VERSION "dbc-export 1 2026.26.6.5"

NS_ :

BS_:

BU_: ADSP APB APP APS APSB BB BMS CC CMP CMPD CP DAS DI DIF DIR DPB EPAS3P EPAS3S EPASTP EPASTS EPBL EPBR ESP EVSE FC GTW HCML HCMR HVP IBST ICR IDB LS OCS1P ODIN PARK PCS PCS2 PLG PM PMF PMR PNCD PTC RADC RCM RCM2 RCM3 RCU SCCM SCM SCS SDCR TAS TCU TCU2 TPMS TRCM UDS UI UIS UMC USM V2G VC VCBATT VCBATT0 VCBATT1 VCBATT2 VCCC VCFRONT VCFRONT1 VCFRONT2 VCLEFT VCRIGHT VCSEAT2L VCSEAT2R VCSEC VEH

BO_ 974 VCBATT1_alertMatrix: 8 VCBATT1
 SG_ VCBATT1_matrixIndex M : 0|4@1+ (1,0) [0|15] "" Vector__XXX
 SG_ VCBATT1_a001_WatchdogReset m0 : 4|1@1+ (1,0) [0|1] "" Vector__XXX
 SG_ VCBATT1_a002_PowerLossReset m0 : 5|1@1+ (1,0) [0|1] "" Vector__XXX
 SG_ VCBATT1_a003_SWAssertion m0 : 6|1@1+ (1,0) [0|1] "" Vector__XXX
 SG_ VCBATT1_a005_CANTXError m0 : 8|1@1+ (1,0) [0|1] "" Vector__XXX
 SG_ VCBATT1_a006_CANTX_cyclicError m0 : 9|1@1+ (1,0) [0|1] "" Vector__XXX
 SG_ VCBATT1_a012_CPUReset m0 : 15|1@1+ (1,0) [0|1] "" Vector__XXX
 SG_ VCBATT1_a013_AlertManagerFault m0 : 16|1@1+ (1,0) [0|1] "" Vector__XXX
 SG_ VCBATT1_a015_NVMMError m0 : 18|1@1+ (1,0) [0|1] "" Vector__XXX
 SG_ VCBATT1_a016_NVMMRecordError m0 : 19|1@1+ (1,0) [0|1] "" Vector__XXX
 SG_ VCBATT1_a017_NVMMStatusDbg m0 : 20|1@1+ (1,0) [0|1] "" Vector__XXX
 SG_ VCBATT1_a018_HardFault m0 : 21|1@1+ (1,0) [0|1] "" Vector__XXX
 SG_ VCBATT1_a019_BusFault m0 : 22|1@1+ (1,0) [0|1] "" Vector__XXX
 SG_ VCBATT1_a021_TaskSchedulerError m0 : 24|1@1+ (1,0) [0|1] "" Vector__XXX
 SG_ VCBATT1_a022_TaskInitError m0 : 25|1@1+ (1,0) [0|1] "" Vector__XXX
 SG_ VCBATT1_a028_UsageFault m0 : 31|1@1+ (1,0) [0|1] "" Vector__XXX
 SG_ VCBATT1_a029_CoreDump m0 : 32|1@1+ (1,0) [0|1] "" Vector__XXX
 SG_ VCBATT1_a030_ECULogUploadRequest m0 : 33|1@1+ (1,0) [0|1] "" Vector__XXX
 SG_ VCBATT1_a031_UDSActive m0 : 34|1@1+ (1,0) [0|1] "" Vector__XXX
 SG_ VCBATT1_a036_UnknownIrq m0 : 39|1@1+ (1,0) [0|1] "" Vector__XXX
 SG_ VCBATT1_a037_MemManageFault m0 : 40|1@1+ (1,0) [0|1] "" Vector__XXX
 SG_ VCBATT1_a038_ProtFaultInfo m0 : 41|1@1+ (1,0) [0|1] "" Vector__XXX
 SG_ VCBATT1_a039_ProtFaultAddress m0 : 42|1@1+ (1,0) [0|1] "" Vector__XXX
 SG_ VCBATT1_a040_Backtrace m0 : 43|1@1+ (1,0) [0|1] "" Vector__XXX
 SG_ VCBATT1_a041_HighCPULoad m0 : 44|1@1+ (1,0) [0|1] "" Vector__XXX
 SG_ VCBATT1_a042_HighStackUsage m0 : 45|1@1+ (1,0) [0|1] "" Vector__XXX
 SG_ VCBATT1_a043_Task1msError m0 : 46|1@1+ (1,0) [0|1] "" Vector__XXX
 SG_ VCBATT1_a044_Task10msError m0 : 47|1@1+ (1,0) [0|1] "" Vector__XXX
 SG_ VCBATT1_a045_Task100msError m0 : 48|1@1+ (1,0) [0|1] "" Vector__XXX
 SG_ VCBATT1_a046_Task1000msError m0 : 49|1@1+ (1,0) [0|1] "" Vector__XXX
 SG_ VCBATT1_a058_inputRHighSyncDebug m0 : 61|1@1+ (1,0) [0|1] "" Vector__XXX
 SG_ VCBATT1_a059_inputResistanceHigh m0 : 62|1@1+ (1,0) [0|1] "" Vector__XXX
 SG_ VCBATT1_a060_engineeringBuild m0 : 63|1@1+ (1,0) [0|1] "" Vector__XXX
 SG_ VCBATT1_a061_XCPConnected m1 : 4|1@1+ (1,0) [0|1] "" Vector__XXX
 SG_ VCBATT1_a062_XCPWasConnected m1 : 5|1@1+ (1,0) [0|1] "" Vector__XXX
 SG_ VCBATT1_a063_SwitchFault m1 : 6|1@1+ (1,0) [0|1] "" Vector__XXX
 SG_ VCBATT1_a064_busSleepReqTimeout m1 : 7|1@1+ (1,0) [0|1] "" Vector__XXX
 SG_ VCBATT1_a077_VCBATT0_MIA m1 : 20|1@1+ (1,0) [0|1] "" Vector__XXX
 SG_ VCBATT1_a078_VCBATT1_MIA m1 : 21|1@1+ (1,0) [0|1] "" Vector__XXX
 SG_ VCBATT1_a079_VCBATT2_MIA m1 : 22|1@1+ (1,0) [0|1] "" Vector__XXX
 SG_ VCBATT1_a080_VCFRONT0_MIA m1 : 23|1@1+ (1,0) [0|1] "" Vector__XXX
 SG_ VCBATT1_a081_VCFRONT1_MIA m1 : 24|1@1+ (1,0) [0|1] "" Vector__XXX
 SG_ VCBATT1_a082_VCFRONT2_MIA m1 : 25|1@1+ (1,0) [0|1] "" Vector__XXX
 SG_ VCBATT1_a086_VCBATT_MIA m1 : 29|1@1+ (1,0) [0|1] "" Vector__XXX
 SG_ VCBATT1_a090_APS_MIA m1 : 33|1@1+ (1,0) [0|1] "" Vector__XXX
 SG_ VCBATT1_a091_CMPD_MIA m1 : 34|1@1+ (1,0) [0|1] "" Vector__XXX
 SG_ VCBATT1_a096_OCS1P_MIA m1 : 39|1@1+ (1,0) [0|1] "" Vector__XXX
 SG_ VCBATT1_a098_DIR_MIA m1 : 41|1@1+ (1,0) [0|1] "" Vector__XXX
 SG_ VCBATT1_a100_CANbus_MIA m1 : 43|1@1+ (1,0) [0|1] "" Vector__XXX
 SG_ VCBATT1_a103_CP_MIA m1 : 46|1@1+ (1,0) [0|1] "" Vector__XXX
 SG_ VCBATT1_a104_DAS_MIA m1 : 47|1@1+ (1,0) [0|1] "" Vector__XXX
 SG_ VCBATT1_a105_TAS_MIA m1 : 48|1@1+ (1,0) [0|1] "" Vector__XXX
 SG_ VCBATT1_a106_PCS_MIA m1 : 49|1@1+ (1,0) [0|1] "" Vector__XXX
 SG_ VCBATT1_a107_BMS_MIA m1 : 50|1@1+ (1,0) [0|1] "" Vector__XXX
 SG_ VCBATT1_a108_DIF_MIA m1 : 51|1@1+ (1,0) [0|1] "" Vector__XXX
 SG_ VCBATT1_a109_RCM_MIA m1 : 52|1@1+ (1,0) [0|1] "" Vector__XXX
 SG_ VCBATT1_a110_GTW_MIA m1 : 53|1@1+ (1,0) [0|1] "" Vector__XXX
 SG_ VCBATT1_a111_EPBR_MIA m1 : 54|1@1+ (1,0) [0|1] "" Vector__XXX
 SG_ VCBATT1_a112_EPBL_MIA m1 : 55|1@1+ (1,0) [0|1] "" Vector__XXX
 SG_ VCBATT1_a113_UI_MIA m1 : 56|1@1+ (1,0) [0|1] "" Vector__XXX
 SG_ VCBATT1_a114_ESP_MIA m1 : 57|1@1+ (1,0) [0|1] "" Vector__XXX
 SG_ VCBATT1_a115_VCSEC_MIA m1 : 58|1@1+ (1,0) [0|1] "" Vector__XXX
 SG_ VCBATT1_a116_VCRIGHT_MIA m1 : 59|1@1+ (1,0) [0|1] "" Vector__XXX
 SG_ VCBATT1_a117_VCLEFT_MIA m1 : 60|1@1+ (1,0) [0|1] "" Vector__XXX
 SG_ VCBATT1_a118_VCFRONT_MIA m1 : 61|1@1+ (1,0) [0|1] "" Vector__XXX
 SG_ VCBATT1_a119_SCCM_MIA m1 : 62|1@1+ (1,0) [0|1] "" Vector__XXX
 SG_ VCBATT1_a120_DI_DRIVE_MIA m1 : 63|1@1+ (1,0) [0|1] "" Vector__XXX
 SG_ VCBATT1_a122_ICR_MIA m2 : 5|1@1+ (1,0) [0|1] "" Vector__XXX
 SG_ VCBATT1_a124_BB_MIA m2 : 7|1@1+ (1,0) [0|1] "" Vector__XXX
 SG_ VCBATT1_a125_SCCM_MIA m2 : 8|1@1+ (1,0) [0|1] "" Vector__XXX
 SG_ VCBATT1_a126_EPAS3P_MIA m2 : 9|1@1+ (1,0) [0|1] "" Vector__XXX
 SG_ VCBATT1_a127_vcleftEFuseTrip m2 : 10|1@1+ (1,0) [0|1] "" Vector__XXX
 SG_ VCBATT1_a129_epas1EFuseTrip m2 : 12|1@1+ (1,0) [0|1] "" Vector__XXX
 SG_ VCBATT1_a130_autopilot1EFuseTrip m2 : 13|1@1+ (1,0) [0|1] "" Vector__XXX
 SG_ VCBATT1_a131_PCSCOMMON_MIA m2 : 14|1@1+ (1,0) [0|1] "" Vector__XXX
 SG_ VCBATT1_a132_iBoosterEFuseTrip m2 : 15|1@1+ (1,0) [0|1] "" Vector__XXX
 SG_ VCBATT1_a133_BRAKE_MIA m2 : 16|1@1+ (1,0) [0|1] "" Vector__XXX
 SG_ VCBATT1_a134_hvContactorsEFuseTr m2 : 17|1@1+ (1,0) [0|1] "" Vector__XXX
 SG_ VCBATT1_a144_EPAS3S_MIA m2 : 27|1@1+ (1,0) [0|1] "" Vector__XXX
 SG_ VCBATT1_a164_eFuseLckoutMissing m2 : 47|1@1+ (1,0) [0|1] "" Vector__XXX
 SG_ VCBATT1_a165_unxpctdEFuseLckout m2 : 48|1@1+ (1,0) [0|1] "" Vector__XXX
 SG_ VCBATT1_a180_DCDCNotSupportingLV m2 : 63|1@1+ (1,0) [0|1] "" Vector__XXX
 SG_ VCBATT1_a182_replaceLVBattery m3 : 5|1@1+ (1,0) [0|1] "" Vector__XXX
 SG_ VCBATT1_a183_replaceLVBattery2 m3 : 6|1@1+ (1,0) [0|1] "" Vector__XXX
 SG_ VCBATT1_a188_sleepFailed m3 : 11|1@1+ (1,0) [0|1] "" Vector__XXX
 SG_ VCBATT1_a189_IBSMIA m3 : 12|1@1+ (1,0) [0|1] "" Vector__XXX
 SG_ VCBATT1_a191_exitDriveLowLVBusVo m3 : 14|1@1+ (1,0) [0|1] "" Vector__XXX
 SG_ VCBATT1_a196_discnctdLVBattery m3 : 19|1@1+ (1,0) [0|1] "" Vector__XXX
 SG_ VCBATT1_a204_undervoltageLoadshe m3 : 27|1@1+ (1,0) [0|1] "" Vector__XXX
 SG_ VCBATT1_a205_overvoltageProtecti m3 : 28|1@1+ (1,0) [0|1] "" Vector__XXX
 SG_ VCBATT1_a212_IBSOverTemp m3 : 35|1@1+ (1,0) [0|1] "" Vector__XXX
 SG_ VCBATT1_a213_LVOvercharge m3 : 36|1@1+ (1,0) [0|1] "" Vector__XXX
 SG_ VCBATT1_a215_selfTestOrchestrato m3 : 38|1@1+ (1,0) [0|1] "" Vector__XXX
 SG_ VCBATT1_a216_powerCutoffImminent m3 : 39|1@1+ (1,0) [0|1] "" Vector__XXX
 SG_ VCBATT1_a217_LVProtectionSelfTes m3 : 40|1@1+ (1,0) [0|1] "" Vector__XXX
 SG_ VCBATT1_a219_LVVoltFloorRchd m3 : 42|1@1+ (1,0) [0|1] "" Vector__XXX
 SG_ VCBATT1_a220_LVUnhealthy m3 : 43|1@1+ (1,0) [0|1] "" Vector__XXX
 SG_ VCBATT1_a221_reverseBatteryFault m3 : 44|1@1+ (1,0) [0|1] "" Vector__XXX
 SG_ VCBATT1_a223_bridgeOvervoltageSe m3 : 46|1@1+ (1,0) [0|1] "" Vector__XXX
 SG_ VCBATT1_a224_overcurrentLoadshed m3 : 47|1@1+ (1,0) [0|1] "" Vector__XXX
 SG_ VCBATT1_a225_overcurrentSelfTest m3 : 48|1@1+ (1,0) [0|1] "" Vector__XXX
 SG_ VCBATT1_a226_overcurrentSelfTest m3 : 49|1@1+ (1,0) [0|1] "" Vector__XXX
 SG_ VCBATT1_a227_overcurrentSelfTest m3 : 50|1@1+ (1,0) [0|1] "" Vector__XXX
 SG_ VCBATT1_a228_overcurrentSelfTest m3 : 51|1@1+ (1,0) [0|1] "" Vector__XXX
 SG_ VCBATT1_a229_LVHealthCompromised m3 : 52|1@1+ (1,0) [0|1] "" Vector__XXX
 SG_ VCBATT1_a230_ingoingOvercurrentS m3 : 53|1@1+ (1,0) [0|1] "" Vector__XXX
 SG_ VCBATT1_a231_autopilot1EFuseTrip m3 : 54|1@1+ (1,0) [0|1] "" Vector__XXX
 SG_ VCBATT1_a235_dualPowerLoadsSelfT m3 : 58|1@1+ (1,0) [0|1] "" Vector__XXX
 SG_ VCBATT1_a236_hvcDualPowerSelfTes m3 : 59|1@1+ (1,0) [0|1] "" Vector__XXX
 SG_ VCBATT1_a243_LVOverchargeInstc m4 : 6|1@1+ (1,0) [0|1] "" Vector__XXX
 SG_ VCBATT1_a244_brakeValveECUEFuseT m4 : 7|1@1+ (1,0) [0|1] "" Vector__XXX
 SG_ VCBATT1_a245_sleepBypassFault m4 : 8|1@1+ (1,0) [0|1] "" Vector__XXX
 SG_ VCBATT1_a252_controllerWakeup m4 : 15|1@1+ (1,0) [0|1] "" Vector__XXX
 SG_ VCBATT1_a253_maxChrgeSssionTmeou m4 : 16|1@1+ (1,0) [0|1] "" Vector__XXX
 SG_ VCBATT1_a256_nxppca9539Fault m4 : 19|1@1+ (1,0) [0|1] "" Vector__XXX
 SG_ VCBATT1_a258_resistanceEstimatio m4 : 21|1@1+ (1,0) [0|1] "" Vector__XXX
 SG_ VCBATT1_a259_LVVoltageDropOnHigh m4 : 22|1@1+ (1,0) [0|1] "" Vector__XXX
 SG_ VCBATT1_a260_deadLVBattery m4 : 23|1@1+ (1,0) [0|1] "" Vector__XXX
 SG_ VCBATT1_a275_TLVBMS_BmbCommunica m4 : 38|1@1+ (1,0) [0|1] "" Vector__XXX
 SG_ VCBATT1_a276_TLVBMS_BmbDataInteg m4 : 39|1@1+ (1,0) [0|1] "" Vector__XXX
 SG_ VCBATT1_a277_TLVBMS_BmbStatusReg m4 : 40|1@1+ (1,0) [0|1] "" Vector__XXX
 SG_ VCBATT1_a278_TLVBMS_BmbHwOverCur m4 : 41|1@1+ (1,0) [0|1] "" Vector__XXX
 SG_ VCBATT1_a297_TLVBMS_BmbHwOverTem m4 : 60|1@1+ (1,0) [0|1] "" Vector__XXX
 SG_ VCBATT1_a359_postPORExcessiveAh m5 : 62|1@1+ (1,0) [0|1] "" Vector__XXX
 SG_ VCBATT1_a362_TLVBMS_AllSocCorrec m6 : 5|1@1+ (1,0) [0|1] "" Vector__XXX
 SG_ VCBATT1_a363_TLVBMS_BleedBasedWe m6 : 6|1@1+ (1,0) [0|1] "" Vector__XXX
 SG_ VCBATT1_a370_noLVSupportSocTooLo m6 : 13|1@1+ (1,0) [0|1] "" Vector__XXX
 SG_ VCBATT1_a371_failureToPrechargeR m6 : 14|1@1+ (1,0) [0|1] "" Vector__XXX
 SG_ VCBATT1_a372_TLVBMS_BmbHwOverVol m6 : 15|1@1+ (1,0) [0|1] "" Vector__XXX
 SG_ VCBATT1_a376_controllerWakeupDeb m6 : 19|1@1+ (1,0) [0|1] "" Vector__XXX
 SG_ VCBATT1_a379_shortedCellTestRunD m6 : 22|1@1+ (1,0) [0|1] "" Vector__XXX
 SG_ VCBATT1_a387_shortedCellInstc m6 : 30|1@1+ (1,0) [0|1] "" Vector__XXX
 SG_ VCBATT1_a388_shortedCell m6 : 31|1@1+ (1,0) [0|1] "" Vector__XXX
 SG_ VCBATT1_a392_TLVBMS_BmbHwUnderVo m6 : 35|1@1+ (1,0) [0|1] "" Vector__XXX
 SG_ VCBATT1_a400_TLVBMS_BmbVrefBad m6 : 43|1@1+ (1,0) [0|1] "" Vector__XXX
 SG_ VCBATT1_a401_deadLVMinimalAhDisc m6 : 44|1@1+ (1,0) [0|1] "" Vector__XXX
 SG_ VCBATT1_a402_LVBatteryCannotSupp m6 : 45|1@1+ (1,0) [0|1] "" Vector__XXX
 SG_ VCBATT1_a403_chargeExitHardCurre m6 : 46|1@1+ (1,0) [0|1] "" Vector__XXX
 SG_ VCBATT1_a404_resistanceEstimatio m6 : 47|1@1+ (1,0) [0|1] "" Vector__XXX
 SG_ VCBATT1_a405_dcrData1 m6 : 48|1@1+ (1,0) [0|1] "" Vector__XXX
 SG_ VCBATT1_a406_dcrData2 m6 : 49|1@1+ (1,0) [0|1] "" Vector__XXX
 SG_ VCBATT1_a407_dcrMilliOhmsAboveTh m6 : 50|1@1+ (1,0) [0|1] "" Vector__XXX
 SG_ VCBATT1_a408_standbyChargeProfil m6 : 51|1@1+ (1,0) [0|1] "" Vector__XXX
 SG_ VCBATT1_a410_LVBatteryDataCollec m6 : 53|1@1+ (1,0) [0|1] "" Vector__XXX
 SG_ VCBATT1_a411_LVBatteryDataCollec m6 : 54|1@1+ (1,0) [0|1] "" Vector__XXX
 SG_ VCBATT1_a412_dcrData3 m6 : 55|1@1+ (1,0) [0|1] "" Vector__XXX
 SG_ VCBATT1_a413_TLVBMS_BmbVrefWarni m6 : 56|1@1+ (1,0) [0|1] "" Vector__XXX
 SG_ VCBATT1_a414_undervoltageSelfTes m6 : 57|1@1+ (1,0) [0|1] "" Vector__XXX
 SG_ VCBATT1_a415_undervoltageSelfTes m6 : 58|1@1+ (1,0) [0|1] "" Vector__XXX
 SG_ VCBATT1_a416_TLVBMS_BrickOverDis m6 : 59|1@1+ (1,0) [0|1] "" Vector__XXX
 SG_ VCBATT1_a417_TLVBMS_BrickOverVol m6 : 60|1@1+ (1,0) [0|1] "" Vector__XXX
 SG_ VCBATT1_a418_TLVBMS_BrickOverVol m6 : 61|1@1+ (1,0) [0|1] "" Vector__XXX
 SG_ VCBATT1_a419_TLVBMS_BrickSocLow m6 : 62|1@1+ (1,0) [0|1] "" Vector__XXX
 SG_ VCBATT1_a421_LVBatteryHealthTest m7 : 4|1@1+ (1,0) [0|1] "" Vector__XXX
 SG_ VCBATT1_a422_rtosSleepFailed m7 : 5|1@1+ (1,0) [0|1] "" Vector__XXX
 SG_ VCBATT1_a423_TLVBMS_BrickUnderVo m7 : 6|1@1+ (1,0) [0|1] "" Vector__XXX
 SG_ VCBATT1_a424_TLVBMS_BrickUnderVo m7 : 7|1@1+ (1,0) [0|1] "" Vector__XXX
 SG_ VCBATT1_a425_TLVBMS_BusVoltageTo m7 : 8|1@1+ (1,0) [0|1] "" Vector__XXX
 SG_ VCBATT1_a426_TLVBMS_BusVoltageTo m7 : 9|1@1+ (1,0) [0|1] "" Vector__XXX
 SG_ VCBATT1_a427_TLVBMS_CacChange m7 : 10|1@1+ (1,0) [0|1] "" Vector__XXX
 SG_ VCBATT1_a428_TLVBMS_CacImbalance m7 : 11|1@1+ (1,0) [0|1] "" Vector__XXX
 SG_ VCBATT1_a429_TLVBMS_CapacityTest m7 : 12|1@1+ (1,0) [0|1] "" Vector__XXX
 SG_ VCBATT1_a430_TLVBMS_ChargeCurren m7 : 13|1@1+ (1,0) [0|1] "" Vector__XXX
 SG_ VCBATT1_a431_TLVBMS_ChargeOverCu m7 : 14|1@1+ (1,0) [0|1] "" Vector__XXX
 SG_ VCBATT1_a432_TLVBMS_ChargeRegula m7 : 15|1@1+ (1,0) [0|1] "" Vector__XXX
 SG_ VCBATT1_a433_TLVBMS_ConfigFromBm m7 : 16|1@1+ (1,0) [0|1] "" Vector__XXX
 SG_ VCBATT1_a434_TLVBMS_ConfigInitFa m7 : 17|1@1+ (1,0) [0|1] "" Vector__XXX
 SG_ VCBATT1_a435_TLVBMS_DchgCurrentL m7 : 18|1@1+ (1,0) [0|1] "" Vector__XXX
 SG_ VCBATT1_a436_TLVBMS_DischargeOve m7 : 19|1@1+ (1,0) [0|1] "" Vector__XXX
 SG_ VCBATT1_a437_TLVBMS_NvmRegistrat m7 : 20|1@1+ (1,0) [0|1] "" Vector__XXX
 SG_ VCBATT1_a438_TLVBMS_PackOverTemp m7 : 21|1@1+ (1,0) [0|1] "" Vector__XXX
 SG_ VCBATT1_a439_TLVBMS_PackOverTemp m7 : 22|1@1+ (1,0) [0|1] "" Vector__XXX
 SG_ VCBATT1_a440_TLVBMS_PackSNInvali m7 : 23|1@1+ (1,0) [0|1] "" Vector__XXX
 SG_ VCBATT1_a441_TLVBMS_ResetNeededF m7 : 24|1@1+ (1,0) [0|1] "" Vector__XXX
 SG_ VCBATT1_a442_TLVBMS_SocChange m7 : 25|1@1+ (1,0) [0|1] "" Vector__XXX
 SG_ VCBATT1_a443_TLVBMS_BmbDieOverTe m7 : 26|1@1+ (1,0) [0|1] "" Vector__XXX
 SG_ VCBATT1_a446_LVBatteryUnrecovera m7 : 29|1@1+ (1,0) [0|1] "" Vector__XXX
 SG_ VCBATT1_a450_doorWakeToOpenDBG m7 : 33|1@1+ (1,0) [0|1] "" Vector__XXX
 SG_ VCBATT1_a461_TLVBMS_SocHighAhErr m7 : 44|1@1+ (1,0) [0|1] "" Vector__XXX
 SG_ VCBATT1_a462_LVBMSFault m7 : 45|1@1+ (1,0) [0|1] "" Vector__XXX
 SG_ VCBATT1_a475_vnf1248Fault m7 : 58|1@1+ (1,0) [0|1] "" Vector__XXX
 SG_ VCBATT1_a476_LVBMSMIA m7 : 59|1@1+ (1,0) [0|1] "" Vector__XXX
 SG_ VCBATT1_a477_LVBatteryUnrecovera m7 : 60|1@1+ (1,0) [0|1] "" Vector__XXX
 SG_ VCBATT1_a478_LVBMS_MOSFET_Open m7 : 61|1@1+ (1,0) [0|1] "" Vector__XXX
 SG_ VCBATT1_a479_LVBMS_ECPA_NotClose m7 : 62|1@1+ (1,0) [0|1] "" Vector__XXX
 SG_ VCBATT1_a480_vnf1048Fault m7 : 63|1@1+ (1,0) [0|1] "" Vector__XXX
 SG_ VCBATT1_a481_LVBridgeCloseDBG m8 : 4|1@1+ (1,0) [0|1] "" Vector__XXX
 SG_ VCBATT1_a482_lvBridgeEFuseTrip m8 : 5|1@1+ (1,0) [0|1] "" Vector__XXX
 SG_ VCBATT1_a483_vnf1048SelfTestFail m8 : 6|1@1+ (1,0) [0|1] "" Vector__XXX
 SG_ VCBATT1_a484_undervoltageSelfTes m8 : 7|1@1+ (1,0) [0|1] "" Vector__XXX
 SG_ VCBATT1_a485_uvSelfTestLoadUnatt m8 : 8|1@1+ (1,0) [0|1] "" Vector__XXX
 SG_ VCBATT1_a486_undervoltageSelfTes m8 : 9|1@1+ (1,0) [0|1] "" Vector__XXX
 SG_ VCBATT1_a489_vnf1248SelfTestDebu m8 : 12|1@1+ (1,0) [0|1] "" Vector__XXX
 SG_ VCBATT1_a490_vnf1248SelfTestFail m8 : 13|1@1+ (1,0) [0|1] "" Vector__XXX
 SG_ VCBATT1_a491_vnf1248Configuratio m8 : 14|1@1+ (1,0) [0|1] "" Vector__XXX
 SG_ VCBATT1_a492_TLVBMS_SocImbalance m8 : 15|1@1+ (1,0) [0|1] "" Vector__XXX
 SG_ VCBATT1_a493_TLVBMS_SocImbalance m8 : 16|1@1+ (1,0) [0|1] "" Vector__XXX
 SG_ VCBATT1_a494_LVBatteryTempBlocki m8 : 17|1@1+ (1,0) [0|1] "" Vector__XXX
 SG_ VCBATT1_a495_LVBatteryRecoveryBl m8 : 18|1@1+ (1,0) [0|1] "" Vector__XXX
 SG_ VCBATT1_a496_LVBatteryExitDriveW m8 : 19|1@1+ (1,0) [0|1] "" Vector__XXX
 SG_ VCBATT1_a497_LVBatteryWarnDiscon m8 : 20|1@1+ (1,0) [0|1] "" Vector__XXX
 SG_ VCBATT1_a498_TLVBMS_ImpedanceTes m8 : 21|1@1+ (1,0) [0|1] "" Vector__XXX
 SG_ VCBATT1_a500_eFuseASICStateMisma m8 : 23|1@1+ (1,0) [0|1] "" Vector__XXX
 SG_ VCBATT1_a501_vnf1048Configuratio m8 : 24|1@1+ (1,0) [0|1] "" Vector__XXX
 SG_ VCBATT1_a502_TLVBMS_WeakShortImp m8 : 25|1@1+ (1,0) [0|1] "" Vector__XXX
 SG_ VCBATT1_a503_TLVBMS_BrickExtende m8 : 26|1@1+ (1,0) [0|1] "" Vector__XXX
 SG_ VCBATT1_a508_TLVBMS_ImpedanceGro m8 : 31|1@1+ (1,0) [0|1] "" Vector__XXX
 SG_ VCBATT1_a509_eFuseASICManagerSta m8 : 32|1@1+ (1,0) [0|1] "" Vector__XXX
 SG_ VCBATT1_a510_LVBatteryRecoveryTi m8 : 33|1@1+ (1,0) [0|1] "" Vector__XXX
 SG_ VCBATT1_a512_LVBMSFault_MOS_Open m8 : 35|1@1+ (1,0) [0|1] "" Vector__XXX
 SG_ VCBATT1_a513_LVBMSFault_MOS_Open m8 : 36|1@1+ (1,0) [0|1] "" Vector__XXX
 SG_ VCBATT1_a514_LVBMSFault_MOS_Open m8 : 37|1@1+ (1,0) [0|1] "" Vector__XXX
 SG_ VCBATT1_a515_LVBMSFault_MOS_Open m8 : 38|1@1+ (1,0) [0|1] "" Vector__XXX
 SG_ VCBATT1_a518_LVBMSFault_MOS_Open m8 : 41|1@1+ (1,0) [0|1] "" Vector__XXX
 SG_ VCBATT1_a521_vcleftEFuseLoadShed m8 : 44|1@1+ (1,0) [0|1] "" Vector__XXX
 SG_ VCBATT1_a523_eFuseThresholdsInco m8 : 46|1@1+ (1,0) [0|1] "" Vector__XXX
 SG_ VCBATT1_a525_LVBatterySWMisconfi m8 : 48|1@1+ (1,0) [0|1] "" Vector__XXX
 SG_ VCBATT1_a527_LVBatteryCellImbala m8 : 50|1@1+ (1,0) [0|1] "" Vector__XXX
 SG_ VCBATT1_a528_LVBatteryCommsDiscn m8 : 51|1@1+ (1,0) [0|1] "" Vector__XXX
 SG_ VCBATT1_a529_discnctdBatteryStat m8 : 52|1@1+ (1,0) [0|1] "" Vector__XXX
 SG_ VCBATT1_a533_TLVBMS_MosfetOverTe m8 : 56|1@1+ (1,0) [0|1] "" Vector__XXX
 SG_ VCBATT1_a541_LVBatteryChargeOCLe m9 : 4|1@1+ (1,0) [0|1] "" Vector__XXX
 SG_ VCBATT1_a544_LVBatteryCommsBusTu m9 : 7|1@1+ (1,0) [0|1] "" Vector__XXX
 SG_ VCBATT1_a545_LVBatteryTypeUnknow m9 : 8|1@1+ (1,0) [0|1] "" Vector__XXX
 SG_ VCBATT1_a548_HVFaultLoadShed m9 : 11|1@1+ (1,0) [0|1] "" Vector__XXX
 SG_ VCBATT1_a555_LVBatteryCellRebala m9 : 18|1@1+ (1,0) [0|1] "" Vector__XXX
 SG_ VCBATT1_a556_falseTriggerOfDiscn m9 : 19|1@1+ (1,0) [0|1] "" Vector__XXX
 SG_ VCBATT1_a559_LVBatteryLowSOC m9 : 22|1@1+ (1,0) [0|1] "" Vector__XXX
 SG_ VCBATT1_a561_LVBMSEFuseOvertempe m9 : 24|1@1+ (1,0) [0|1] "" Vector__XXX
 SG_ VCBATT1_a562_LVBMSModuleOvertemp m9 : 25|1@1+ (1,0) [0|1] "" Vector__XXX
 SG_ VCBATT1_a573_radarEFuseTrip m9 : 36|1@1+ (1,0) [0|1] "" Vector__XXX
 SG_ VCBATT1_a575_vbatFusedLoadShedEF m9 : 38|1@1+ (1,0) [0|1] "" Vector__XXX
 SG_ VCBATT1_a576_mcuLogicEFuseTrip m9 : 39|1@1+ (1,0) [0|1] "" Vector__XXX
 SG_ VCBATT1_a580_rightHeadlightEFuse m9 : 43|1@1+ (1,0) [0|1] "" Vector__XXX
 SG_ VCBATT1_a581_harnessResistanceIn m9 : 44|1@1+ (1,0) [0|1] "" Vector__XXX
 SG_ VCBATT1_a582_goodForPCSPowerCycl m9 : 45|1@1+ (1,0) [0|1] "" Vector__XXX
 SG_ VCBATT1_a585_lvBatteryHealthTest m9 : 48|1@1+ (1,0) [0|1] "" Vector__XXX
 SG_ VCBATT1_a587_externalLVPowerSupp m9 : 50|1@1+ (1,0) [0|1] "" Vector__XXX
 SG_ VCBATT1_a588_vcleftPwrRationalit m9 : 51|1@1+ (1,0) [0|1] "" Vector__XXX
 SG_ VCBATT1_a589_vcleftFastBlowDetec m9 : 52|1@1+ (1,0) [0|1] "" Vector__XXX
 SG_ VCBATT1_a592_vcleftCurvePowerCut m9 : 55|1@1+ (1,0) [0|1] "" Vector__XXX
 SG_ VCBATT1_a593_vcleftFastBlowPower m9 : 56|1@1+ (1,0) [0|1] "" Vector__XXX
 SG_ VCBATT1_a595_voltageSensorMismat m9 : 58|1@1+ (1,0) [0|1] "" Vector__XXX
 SG_ VCBATT1_a597_LVBMBeFuseSelfTestN m9 : 60|1@1+ (1,0) [0|1] "" Vector__XXX
 SG_ VCBATT1_a598_LVBMBeFuseSelfTestF m9 : 61|1@1+ (1,0) [0|1] "" Vector__XXX
 SG_ VCBATT1_a599_LVBatteryTypeUnsupp m9 : 62|1@1+ (1,0) [0|1] "" Vector__XXX
 SG_ VCBATT1_a600_currentSensorMismat m9 : 63|1@1+ (1,0) [0|1] "" Vector__XXX
 SG_ VCBATT1_a601_LVBatteryHeaterNotP m10 : 4|1@1+ (1,0) [0|1] "" Vector__XXX
 SG_ VCBATT1_a608_TLVBMS_BleedFetFail m10 : 11|1@1+ (1,0) [0|1] "" Vector__XXX
 SG_ VCBATT1_a615_TLVBMS_BatteryHeate m10 : 18|1@1+ (1,0) [0|1] "" Vector__XXX
 SG_ VCBATT1_a617_APP_MIA m10 : 20|1@1+ (1,0) [0|1] "" Vector__XXX
 SG_ VCBATT1_a628_TLVBMS_BmbThermisto m10 : 31|1@1+ (1,0) [0|1] "" Vector__XXX
 SG_ VCBATT1_a629_TLVBMS_PackTemperat m10 : 32|1@1+ (1,0) [0|1] "" Vector__XXX
 SG_ VCBATT1_a670_TLVBMS_EfuseStateIr m11 : 13|1@1+ (1,0) [0|1] "" Vector__XXX
 SG_ VCBATT1_a672_LVBatteryVitals m11 : 15|1@1+ (1,0) [0|1] "" Vector__XXX

BO_ 1030 VCBATT1_eFuseDebugStatus: 7 VCBATT1
 SG_ VCBATT1_eFuseDebugStatusIndex M : 0|3@1+ (1,0) [0|7] "" Vector__XXX
 SG_ VCBATT1_leftControllerEFuseState m0 : 3|3@1+ (1,0) [0|7] "" Vector__XXX
 SG_ VCBATT1_leftControllerEFuseCurre m0 : 8|12@1+ (0.05,0) [0|204.75] "A" Vector__XXX
 SG_ VCBATT1_leftControllerEFuseOutpu m0 : 20|1@1+ (1,0) [0|1] "" Vector__XXX
 SG_ VCBATT1_leftControllerEFuse_0002 m0 : 21|1@1+ (1,0) [0|1] "" Vector__XXX
 SG_ VCBATT1_leftControllerEFuseBypas m0 : 22|1@1+ (1,0) [0|1] "" Vector__XXX
 SG_ VCBATT1_leftControllerEFuse_0001 m0 : 23|1@1+ (1,0) [0|1] "" Vector__XXX
 SG_ VCBATT1_leftControllerEFuseVolta m0 : 24|8@1+ (0.07,0) [0|17.85] "V" Vector__XXX
 SG_ VCBATT1_leftControllerEFuseTempe m0 : 32|8@1+ (1,-40) [-40|150] "degC" Vector__XXX
 SG_ VCBATT1_leftControllerEFuseManag m0 : 40|4@1+ (1,0) [0|15] "" Vector__XXX
 SG_ VCBATT1_leftControllerEFuseHardS m0 : 44|4@1+ (1,0) [0|15] "" Vector__XXX
 SG_ VCBATT1_leftControllerEFuseOCThr m0 : 48|5@1+ (1,0) [0|31] "" Vector__XXX
 SG_ VCBATT1_leftControllerEFuseType m0 : 53|2@1+ (1,0) [0|3] "" Vector__XXX
 SG_ VCBATT1_EPAS1EFuseState m1 : 3|3@1+ (1,0) [0|7] "" Vector__XXX
 SG_ VCBATT1_EPAS1EFuseCurrent m1 : 8|12@1+ (0.05,0) [0|204.75] "A" Vector__XXX
 SG_ VCBATT1_EPAS1EFuseOutput m1 : 20|1@1+ (1,0) [0|1] "" Vector__XXX
 SG_ VCBATT1_EPAS1EFuseOutputDesired m1 : 21|1@1+ (1,0) [0|1] "" Vector__XXX
 SG_ VCBATT1_EPAS1EFuseBypass m1 : 22|1@1+ (1,0) [0|1] "" Vector__XXX
 SG_ VCBATT1_EPAS1EFuseBypassDesired m1 : 23|1@1+ (1,0) [0|1] "" Vector__XXX
 SG_ VCBATT1_EPAS1EFuseVoltage m1 : 24|8@1+ (0.07,0) [0|17.85] "V" Vector__XXX
 SG_ VCBATT1_EPAS1EFuseTemperature m1 : 32|8@1+ (1,-40) [-40|150] "degC" Vector__XXX
 SG_ VCBATT1_EPAS1EFuseManagerState m1 : 40|4@1+ (1,0) [0|15] "" Vector__XXX
 SG_ VCBATT1_EPAS1EFuseHardShortThres m1 : 44|4@1+ (1,0) [0|15] "" Vector__XXX
 SG_ VCBATT1_EPAS1EFuseOCThreshold m1 : 48|5@1+ (1,0) [0|31] "" Vector__XXX
 SG_ VCBATT1_EPAS1EFuseType m1 : 53|2@1+ (1,0) [0|3] "" Vector__XXX
 SG_ VCBATT1_autopilot1EFuseState m3 : 3|3@1+ (1,0) [0|7] "" Vector__XXX
 SG_ VCBATT1_autopilot1EFuseCurrent m3 : 8|12@1+ (0.05,0) [0|204.75] "A" Vector__XXX
 SG_ VCBATT1_autopilot1EFuseOutput m3 : 20|1@1+ (1,0) [0|1] "" Vector__XXX
 SG_ VCBATT1_autopilot1EFuseOutputDes m3 : 21|1@1+ (1,0) [0|1] "" Vector__XXX
 SG_ VCBATT1_autopilot1EFuseBypass m3 : 22|1@1+ (1,0) [0|1] "" Vector__XXX
 SG_ VCBATT1_autopilot1EFuseBypassDes m3 : 23|1@1+ (1,0) [0|1] "" Vector__XXX
 SG_ VCBATT1_autopilot1EFuseVoltage m3 : 24|8@1+ (0.07,0) [0|17.85] "V" Vector__XXX
 SG_ VCBATT1_autopilot1EFuseTemperatu m3 : 32|8@1+ (1,-40) [-40|150] "degC" Vector__XXX
 SG_ VCBATT1_autopilot1EFuseManagerSt m3 : 40|4@1+ (1,0) [0|15] "" Vector__XXX
 SG_ VCBATT1_autopilot1EFuseHardShort m3 : 44|4@1+ (1,0) [0|15] "" Vector__XXX
 SG_ VCBATT1_autopilot1EFuseOCThresho m3 : 48|5@1+ (1,0) [0|31] "" Vector__XXX
 SG_ VCBATT1_autopilot1EFuseType m3 : 53|2@1+ (1,0) [0|3] "" Vector__XXX

BO_ 1549 VCBATT1_udsResponse: 8 VCBATT1
 SG_ VCBATT1_udsResponseData : 7|64@0+ (1,0) [0|1.84467440737e+19] "" Vector__XXX

BO_ 1358 VCBATT2_alertLog: 8 VCBATT2
 SG_ VCBATT2_alertID M : 0|10@1+ (1,0) [0|1023] "" Vector__XXX
 SG_ VCBATT2_alertState : 15|1@1+ (1,0) [0|1] "" Vector__XXX
 SG_ VCBATT2_a001_InternalWatchdog m1 : 16|1@1+ (1,0) [0|1] "" Vector__XXX
 SG_ VCBATT2_a015_NVMMMemOverflow m15 : 16|1@1+ (1,0) [0|1] "" Vector__XXX
 SG_ VCBATT2_a015_NVMMFilesystemError m15 : 17|1@1+ (1,0) [0|1] "" Vector__XXX
 SG_ VCBATT2_a015_NVMMRecordIDError m15 : 18|1@1+ (1,0) [0|1] "" Vector__XXX
 SG_ VCBATT2_a059_voltageDrop m59 : 16|12@1+ (0.005443676,0) [0|22.29185322] "V" Vector__XXX
 SG_ VCBATT2_a059_resistanceEstimate m59 : 28|12@1+ (0.00244,0) [0|9.9918] "Ohms" Vector__XXX
 SG_ VCBATT2_a059_current m59 : 40|12@1+ (0.05,0) [0|204.75] "A" Vector__XXX
 SG_ VCBATT2_a063_switchChannel m63 : 16|8@1+ (1,0) [0|255] "" Vector__XXX
 SG_ VCBATT2_a063_switchType m63 : 24|8@1+ (1,0) [0|255] "" Vector__XXX
 SG_ VCBATT2_a063_ADCVoltage m63 : 32|8@1+ (0.025,0) [0|6.375] "V" Vector__XXX
 SG_ VCBATT2_a063_disconnected m63 : 40|1@1+ (1,0) [0|1] "" Vector__XXX
 SG_ VCBATT2_a063_indeterminate m63 : 41|1@1+ (1,0) [0|1] "" Vector__XXX
 SG_ VCBATT2_a063_stuckActive m63 : 42|1@1+ (1,0) [0|1] "" Vector__XXX
 SG_ VCBATT2_a063_faulted m63 : 43|1@1+ (1,0) [0|1] "" Vector__XXX
 SG_ VCBATT2_a091_FRONTIPC_faultsAndE m91 : 16|1@1+ (1,0) [0|1] "" Vector__XXX
 SG_ VCBATT2_a091_FRONTIPC_state m91 : 17|1@1+ (1,0) [0|1] "" Vector__XXX
 SG_ VCBATT2_a096_FRONTIPC_status m96 : 16|1@1+ (1,0) [0|1] "" Vector__XXX
 SG_ VCBATT2_a098_FRONTIPC_temperatur m98 : 16|1@1+ (1,0) [0|1] "" Vector__XXX
 SG_ VCBATT2_a098_FRONTIPC_thermalCon m98 : 17|1@1+ (1,0) [0|1] "" Vector__XXX
 SG_ VCBATT2_a106_BATTIPC_dcdcRailSta m106 : 16|1@1+ (1,0) [0|1] "" Vector__XXX
 SG_ VCBATT2_a106_BATTIPC_dcdcStatus m106 : 17|1@1+ (1,0) [0|1] "" Vector__XXX
 SG_ VCBATT2_a106_VEH_dcdcStatus m106 : 18|1@1+ (1,0) [0|1] "" Vector__XXX
 SG_ VCBATT2_a106_VEH_thermalControl m106 : 19|1@1+ (1,0) [0|1] "" Vector__XXX
 SG_ VCBATT2_a106_VEH_dcdcRailStatus m106 : 20|1@1+ (1,0) [0|1] "" Vector__XXX
 SG_ VCBATT2_a106_CH_dcdcRailStatus m106 : 21|1@1+ (1,0) [0|1] "" Vector__XXX
 SG_ VCBATT2_a106_CH_alertMatrix m106 : 22|1@1+ (1,0) [0|1] "" Vector__XXX
 SG_ VCBATT2_a106_FRONTIPC_thermalCon m106 : 23|1@1+ (1,0) [0|1] "" Vector__XXX
 SG_ VCBATT2_a106_FRONTIPC_dcdcRailSt m106 : 24|1@1+ (1,0) [0|1] "" Vector__XXX
 SG_ VCBATT2_a106_FRONTIPC_dcdcStatus m106 : 25|1@1+ (1,0) [0|1] "" Vector__XXX
 SG_ VCBATT2_a108_FRONTIPC_status m108 : 16|1@1+ (1,0) [0|1] "" Vector__XXX
 SG_ VCBATT2_a108_FRONTIPC_temperatur m108 : 17|1@1+ (1,0) [0|1] "" Vector__XXX
 SG_ VCBATT2_a108_FRONTIPC_thermalCon m108 : 18|1@1+ (1,0) [0|1] "" Vector__XXX
 SG_ VCBATT2_a108_FRONTIPC_motorStatu m108 : 19|1@1+ (1,0) [0|1] "" Vector__XXX
 SG_ VCBATT2_a120_BATTIPC_speed m120 : 16|1@1+ (1,0) [0|1] "" Vector__XXX
 SG_ VCBATT2_a120_FRONTIPC_speed m120 : 17|1@1+ (1,0) [0|1] "" Vector__XXX
 SG_ VCBATT2_a120_FRONTIPC_systemStat m120 : 18|1@1+ (1,0) [0|1] "" Vector__XXX
 SG_ VCBATT2_a120_BATTIPC_systemStatu m120 : 19|1@1+ (1,0) [0|1] "" Vector__XXX
 SG_ VCBATT2_a120_FRONTIPC_systemPowe m120 : 20|1@1+ (1,0) [0|1] "" Vector__XXX
 SG_ VCBATT2_a120_FRONTIPC_autonomyHe m120 : 21|1@1+ (1,0) [0|1] "" Vector__XXX
 SG_ VCBATT2_a120_BATTIPC_chassisCont m120 : 22|1@1+ (1,0) [0|1] "" Vector__XXX
 SG_ VCBATT2_a120_FRONTIPC_chassisCon m120 : 23|1@1+ (1,0) [0|1] "" Vector__XXX
 SG_ VCBATT2_a120_FRONTIPC_odometerSt m120 : 24|1@1+ (1,0) [0|1] "" Vector__XXX
 SG_ VCBATT2_a124_FRONTIPC_status m124 : 16|1@1+ (1,0) [0|1] "" Vector__XXX
 SG_ VCBATT2_a124_BATTIPC_status m124 : 17|1@1+ (1,0) [0|1] "" Vector__XXX
 SG_ VCBATT2_a125_FRONTIPC_leftStalk m125 : 16|1@1+ (1,0) [0|1] "" Vector__XXX
 SG_ VCBATT2_a125_FRONTIPC_steerAngle m125 : 17|1@1+ (1,0) [0|1] "" Vector__XXX
 SG_ VCBATT2_a125_FRONTIPC_info m125 : 18|1@1+ (1,0) [0|1] "" Vector__XXX
 SG_ VCBATT2_a126_FRONTIPC_sysStatus m126 : 16|1@1+ (1,0) [0|1] "" Vector__XXX
 SG_ VCBATT2_a126_BATTIPC_sysStatus m126 : 17|1@1+ (1,0) [0|1] "" Vector__XXX
 SG_ VCBATT2_a126_FRONTIPC_status m126 : 18|1@1+ (1,0) [0|1] "" Vector__XXX
 SG_ VCBATT2_a126_BATTIPC_status m126 : 19|1@1+ (1,0) [0|1] "" Vector__XXX
 SG_ VCBATT2_a131_FRONTIPC_power m131 : 16|1@1+ (1,0) [0|1] "" Vector__XXX
 SG_ VCBATT2_a131_BATTIPC_power m131 : 17|1@1+ (1,0) [0|1] "" Vector__XXX
 SG_ VCBATT2_a133_BATTIPC_primaryActu m133 : 16|1@1+ (1,0) [0|1] "" Vector__XXX
 SG_ VCBATT2_a133_FRONTIPC_secondaryA m133 : 17|1@1+ (1,0) [0|1] "" Vector__XXX
 SG_ VCBATT2_a144_FRONTIPC_status m144 : 16|1@1+ (1,0) [0|1] "" Vector__XXX
 SG_ VCBATT2_a144_BATTIPC_status m144 : 17|1@1+ (1,0) [0|1] "" Vector__XXX
 SG_ VCBATT2_a156_motorCounts m156 : 16|11@1+ (1,-100) [-100|1947] "ticks" Vector__XXX
 SG_ VCBATT2_a157_motorCounts m157 : 16|11@1+ (1,-100) [-100|1947] "ticks" Vector__XXX
 SG_ VCBATT2_a181_vehicleState m181 : 16|2@1+ (1,0) [0|3] "" Vector__XXX
 SG_ VCBATT2_a188_sleepBypassCurrent m188 : 16|8@1+ (0.2,0) [0|51] "A" Vector__XXX
 SG_ VCBATT2_a188_sleepShutdownStep m188 : 24|2@1+ (1,0) [0|2] "" Vector__XXX
 SG_ VCBATT2_a188_vehiclePowerState m188 : 26|5@1+ (1,0) [0|31] "" Vector__XXX
 SG_ VCBATT2_a188_timeNotSleeping m188 : 32|6@1+ (1,0) [0|63] "sec" Vector__XXX
 SG_ VCBATT2_a188_CANAfterQuiet m188 : 38|1@1+ (1,0) [0|1] "" Vector__XXX
 SG_ VCBATT2_a192_vehiclePowerState m192 : 16|2@1+ (1,0) [0|3] "" Vector__XXX
 SG_ VCBATT2_a192_hvState m192 : 18|3@1+ (1,0) [0|7] "" Vector__XXX
 SG_ VCBATT2_a192_notEnoughPowerForSu m192 : 21|1@1+ (1,0) [0|1] "" Vector__XXX
 SG_ VCBATT2_a192_pcsEFuseStable m192 : 22|1@1+ (1,0) [0|1] "" Vector__XXX
 SG_ VCBATT2_a192_vcrightEFuseStable m192 : 23|1@1+ (1,0) [0|1] "" Vector__XXX
 SG_ VCBATT2_a192_contactorEFuseStabl m192 : 24|1@1+ (1,0) [0|1] "" Vector__XXX
 SG_ VCBATT2_a192_hvcEFuseStable m192 : 25|1@1+ (1,0) [0|1] "" Vector__XXX
 SG_ VCBATT2_a192_replaceLVBattery m192 : 26|1@1+ (1,0) [0|1] "" Vector__XXX
 SG_ VCBATT2_a192_BMS_MIA m192 : 27|1@1+ (1,0) [0|1] "" Vector__XXX
 SG_ VCBATT2_a192_PCS_MIA m192 : 28|1@1+ (1,0) [0|1] "" Vector__XXX
 SG_ VCBATT2_a192_HVBlockingMismatch m192 : 29|1@1+ (1,0) [0|1] "" Vector__XXX
 SG_ VCBATT2_a192_disconnected12V m192 : 30|1@1+ (1,0) [0|1] "" Vector__XXX
 SG_ VCBATT2_a192_LVBatteryCannotSupp m192 : 31|1@1+ (1,0) [0|1] "" Vector__XXX
 SG_ VCBATT2_a192_DI_gear m192 : 32|3@1+ (1,0) [0|6] "" Vector__XXX
 SG_ VCBATT2_a192_GTW_factoryGated m192 : 35|1@1+ (1,0) [0|1] "" Vector__XXX
 SG_ VCBATT2_a192_GTW_updateStarted m192 : 36|1@1+ (1,0) [0|1] "" Vector__XXX
 SG_ VCBATT2_a192_serviceMode m192 : 37|1@1+ (1,0) [0|1] "" Vector__XXX
 SG_ VCBATT2_a192_frunkOpen m192 : 38|1@1+ (1,0) [0|1] "" Vector__XXX
 SG_ VCBATT2_a192_IBSCurrent m192 : 40|8@1+ (0.5,-63) [-63|64.5] "A" Vector__XXX
 SG_ VCBATT2_a192_PCSCurrent m192 : 48|8@1+ (0.5,-127) [-127|0.5] "A" Vector__XXX
 SG_ VCBATT2_a192_HVFaultLoadShedActi m192 : 56|1@1+ (1,0) [0|1] "" Vector__XXX
 SG_ VCBATT2_a192_postCrashLoadShedAc m192 : 57|1@1+ (1,0) [0|1] "" Vector__XXX
 SG_ VCBATT2_a227_motorFaulted m227 : 16|1@1+ (1,0) [0|1] "" Vector__XXX
 SG_ VCBATT2_a227_motorLocked m227 : 17|1@1+ (1,0) [0|1] "" Vector__XXX
 SG_ VCBATT2_a227_ecuReset m227 : 18|1@1+ (1,0) [0|1] "" Vector__XXX
 SG_ VCBATT2_a227_fetTempIrrational m227 : 19|1@1+ (1,0) [0|1] "" Vector__XXX
 SG_ VCBATT2_a227_motorControlError m227 : 20|1@1+ (1,0) [0|1] "" Vector__XXX
 SG_ VCBATT2_a227_underVoltage m227 : 21|1@1+ (1,0) [0|1] "" Vector__XXX
 SG_ VCBATT2_a227_overVoltage m227 : 22|1@1+ (1,0) [0|1] "" Vector__XXX
 SG_ VCBATT2_a227_hardwareOvercurrent m227 : 23|1@1+ (1,0) [0|1] "" Vector__XXX
 SG_ VCBATT2_a227_motorOpenPhase m227 : 24|1@1+ (1,0) [0|1] "" Vector__XXX
 SG_ VCBATT2_a227_motorSoftOpenPhase m227 : 25|1@1+ (1,0) [0|1] "" Vector__XXX
 SG_ VCBATT2_a227_motorOvertemp m227 : 26|1@1+ (1,0) [0|1] "" Vector__XXX
 SG_ VCBATT2_a227_dcOvercurrent m227 : 27|1@1+ (1,0) [0|1] "" Vector__XXX
 SG_ VCBATT2_a227_motorStalled m227 : 28|1@1+ (1,0) [0|1] "" Vector__XXX
 SG_ VCBATT2_a227_selfTestFailed m227 : 29|1@1+ (1,0) [0|1] "" Vector__XXX
 SG_ VCBATT2_a227_selfTestResult m227 : 32|3@1+ (1,0) [0|7] "" Vector__XXX
 SG_ VCBATT2_a227_linChecksumError m227 : 35|1@1+ (1,0) [0|1] "" Vector__XXX
 SG_ VCBATT2_a227_linFramingError m227 : 36|1@1+ (1,0) [0|1] "" Vector__XXX
 SG_ VCBATT2_a227_phaseShorted m227 : 37|1@1+ (1,0) [0|1] "" Vector__XXX
 SG_ VCBATT2_a227_busVoltageIrrationa m227 : 38|1@1+ (1,0) [0|1] "" Vector__XXX
 SG_ VCBATT2_a227_dcCurrentIrrational m227 : 39|1@1+ (1,0) [0|1] "" Vector__XXX
 SG_ VCBATT2_a227_motorSpeedIrrationa m227 : 40|1@1+ (1,0) [0|1] "" Vector__XXX
 SG_ VCBATT2_a227_supplyVoltageIrrati m227 : 41|1@1+ (1,0) [0|1] "" Vector__XXX
 SG_ VCBATT2_a227_motorPhaseCurrentIr m227 : 42|1@1+ (1,0) [0|1] "" Vector__XXX
 SG_ VCBATT2_a227_chipOvertemp m227 : 43|1@1+ (1,0) [0|1] "" Vector__XXX
 SG_ VCBATT2_a227_motorSpeedTooHigh m227 : 44|1@1+ (1,0) [0|1] "" Vector__XXX
 SG_ VCBATT2_a227_phaseOvercurrent m227 : 45|1@1+ (1,0) [0|1] "" Vector__XXX
 SG_ VCBATT2_a227_vddaOvercurrent m227 : 46|1@1+ (1,0) [0|1] "" Vector__XXX
 SG_ VCBATT2_a227_busVoltageUnhealthy m227 : 47|1@1+ (1,0) [0|1] "" Vector__XXX
 SG_ VCBATT2_a227_hsVdsOvervoltage m227 : 48|1@1+ (1,0) [0|1] "" Vector__XXX
 SG_ VCBATT2_a227_hsVdsOvervoltageMas m227 : 49|3@1+ (1,0) [0|7] "" Vector__XXX
 SG_ VCBATT2_a227_lsVdsOvervoltage m227 : 52|1@1+ (1,0) [0|1] "" Vector__XXX
 SG_ VCBATT2_a227_lsVdsOvervoltageMas m227 : 53|3@1+ (1,0) [0|7] "" Vector__XXX
 SG_ VCBATT2_a227_payloadBitsNotSet m227 : 56|1@1+ (1,0) [0|1] "" Vector__XXX
 SG_ VCBATT2_a300_oldType m300 : 16|2@1+ (1,0) [0|3] "" Vector__XXX
 SG_ VCBATT2_a300_newType m300 : 18|2@1+ (1,0) [0|3] "" Vector__XXX
 SG_ VCBATT2_a303_vehicleSpeed m303 : 16|12@1+ (0.08,-40) [-40|287.6] "kph" Vector__XXX
 SG_ VCBATT2_a303_postVoltage m303 : 32|16@1+ (0.1,0) [0|6553.5] "V" Vector__XXX
 SG_ VCBATT2_a303_lockStatus m303 : 48|2@1+ (1,0) [1|3] "" Vector__XXX
 SG_ VCBATT2_a304_voltage m304 : 16|7@1+ (0.15,0) [0|19.05] "V" Vector__XXX
 SG_ VCBATT2_a304_temperature m304 : 24|8@1+ (0.5,-40) [-40|87.5] "degC" Vector__XXX
 SG_ VCBATT2_a305_voltage m305 : 16|7@1+ (0.15,0) [0|19.05] "V" Vector__XXX
 SG_ VCBATT2_a305_temperature m305 : 24|8@1+ (0.5,-40) [-40|87.5] "degC" Vector__XXX
 SG_ VCBATT2_a305_actuatorCurrent m305 : 32|8@1+ (0.1,0) [0|25.5] "A" Vector__XXX
 SG_ VCBATT2_a306_voltage m306 : 16|7@1+ (0.15,0) [0|19.05] "V" Vector__XXX
 SG_ VCBATT2_a306_temperature m306 : 24|8@1+ (0.5,-40) [-40|87.5] "degC" Vector__XXX
 SG_ VCBATT2_a306_actuatorCurrent m306 : 32|8@1+ (0.1,0) [0|25.5] "A" Vector__XXX
 SG_ VCBATT2_a309_vehicleSpeed m309 : 16|12@1+ (0.08,-40) [-40|287.6] "kph" Vector__XXX
 SG_ VCBATT2_a309_switchVoltage m309 : 32|16@1+ (0.1,0) [0|6553.5] "V" Vector__XXX
 SG_ VCBATT2_a309_lockStatus m309 : 48|2@1+ (1,0) [1|3] "" Vector__XXX
 SG_ VCBATT2_a353_wiperHeaterCurrent m353 : 16|8@1+ (0.1,0) [0|25.5] "A" Vector__XXX
 SG_ VCBATT2_a353_batteryVoltage m353 : 24|7@1+ (0.15,0) [0|19.05] "V" Vector__XXX
 SG_ VCBATT2_a353_ambientTemperature m353 : 32|8@1+ (0.5,-40) [-39.5|87.5] "degC" Vector__XXX
 SG_ VCBATT2_a354_windshieldCameraHea m354 : 16|8@1+ (0.1,0) [0|25.5] "A" Vector__XXX
 SG_ VCBATT2_a354_batteryVoltage m354 : 24|7@1+ (0.15,0) [0|19.05] "V" Vector__XXX
 SG_ VCBATT2_a354_ambientTemperature m354 : 32|8@1+ (0.5,-40) [-39.5|87.5] "degC" Vector__XXX
 SG_ VCBATT2_a389_closedAtSpeed m389 : 16|1@1+ (1,0) [0|1] "" Vector__XXX
 SG_ VCBATT2_a389_faultedWhileOpenAtS m389 : 17|1@1+ (1,0) [0|1] "" Vector__XXX
 SG_ VCBATT2_a389_possiblyStuckClosed m389 : 18|1@1+ (1,0) [0|1] "" Vector__XXX
 SG_ VCBATT2_a389_vehicleSpeed m389 : 19|12@1+ (0.08,-40) [-40|287.6] "kph" Vector__XXX
 SG_ VCBATT2_a389_temperature m389 : 32|8@1+ (0.5,-40) [-40|87.5] "degC" Vector__XXX
 SG_ VCBATT2_a389_latchStatus m389 : 40|4@1+ (1,0) [1|15] "" Vector__XXX
 SG_ VCBATT2_a391_switchMismatch m391 : 16|1@1+ (1,0) [0|1] "" Vector__XXX
 SG_ VCBATT2_a391_switch1Shorted m391 : 17|1@1+ (1,0) [0|1] "" Vector__XXX
 SG_ VCBATT2_a391_switch1Disconnected m391 : 18|1@1+ (1,0) [0|1] "" Vector__XXX
 SG_ VCBATT2_a391_switch2Shorted m391 : 19|1@1+ (1,0) [0|1] "" Vector__XXX
 SG_ VCBATT2_a391_switch2Disconnected m391 : 20|1@1+ (1,0) [0|1] "" Vector__XXX
 SG_ VCBATT2_a391_switch1VoltageAvera m391 : 21|10@1+ (5,0) [0|5115] "mV" Vector__XXX
 SG_ VCBATT2_a391_switch1VoltageInsta m391 : 32|10@1+ (5,0) [0|5115] "mV" Vector__XXX
 SG_ VCBATT2_a391_switch2VoltageAvera m391 : 42|10@1+ (5,0) [0|5115] "mV" Vector__XXX
 SG_ VCBATT2_a391_switch2VoltageInsta m391 : 52|10@1+ (5,0) [0|5115] "mV" Vector__XXX
 SG_ VCBATT2_a463_switchMismatch m463 : 16|1@1+ (1,0) [0|1] "" Vector__XXX
 SG_ VCBATT2_a463_switch1Shorted m463 : 17|1@1+ (1,0) [0|1] "" Vector__XXX
 SG_ VCBATT2_a463_switch1Disconnected m463 : 18|1@1+ (1,0) [0|1] "" Vector__XXX
 SG_ VCBATT2_a463_switch2Shorted m463 : 19|1@1+ (1,0) [0|1] "" Vector__XXX
 SG_ VCBATT2_a463_switch2Disconnected m463 : 20|1@1+ (1,0) [0|1] "" Vector__XXX
 SG_ VCBATT2_a463_switch1VoltageAvera m463 : 21|10@1+ (5,0) [0|5115] "mV" Vector__XXX
 SG_ VCBATT2_a463_switch1VoltageInsta m463 : 32|10@1+ (5,0) [0|5115] "mV" Vector__XXX
 SG_ VCBATT2_a463_switch2VoltageAvera m463 : 42|10@1+ (5,0) [0|5115] "mV" Vector__XXX
 SG_ VCBATT2_a463_switch2VoltageInsta m463 : 52|10@1+ (5,0) [0|5115] "mV" Vector__XXX
 SG_ VCBATT2_a485_mcuGamingEFuseCurre m485 : 16|10@1+ (0.1,0) [0|102.3] "A" Vector__XXX
 SG_ VCBATT2_a516_IBSVoltage m516 : 16|8@1+ (0.1,0) [0|25.5] "V" Vector__XXX
 SG_ VCBATT2_a516_HVSoc m516 : 24|10@1+ (0.1,0) [0|102.3] "%" Vector__XXX
 SG_ VCBATT2_a516_contactorsPermanent m516 : 34|1@1+ (1,0) [0|1] "" Vector__XXX
 SG_ VCBATT2_a516_LVBatteryDisconnect m516 : 35|1@1+ (1,0) [0|1] "" Vector__XXX
 SG_ VCBATT2_a516_reverseBatteryFault m516 : 36|1@1+ (1,0) [0|1] "" Vector__XXX
 SG_ VCBATT2_a516_LVBatteryCannotSupp m516 : 37|1@1+ (1,0) [0|1] "" Vector__XXX
 SG_ VCBATT2_a517_IBSVoltage m517 : 16|8@1+ (0.1,0) [0|25.5] "V" Vector__XXX
 SG_ VCBATT2_a517_HVSoc m517 : 24|10@1+ (0.1,0) [0|102.3] "%" Vector__XXX
 SG_ VCBATT2_a522_IBSVoltage m522 : 16|8@1+ (0.1,0) [0|25.5] "V" Vector__XXX
 SG_ VCBATT2_a522_HVSoc m522 : 24|10@1+ (0.1,0) [0|102.3] "%" Vector__XXX
 SG_ VCBATT2_a522_contactorsPermanent m522 : 34|1@1+ (1,0) [0|1] "" Vector__XXX
 SG_ VCBATT2_a522_LVBatteryDisconnect m522 : 35|1@1+ (1,0) [0|1] "" Vector__XXX
 SG_ VCBATT2_a522_reverseBatteryFault m522 : 36|1@1+ (1,0) [0|1] "" Vector__XXX
 SG_ VCBATT2_a522_LVBatteryCannotSupp m522 : 37|1@1+ (1,0) [0|1] "" Vector__XXX
 SG_ VCBATT2_a547_serviceMode m547 : 16|1@1+ (1,0) [0|1] "" Vector__XXX
 SG_ VCBATT2_a547_frunkOpen m547 : 17|1@1+ (1,0) [0|1] "" Vector__XXX
 SG_ VCBATT2_a548_vehiclePowerState m548 : 16|2@1+ (1,0) [0|3] "" Vector__XXX
 SG_ VCBATT2_a548_notEnoughPowerForSu m548 : 18|1@1+ (1,0) [0|1] "" Vector__XXX
 SG_ VCBATT2_a548_HVBlockingMismatch m548 : 19|1@1+ (1,0) [0|1] "" Vector__XXX
 SG_ VCBATT2_a548_LVBatteryCannotSupp m548 : 20|1@1+ (1,0) [0|1] "" Vector__XXX
 SG_ VCBATT2_a548_DI_gear m548 : 21|3@1+ (1,0) [0|6] "" Vector__XXX
 SG_ VCBATT2_a548_backstopBucketCount m548 : 24|5@1+ (0.035,0) [0|1.085] "Ah" Vector__XXX
 SG_ VCBATT2_a548_hvState m548 : 29|3@1+ (1,0) [0|7] "" Vector__XXX
 SG_ VCBATT2_a548_BMS_MIA m548 : 32|1@1+ (1,0) [0|1] "" Vector__XXX
 SG_ VCBATT2_a548_PCS_MIA m548 : 33|1@1+ (1,0) [0|1] "" Vector__XXX
 SG_ VCBATT2_a548_ampHourBucketCount m548 : 34|6@1+ (0.01,0) [0|0.63] "Ah" Vector__XXX
 SG_ VCBATT2_a548_LVBMSSOC m548 : 40|5@1+ (3,0) [0|93] "%" Vector__XXX
 SG_ VCBATT2_a548_serviceMode m548 : 45|1@1+ (1,0) [0|1] "" Vector__XXX
 SG_ VCBATT2_a548_frunkOpen m548 : 46|1@1+ (1,0) [0|1] "" Vector__XXX
 SG_ VCBATT2_a548_PCSTargetVoltage m548 : 48|8@1+ (0.1,0) [0|25.5] "V" Vector__XXX
 SG_ VCBATT2_a548_ampHourBucketFilled m548 : 56|1@1+ (1,0) [0|1] "" Vector__XXX
 SG_ VCBATT2_a548_HVNotConfirmedUpTri m548 : 57|1@1+ (1,0) [0|1] "" Vector__XXX
 SG_ VCBATT2_a548_PCSNotMeetingTarget m548 : 58|1@1+ (1,0) [0|1] "" Vector__XXX
 SG_ VCBATT2_a548_PCSMIATrigger m548 : 59|1@1+ (1,0) [0|1] "" Vector__XXX
 SG_ VCBATT2_a548_PCSSaturatedTrigger m548 : 60|1@1+ (1,0) [0|1] "" Vector__XXX
 SG_ VCBATT2_a548_backstopHit m548 : 61|1@1+ (1,0) [0|1] "" Vector__XXX
 SG_ VCBATT2_a610_switch1State m610 : 16|2@1+ (1,0) [1|3] "" Vector__XXX
 SG_ VCBATT2_a610_switch2State m610 : 18|2@1+ (1,0) [1|3] "" Vector__XXX
 SG_ VCBATT2_a610_dataBufferBits m610 : 20|10@1+ (1,0) [0|1023] "" Vector__XXX
 SG_ VCBATT2_a610_temperature m610 : 32|8@1+ (0.5,-40) [-39.5|87.5] "degC" Vector__XXX
 SG_ VCBATT2_a668_hcmRegionAndSide m668 : 16|3@1+ (1,0) [1|7] "" Vector__XXX
 SG_ VCBATT2_a668_country m668 : 24|16@1+ (1,0) [0|65535] "" Vector__XXX
 SG_ VCBATT2_a668_homologationRegionO m668 : 40|2@1+ (1,0) [0|3] "" Vector__XXX
 SG_ VCBATT2_a668_isRightHandDrive m668 : 42|1@1+ (1,0) [0|1] "" Vector__XXX
 SG_ VCBATT2_a698_isGlobalHeadlamps m698 : 16|1@1+ (1,0) [0|1] "" Vector__XXX
 SG_ VCBATT2_a698_isVirtualPitchSenso m698 : 17|1@1+ (1,0) [0|1] "" Vector__XXX
 SG_ VCBATT2_a698_calibratedVerticalP m698 : 18|10@1+ (1,0) [0|1022] "Steps" Vector__XXX
 SG_ VCBATT2_a698_calibratedHorizonta m698 : 28|10@1+ (1,0) [0|1022] "Steps" Vector__XXX

BO_ 975 VCBATT2_alertMatrix: 8 VCBATT2
 SG_ VCBATT2_matrixIndex M : 0|4@1+ (1,0) [0|15] "" Vector__XXX
 SG_ VCBATT2_a001_WatchdogReset m0 : 4|1@1+ (1,0) [0|1] "" Vector__XXX
 SG_ VCBATT2_a002_PowerLossReset m0 : 5|1@1+ (1,0) [0|1] "" Vector__XXX
 SG_ VCBATT2_a003_SWAssertion m0 : 6|1@1+ (1,0) [0|1] "" Vector__XXX
 SG_ VCBATT2_a005_CANTXError m0 : 8|1@1+ (1,0) [0|1] "" Vector__XXX
 SG_ VCBATT2_a006_CANTX_cyclicError m0 : 9|1@1+ (1,0) [0|1] "" Vector__XXX
 SG_ VCBATT2_a012_CPUReset m0 : 15|1@1+ (1,0) [0|1] "" Vector__XXX
 SG_ VCBATT2_a013_AlertManagerFault m0 : 16|1@1+ (1,0) [0|1] "" Vector__XXX
 SG_ VCBATT2_a015_NVMMError m0 : 18|1@1+ (1,0) [0|1] "" Vector__XXX
 SG_ VCBATT2_a016_NVMMRecordError m0 : 19|1@1+ (1,0) [0|1] "" Vector__XXX
 SG_ VCBATT2_a017_NVMMStatusDbg m0 : 20|1@1+ (1,0) [0|1] "" Vector__XXX
 SG_ VCBATT2_a018_HardFault m0 : 21|1@1+ (1,0) [0|1] "" Vector__XXX
 SG_ VCBATT2_a019_BusFault m0 : 22|1@1+ (1,0) [0|1] "" Vector__XXX
 SG_ VCBATT2_a021_TaskSchedulerError m0 : 24|1@1+ (1,0) [0|1] "" Vector__XXX
 SG_ VCBATT2_a022_TaskInitError m0 : 25|1@1+ (1,0) [0|1] "" Vector__XXX
 SG_ VCBATT2_a028_UsageFault m0 : 31|1@1+ (1,0) [0|1] "" Vector__XXX
 SG_ VCBATT2_a029_CoreDump m0 : 32|1@1+ (1,0) [0|1] "" Vector__XXX
 SG_ VCBATT2_a030_ECULogUploadRequest m0 : 33|1@1+ (1,0) [0|1] "" Vector__XXX
 SG_ VCBATT2_a031_UDSActive m0 : 34|1@1+ (1,0) [0|1] "" Vector__XXX
 SG_ VCBATT2_a036_UnknownIrq m0 : 39|1@1+ (1,0) [0|1] "" Vector__XXX
 SG_ VCBATT2_a037_MemManageFault m0 : 40|1@1+ (1,0) [0|1] "" Vector__XXX
 SG_ VCBATT2_a038_ProtFaultInfo m0 : 41|1@1+ (1,0) [0|1] "" Vector__XXX
 SG_ VCBATT2_a039_ProtFaultAddress m0 : 42|1@1+ (1,0) [0|1] "" Vector__XXX
 SG_ VCBATT2_a040_Backtrace m0 : 43|1@1+ (1,0) [0|1] "" Vector__XXX
 SG_ VCBATT2_a041_HighCPULoad m0 : 44|1@1+ (1,0) [0|1] "" Vector__XXX
 SG_ VCBATT2_a042_HighStackUsage m0 : 45|1@1+ (1,0) [0|1] "" Vector__XXX
 SG_ VCBATT2_a043_Task1msError m0 : 46|1@1+ (1,0) [0|1] "" Vector__XXX
 SG_ VCBATT2_a044_Task10msError m0 : 47|1@1+ (1,0) [0|1] "" Vector__XXX
 SG_ VCBATT2_a045_Task100msError m0 : 48|1@1+ (1,0) [0|1] "" Vector__XXX
 SG_ VCBATT2_a046_Task1000msError m0 : 49|1@1+ (1,0) [0|1] "" Vector__XXX
 SG_ VCBATT2_a058_inputRHighSyncDebug m0 : 61|1@1+ (1,0) [0|1] "" Vector__XXX
 SG_ VCBATT2_a059_inputResistanceHigh m0 : 62|1@1+ (1,0) [0|1] "" Vector__XXX
 SG_ VCBATT2_a060_engineeringBuild m0 : 63|1@1+ (1,0) [0|1] "" Vector__XXX
 SG_ VCBATT2_a061_XCPConnected m1 : 4|1@1+ (1,0) [0|1] "" Vector__XXX
 SG_ VCBATT2_a062_XCPWasConnected m1 : 5|1@1+ (1,0) [0|1] "" Vector__XXX
 SG_ VCBATT2_a063_SwitchFault m1 : 6|1@1+ (1,0) [0|1] "" Vector__XXX
 SG_ VCBATT2_a064_busSleepReqTimeout m1 : 7|1@1+ (1,0) [0|1] "" Vector__XXX
 SG_ VCBATT2_a077_VCBATT0_MIA m1 : 20|1@1+ (1,0) [0|1] "" Vector__XXX
 SG_ VCBATT2_a078_VCBATT1_MIA m1 : 21|1@1+ (1,0) [0|1] "" Vector__XXX
 SG_ VCBATT2_a079_VCBATT2_MIA m1 : 22|1@1+ (1,0) [0|1] "" Vector__XXX
 SG_ VCBATT2_a080_VCFRONT0_MIA m1 : 23|1@1+ (1,0) [0|1] "" Vector__XXX
 SG_ VCBATT2_a081_VCFRONT1_MIA m1 : 24|1@1+ (1,0) [0|1] "" Vector__XXX
 SG_ VCBATT2_a082_VCFRONT2_MIA m1 : 25|1@1+ (1,0) [0|1] "" Vector__XXX
 SG_ VCBATT2_a086_VCBATT_MIA m1 : 29|1@1+ (1,0) [0|1] "" Vector__XXX
 SG_ VCBATT2_a090_APS_MIA m1 : 33|1@1+ (1,0) [0|1] "" Vector__XXX
 SG_ VCBATT2_a091_CMPD_MIA m1 : 34|1@1+ (1,0) [0|1] "" Vector__XXX
 SG_ VCBATT2_a096_OCS1P_MIA m1 : 39|1@1+ (1,0) [0|1] "" Vector__XXX
 SG_ VCBATT2_a098_DIR_MIA m1 : 41|1@1+ (1,0) [0|1] "" Vector__XXX
 SG_ VCBATT2_a100_CANbus_MIA m1 : 43|1@1+ (1,0) [0|1] "" Vector__XXX
 SG_ VCBATT2_a103_CP_MIA m1 : 46|1@1+ (1,0) [0|1] "" Vector__XXX
 SG_ VCBATT2_a104_DAS_MIA m1 : 47|1@1+ (1,0) [0|1] "" Vector__XXX
 SG_ VCBATT2_a105_TAS_MIA m1 : 48|1@1+ (1,0) [0|1] "" Vector__XXX
 SG_ VCBATT2_a106_PCS_MIA m1 : 49|1@1+ (1,0) [0|1] "" Vector__XXX
 SG_ VCBATT2_a107_BMS_MIA m1 : 50|1@1+ (1,0) [0|1] "" Vector__XXX
 SG_ VCBATT2_a108_DIF_MIA m1 : 51|1@1+ (1,0) [0|1] "" Vector__XXX
 SG_ VCBATT2_a109_RCM_MIA m1 : 52|1@1+ (1,0) [0|1] "" Vector__XXX
 SG_ VCBATT2_a110_GTW_MIA m1 : 53|1@1+ (1,0) [0|1] "" Vector__XXX
 SG_ VCBATT2_a111_EPBR_MIA m1 : 54|1@1+ (1,0) [0|1] "" Vector__XXX
 SG_ VCBATT2_a112_EPBL_MIA m1 : 55|1@1+ (1,0) [0|1] "" Vector__XXX
 SG_ VCBATT2_a113_UI_MIA m1 : 56|1@1+ (1,0) [0|1] "" Vector__XXX
 SG_ VCBATT2_a114_ESP_MIA m1 : 57|1@1+ (1,0) [0|1] "" Vector__XXX
 SG_ VCBATT2_a115_VCSEC_MIA m1 : 58|1@1+ (1,0) [0|1] "" Vector__XXX
 SG_ VCBATT2_a116_VCRIGHT_MIA m1 : 59|1@1+ (1,0) [0|1] "" Vector__XXX
 SG_ VCBATT2_a117_VCLEFT_MIA m1 : 60|1@1+ (1,0) [0|1] "" Vector__XXX
 SG_ VCBATT2_a118_VCFRONT_MIA m1 : 61|1@1+ (1,0) [0|1] "" Vector__XXX
 SG_ VCBATT2_a119_SCCM_MIA m1 : 62|1@1+ (1,0) [0|1] "" Vector__XXX
 SG_ VCBATT2_a120_DI_DRIVE_MIA m1 : 63|1@1+ (1,0) [0|1] "" Vector__XXX
 SG_ VCBATT2_a122_ICR_MIA m2 : 5|1@1+ (1,0) [0|1] "" Vector__XXX
 SG_ VCBATT2_a123_VC_SECONDARY_LIGHTI m2 : 6|1@1+ (1,0) [0|1] "" Vector__XXX
 SG_ VCBATT2_a124_BB_MIA m2 : 7|1@1+ (1,0) [0|1] "" Vector__XXX
 SG_ VCBATT2_a125_SCCM_MIA m2 : 8|1@1+ (1,0) [0|1] "" Vector__XXX
 SG_ VCBATT2_a126_EPAS3P_MIA m2 : 9|1@1+ (1,0) [0|1] "" Vector__XXX
 SG_ VCBATT2_a131_PCSCOMMON_MIA m2 : 14|1@1+ (1,0) [0|1] "" Vector__XXX
 SG_ VCBATT2_a133_BRAKE_MIA m2 : 16|1@1+ (1,0) [0|1] "" Vector__XXX
 SG_ VCBATT2_a143_powerLossDuringSlee m2 : 26|1@1+ (1,0) [0|1] "" Vector__XXX
 SG_ VCBATT2_a144_EPAS3S_MIA m2 : 27|1@1+ (1,0) [0|1] "" Vector__XXX
 SG_ VCBATT2_a156_louverBlockage m2 : 39|1@1+ (1,0) [0|1] "" Vector__XXX
 SG_ VCBATT2_a157_louverBreakage m2 : 40|1@1+ (1,0) [0|1] "" Vector__XXX
 SG_ VCBATT2_a158_louverDisconnected m2 : 41|1@1+ (1,0) [0|1] "" Vector__XXX
 SG_ VCBATT2_a166_rightHCMMIA m2 : 49|1@1+ (1,0) [0|1] "" Vector__XXX
 SG_ VCBATT2_a181_homelinkMIA m3 : 4|1@1+ (1,0) [0|1] "" Vector__XXX
 SG_ VCBATT2_a185_washerFluidLow m3 : 8|1@1+ (1,0) [0|1] "" Vector__XXX
 SG_ VCBATT2_a186_washerFluidLowFasci m3 : 9|1@1+ (1,0) [0|1] "" Vector__XXX
 SG_ VCBATT2_a187_washerFluidLowPasse m3 : 10|1@1+ (1,0) [0|1] "" Vector__XXX
 SG_ VCBATT2_a188_sleepFailed m3 : 11|1@1+ (1,0) [0|1] "" Vector__XXX
 SG_ VCBATT2_a192_vehicleLoadShed m3 : 15|1@1+ (1,0) [0|1] "" Vector__XXX
 SG_ VCBATT2_a208_brakeFluidLow m3 : 31|1@1+ (1,0) [0|1] "" Vector__XXX
 SG_ VCBATT2_a209_brakeFluidSNA m3 : 32|1@1+ (1,0) [0|1] "" Vector__XXX
 SG_ VCBATT2_a211_I2CFault m3 : 34|1@1+ (1,0) [0|1] "" Vector__XXX
 SG_ VCBATT2_a227_radFanCompromised m3 : 50|1@1+ (1,0) [0|1] "" Vector__XXX
 SG_ VCBATT2_a241_radFanMIA m4 : 4|1@1+ (1,0) [0|1] "" Vector__XXX
 SG_ VCBATT2_a290_leftFogLightFault m4 : 53|1@1+ (1,0) [0|1] "" Vector__XXX
 SG_ VCBATT2_a291_rightFogLightFault m4 : 54|1@1+ (1,0) [0|1] "" Vector__XXX
 SG_ VCBATT2_a292_sideMarkerLightPipe m4 : 55|1@1+ (1,0) [0|1] "" Vector__XXX
 SG_ VCBATT2_a295_rightSideRepeaterLi m4 : 58|1@1+ (1,0) [0|1] "" Vector__XXX
 SG_ VCBATT2_a299_homelinkConfigurati m4 : 62|1@1+ (1,0) [0|1] "" Vector__XXX
 SG_ VCBATT2_a300_louverActuatorSwapD m4 : 63|1@1+ (1,0) [0|1] "" Vector__XXX
 SG_ VCBATT2_a303_frunkAccessPostActi m5 : 6|1@1+ (1,0) [0|1] "" Vector__XXX
 SG_ VCBATT2_a304_frunkReleaseFailed m5 : 7|1@1+ (1,0) [0|1] "" Vector__XXX
 SG_ VCBATT2_a305_frunkPriOverCurrent m5 : 8|1@1+ (1,0) [0|1] "" Vector__XXX
 SG_ VCBATT2_a306_frunkPriUnderCurren m5 : 9|1@1+ (1,0) [0|1] "" Vector__XXX
 SG_ VCBATT2_a309_frunkEmergencyRelea m5 : 12|1@1+ (1,0) [0|1] "" Vector__XXX
 SG_ VCBATT2_a353_wiperHeaterUndercur m5 : 56|1@1+ (1,0) [0|1] "" Vector__XXX
 SG_ VCBATT2_a354_windshieldCameraHea m5 : 57|1@1+ (1,0) [0|1] "" Vector__XXX
 SG_ VCBATT2_a361_washerFluidLowMomen m6 : 4|1@1+ (1,0) [0|1] "" Vector__XXX
 SG_ VCBATT2_a364_heaterTypeEstimatio m6 : 7|1@1+ (1,0) [0|1] "" Vector__XXX
 SG_ VCBATT2_a389_frunkInhibitingRele m6 : 32|1@1+ (1,0) [0|1] "" Vector__XXX
 SG_ VCBATT2_a391_frunkLatchSwitchFau m6 : 34|1@1+ (1,0) [0|1] "" Vector__XXX
 SG_ VCBATT2_a399_frunkNeverReportedO m6 : 42|1@1+ (1,0) [0|1] "" Vector__XXX
 SG_ VCBATT2_a423_rtosSleepFailed m7 : 6|1@1+ (1,0) [0|1] "" Vector__XXX
 SG_ VCBATT2_a463_frunkSensorService m7 : 46|1@1+ (1,0) [0|1] "" Vector__XXX
 SG_ VCBATT2_a471_emergencyFrunkButto m7 : 54|1@1+ (1,0) [0|1] "" Vector__XXX
 SG_ VCBATT2_a475_rightHeadlampIntern m7 : 58|1@1+ (1,0) [0|1] "" Vector__XXX
 SG_ VCBATT2_a485_mcuGamingEFuseFault m8 : 8|1@1+ (1,0) [0|1] "" Vector__XXX
 SG_ VCBATT2_a486_sleepPowerDebug m8 : 9|1@1+ (1,0) [0|1] "" Vector__XXX
 SG_ VCBATT2_a516_hibernationActive m8 : 39|1@1+ (1,0) [0|1] "" Vector__XXX
 SG_ VCBATT2_a517_hibernationRecovery m8 : 40|1@1+ (1,0) [0|1] "" Vector__XXX
 SG_ VCBATT2_a520_rightHeadlampIntern m8 : 43|1@1+ (1,0) [0|1] "" Vector__XXX
 SG_ VCBATT2_a522_hibernationActiveLo m8 : 45|1@1+ (1,0) [0|1] "" Vector__XXX
 SG_ VCBATT2_a524_rightHeadlampAiming m8 : 47|1@1+ (1,0) [0|1] "" Vector__XXX
 SG_ VCBATT2_a547_postCrashLoadShed m9 : 10|1@1+ (1,0) [0|1] "" Vector__XXX
 SG_ VCBATT2_a548_HVFaultLoadShed m9 : 11|1@1+ (1,0) [0|1] "" Vector__XXX
 SG_ VCBATT2_a557_rightHeadlampIntern m9 : 20|1@1+ (1,0) [0|1] "" Vector__XXX
 SG_ VCBATT2_a558_rightHeadlampAiming m9 : 21|1@1+ (1,0) [0|1] "" Vector__XXX
 SG_ VCBATT2_a567_rightFrontTurnLight m9 : 30|1@1+ (1,0) [0|1] "" Vector__XXX
 SG_ VCBATT2_a569_rightDaytimeRunning m9 : 32|1@1+ (1,0) [0|1] "" Vector__XXX
 SG_ VCBATT2_a575_frontOilPumpEFuseTr m9 : 38|1@1+ (1,0) [0|1] "" Vector__XXX
 SG_ VCBATT2_a578_vbattFusedLowCurren m9 : 41|1@1+ (1,0) [0|1] "" Vector__XXX
 SG_ VCBATT2_a583_frunkSwitchGroupDis m9 : 46|1@1+ (1,0) [0|1] "" Vector__XXX
 SG_ VCBATT2_a584_frunkSwitchGroupDeb m9 : 47|1@1+ (1,0) [0|1] "" Vector__XXX
 SG_ VCBATT2_a586_rightLowOrHighBeamL m9 : 49|1@1+ (1,0) [0|1] "" Vector__XXX
 SG_ VCBATT2_a610_frunkOpenFailureMet m10 : 13|1@1+ (1,0) [0|1] "" Vector__XXX
 SG_ VCBATT2_a617_APP_MIA m10 : 20|1@1+ (1,0) [0|1] "" Vector__XXX
 SG_ VCBATT2_a619_frunkSwitchReleaseT m10 : 22|1@1+ (1,0) [0|1] "" Vector__XXX
 SG_ VCBATT2_a624_rightHeadlampIntern m10 : 27|1@1+ (1,0) [0|1] "" Vector__XXX
 SG_ VCBATT2_a631_rightHeadlampFactor m10 : 34|1@1+ (1,0) [0|1] "" Vector__XXX
 SG_ VCBATT2_a634_indeterminateSwitch m10 : 37|1@1+ (1,0) [0|1] "" Vector__XXX
 SG_ VCBATT2_a643_rightHeadlampUartCo m10 : 46|1@1+ (1,0) [0|1] "" Vector__XXX
 SG_ VCBATT2_a644_washPumpHealthCalcu m10 : 47|1@1+ (1,0) [0|1] "" Vector__XXX
 SG_ VCBATT2_a645_washPumpHealthCalcu m10 : 48|1@1+ (1,0) [0|1] "" Vector__XXX
 SG_ VCBATT2_a646_washPumpHealthCalcu m10 : 49|1@1+ (1,0) [0|1] "" Vector__XXX
 SG_ VCBATT2_a649_persistAccPortPower m10 : 52|1@1+ (1,0) [0|1] "" Vector__XXX
 SG_ VCBATT2_a650_powerConsumptionInf m10 : 53|1@1+ (1,0) [0|1] "" Vector__XXX
 SG_ VCBATT2_a662_mculessRightHeadlam m11 : 5|1@1+ (1,0) [0|1] "" Vector__XXX
 SG_ VCBATT2_a664_rightHeadlampUartWa m11 : 7|1@1+ (1,0) [0|1] "" Vector__XXX
 SG_ VCBATT2_a666_rightHeadlampRetryI m11 : 9|1@1+ (1,0) [0|1] "" Vector__XXX
 SG_ VCBATT2_a668_rightHeadlampRegion m11 : 11|1@1+ (1,0) [0|1] "" Vector__XXX
 SG_ VCBATT2_a698_rightHeadlampNotAim m11 : 41|1@1+ (1,0) [0|1] "" Vector__XXX
 SG_ VCBATT2_a702_dynamicHeadlightLev m11 : 45|1@1+ (1,0) [0|1] "" Vector__XXX

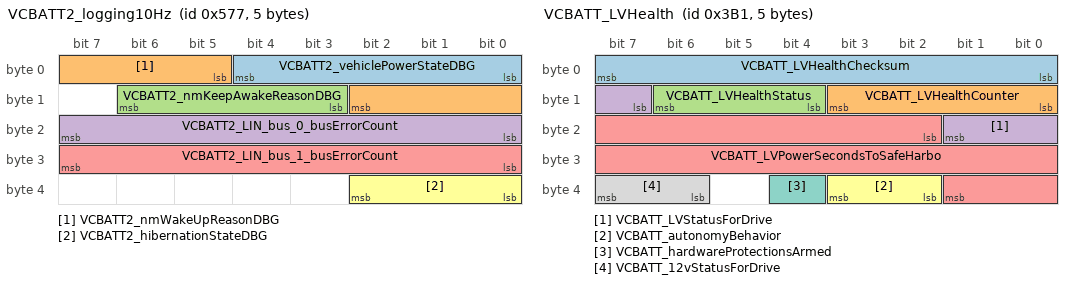
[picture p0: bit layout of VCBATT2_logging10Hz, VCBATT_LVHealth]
BO_ 1399 VCBATT2_logging10Hz: 5 VCBATT2
 SG_ VCBATT2_vehiclePowerStateDBG : 0|5@1+ (1,0) [0|31] "" Vector__XXX
 SG_ VCBATT2_nmWakeUpReasonDBG : 5|6@1+ (1,0) [0|63] "" Vector__XXX
 SG_ VCBATT2_nmKeepAwakeReasonDBG : 11|4@1+ (1,0) [1|15] "" Vector__XXX
 SG_ VCBATT2_LIN_bus_0_busErrorCount : 16|8@1+ (1,0) [0|255] "" Vector__XXX
 SG_ VCBATT2_LIN_bus_1_busErrorCount : 24|8@1+ (1,0) [0|255] "" Vector__XXX
 SG_ VCBATT2_hibernationStateDBG : 32|3@1+ (1,0) [0|7] "" Vector__XXX

BO_ 1567 VCBATT2_udsResponse: 8 VCBATT2
 SG_ VCBATT2_udsResponseData : 7|64@0+ (1,0) [0|1.84467440737e+19] "" Vector__XXX

BO_ 945 VCBATT_LVHealth: 5 VCBATT
 SG_ VCBATT_LVHealthChecksum : 0|8@1+ (1,0) [0|255] "" Vector__XXX
 SG_ VCBATT_LVHealthCounter : 8|4@1+ (1,0) [0|15] "" Vector__XXX
 SG_ VCBATT_LVHealthStatus : 12|3@1+ (1,0) [0|7] "" Vector__XXX
 SG_ VCBATT_LVStatusForDrive : 15|3@1+ (1,0) [0|7] "" Vector__XXX
 SG_ VCBATT_LVPowerSecondsToSafeHarbo : 18|16@1+ (1,0) [0|65535] "" Vector__XXX
 SG_ VCBATT_autonomyBehavior : 34|2@1+ (1,0) [0|3] "" Vector__XXX
 SG_ VCBATT_hardwareProtectionsArmed : 36|1@1+ (1,0) [0|1] "" Vector__XXX
 SG_ VCBATT_12vStatusForDrive : 38|2@1+ (1,0) [0|3] "" Vector__XXX

BO_ 1090 VCBATT_pcsInterface: 8 VCBATT
 SG_ VCBATT_pcsInterfaceMuxIndex M : 48|1@1+ (1,0) [0|1] "" Vector__XXX
 SG_ VCBATT_pcsInterfaceCounter : 50|4@1+ (1,0) [0|15] "" Vector__XXX
 SG_ VCBATT_pcsInterfaceChecksum : 56|8@1+ (1,0) [0|255] "" Vector__XXX
 SG_ VCBATT_pcsLVVoltageTarget m0 : 0|13@1+ (0.01,0) [0|65.535] "V" Vector__XXX
 SG_ VCBATT_pcsLVMinVoltageLimit m0 : 13|13@1+ (0.01,0) [0|65.535] "V" Vector__XXX
 SG_ VCBATT_pcsLVMaxVoltageLimit m0 : 27|13@1+ (0.01,0) [0|65.535] "V" Vector__XXX
 SG_ VCBATT_goodForPCSPowerCycle m0 : 46|1@1+ (1,0) [0|1] "" Vector__XXX
 SG_ VCBATT_LVBatteryCannotSupportVeh m0 : 47|1@1+ (1,0) [0|1] "" Vector__XXX
 SG_ VCBATT_pcsResistanceFiltered m1 : 0|16@1+ (0.01,0) [0|655.34] "mOhm" Vector__XXX
 SG_ VCBATT_pcsLVMaxDchrgCurrentLimit m1 : 16|12@1+ (0.1,0) [0|400] "A" Vector__XXX
 SG_ VCBATT_defaultPcsLVVoltageTarget m1 : 28|13@1+ (0.01,0) [0|65.535] "V" Vector__XXX
 SG_ VCBATT_lvHwProtSelfTestActive m1 : 41|1@1+ (1,0) [0|1] "" Vector__XXX
 SG_ VCBATT_lvBatteryDischargeRequest m1 : 42|1@1+ (1,0) [0|1] "" Vector__XXX

BO_ 1587 VCBATT_udsResponse: 8 VCBATT
 SG_ VCBATT_udsResponseData : 7|64@0+ (1,0) [0|1.84467440737e+19] "" Vector__XXX

BO_ 1994 VCCC_info: 8 VCCC
 SG_ VCCC_infoIndex M : 0|8@1+ (1,0) [0|255] "" Vector__XXX
 SG_ VCCC_infoBuildType m10 : 8|8@1+ (1,0) [0|255] "" Vector__XXX
 SG_ VCCC_infoBuildConfigId m10 : 16|16@1+ (1,0) [0|65535] "" Vector__XXX
 SG_ VCCC_infoHardwareId m10 : 32|16@1+ (1,0) [0|65535] "" Vector__XXX
 SG_ VCCC_infoComponentId m10 : 48|16@1+ (1,0) [0|65535] "" Vector__XXX
 SG_ VCCC_infoPcbaId m11 : 8|8@1+ (1,0) [0|255] "" Vector__XXX
 SG_ VCCC_infoAssemblyId m11 : 16|8@1+ (1,0) [0|254] "" Vector__XXX
 SG_ VCCC_infoUsageId m11 : 24|16@1+ (1,0) [0|65535] "" Vector__XXX
 SG_ VCCC_infoSubUsageId m11 : 40|16@1+ (1,0) [0|65535] "" Vector__XXX
 SG_ VCCC_infoAppCrc m13 : 8|32@1+ (1,0) [0|4294967295] "" Vector__XXX
 SG_ VCCC_infoAppGitHash m17 : 8|56@1+ (1,0) [0|7.20575940379e+16] "" Vector__XXX
 SG_ VCCC_infoBootGitHash m18 : 8|56@1+ (1,0) [0|7.20575940379e+16] "" Vector__XXX
 SG_ VCCC_infoBootUdsProtoVersion m20 : 8|8@1+ (1,0) [0|255] "" Vector__XXX
 SG_ VCCC_infoBootCrc m20 : 24|32@1+ (1,0) [0|4294967295] "" Vector__XXX

BO_TX_BU_ 974 : VCBATT1;
BO_TX_BU_ 1030 : VCBATT1;
BO_TX_BU_ 1549 : VCBATT1;
BO_TX_BU_ 1358 : VCBATT2;
BO_TX_BU_ 975 : VCBATT2;
BO_TX_BU_ 1399 : VCBATT2;
BO_TX_BU_ 1567 : VCBATT2;
BO_TX_BU_ 945 : VCBATT;
BO_TX_BU_ 1090 : VCBATT;
BO_TX_BU_ 1587 : VCBATT;
BO_TX_BU_ 1994 : VCCC;
CM_ BO_ 974 "VCBATT1 ECU message: alert matrix";
CM_ SG_ 974 VCBATT1_matrixIndex "VCBATT1 ECU: matrix index";
CM_ SG_ 974 VCBATT1_a001_WatchdogReset "VCBATT1 ECU: a001 watchdog reset";
CM_ SG_ 974 VCBATT1_a002_PowerLossReset "VCBATT1 ECU: a002 power loss reset";
CM_ SG_ 974 VCBATT1_a003_SWAssertion "VCBATT1 ECU: a003 SW assertion";
CM_ SG_ 974 VCBATT1_a005_CANTXError "VCBATT1 ECU: a005 CANTX error";
CM_ SG_ 974 VCBATT1_a006_CANTX_cyclicError "VCBATT1 ECU: a006 CANTX cyclic error";
CM_ SG_ 974 VCBATT1_a012_CPUReset "VCBATT1 ECU: a012 CPU reset";
CM_ SG_ 974 VCBATT1_a013_AlertManagerFault "VCBATT1 ECU: a013 alert manager fault";
CM_ SG_ 974 VCBATT1_a015_NVMMError "VCBATT1 ECU: a015 NVMM error";
CM_ SG_ 974 VCBATT1_a016_NVMMRecordError "VCBATT1 ECU: a016 NVMM record error";
CM_ SG_ 974 VCBATT1_a017_NVMMStatusDbg "VCBATT1 ECU: a017 NVMM status dbg";
CM_ SG_ 974 VCBATT1_a018_HardFault "VCBATT1 ECU: a018 hard fault";
CM_ SG_ 974 VCBATT1_a019_BusFault "VCBATT1 ECU: a019 bus fault";
CM_ SG_ 974 VCBATT1_a021_TaskSchedulerError "VCBATT1 ECU: a021 task scheduler error";
CM_ SG_ 974 VCBATT1_a022_TaskInitError "VCBATT1 ECU: a022 task init error";
CM_ SG_ 974 VCBATT1_a028_UsageFault "VCBATT1 ECU: a028 usage fault";
CM_ SG_ 974 VCBATT1_a029_CoreDump "VCBATT1 ECU: a029 core dump";
CM_ SG_ 974 VCBATT1_a030_ECULogUploadRequest "VCBATT1 ECU: a030 ECU log upload request";
CM_ SG_ 974 VCBATT1_a031_UDSActive "VCBATT1 ECU: a031 UDS active";
CM_ SG_ 974 VCBATT1_a036_UnknownIrq "VCBATT1 ECU: a036 unknown irq";
CM_ SG_ 974 VCBATT1_a037_MemManageFault "VCBATT1 ECU: a037 mem manage fault";
CM_ SG_ 974 VCBATT1_a038_ProtFaultInfo "VCBATT1 ECU: a038 prot fault info";
CM_ SG_ 974 VCBATT1_a039_ProtFaultAddress "VCBATT1 ECU: a039 prot fault address";
CM_ SG_ 974 VCBATT1_a040_Backtrace "VCBATT1 ECU: a040 backtrace";
CM_ SG_ 974 VCBATT1_a041_HighCPULoad "VCBATT1 ECU: a041 high CPU load";
CM_ SG_ 974 VCBATT1_a042_HighStackUsage "VCBATT1 ECU: a042 high stack usage";
CM_ SG_ 974 VCBATT1_a043_Task1msError "VCBATT1 ECU: a043 task1ms error";
CM_ SG_ 974 VCBATT1_a044_Task10msError "VCBATT1 ECU: a044 task10ms error";
CM_ SG_ 974 VCBATT1_a045_Task100msError "VCBATT1 ECU: a045 task100ms error";
CM_ SG_ 974 VCBATT1_a046_Task1000msError "VCBATT1 ECU: a046 task1000ms error";
CM_ SG_ 974 VCBATT1_a058_inputRHighSyncDebug "VCBATT1 ECU: a058 input r high sync debug";
CM_ SG_ 974 VCBATT1_a059_inputResistanceHigh "VCBATT1 ECU: a059 input resistance high";
CM_ SG_ 974 VCBATT1_a060_engineeringBuild "VCBATT1 ECU: a060 engineering build";
CM_ SG_ 974 VCBATT1_a061_XCPConnected "VCBATT1 ECU: a061 XCP connected";
CM_ SG_ 974 VCBATT1_a062_XCPWasConnected "VCBATT1 ECU: a062 XCP was connected";
CM_ SG_ 974 VCBATT1_a063_SwitchFault "VCBATT1 ECU: a063 switch fault";
CM_ SG_ 974 VCBATT1_a064_busSleepReqTimeout "VCBATT1 ECU: a064 bus sleep req timeout";
CM_ SG_ 974 VCBATT1_a077_VCBATT0_MIA "VCBATT1 ECU: a077 VCBATT0 MIA";
CM_ SG_ 974 VCBATT1_a078_VCBATT1_MIA "VCBATT1 ECU: a078 VCBATT1 MIA";
CM_ SG_ 974 VCBATT1_a079_VCBATT2_MIA "VCBATT1 ECU: a079 VCBATT2 MIA";
CM_ SG_ 974 VCBATT1_a080_VCFRONT0_MIA "VCBATT1 ECU: a080 VCFRONT0 MIA";
CM_ SG_ 974 VCBATT1_a081_VCFRONT1_MIA "VCBATT1 ECU: a081 VCFRONT1 MIA";
CM_ SG_ 974 VCBATT1_a082_VCFRONT2_MIA "VCBATT1 ECU: a082 VCFRONT2 MIA";
CM_ SG_ 974 VCBATT1_a086_VCBATT_MIA "VCBATT1 ECU: a086 VCBATT MIA";
CM_ SG_ 974 VCBATT1_a090_APS_MIA "VCBATT1 ECU: a090 APS MIA";
CM_ SG_ 974 VCBATT1_a091_CMPD_MIA "VCBATT1 ECU: a091 CMPD MIA";
CM_ SG_ 974 VCBATT1_a096_OCS1P_MIA "VCBATT1 ECU: a096 OCS1 p MIA";
CM_ SG_ 974 VCBATT1_a098_DIR_MIA "VCBATT1 ECU: a098 DIR MIA";
CM_ SG_ 974 VCBATT1_a100_CANbus_MIA "VCBATT1 ECU: a100 CA nbus MIA";
CM_ SG_ 974 VCBATT1_a103_CP_MIA "VCBATT1 ECU: a103 CP MIA";
CM_ SG_ 974 VCBATT1_a104_DAS_MIA "VCBATT1 ECU: a104 DAS MIA";
CM_ SG_ 974 VCBATT1_a105_TAS_MIA "VCBATT1 ECU: a105 TAS MIA";
CM_ SG_ 974 VCBATT1_a106_PCS_MIA "VCBATT1 ECU: a106 PCS MIA";
CM_ SG_ 974 VCBATT1_a107_BMS_MIA "VCBATT1 ECU: a107 BMS MIA";
CM_ SG_ 974 VCBATT1_a108_DIF_MIA "VCBATT1 ECU: a108 DIF MIA";
CM_ SG_ 974 VCBATT1_a109_RCM_MIA "VCBATT1 ECU: a109 RCM MIA";
CM_ SG_ 974 VCBATT1_a110_GTW_MIA "VCBATT1 ECU: a110 GTW MIA";
CM_ SG_ 974 VCBATT1_a111_EPBR_MIA "VCBATT1 ECU: a111 EPBR MIA";
CM_ SG_ 974 VCBATT1_a112_EPBL_MIA "VCBATT1 ECU: a112 EPBL MIA";
CM_ SG_ 974 VCBATT1_a113_UI_MIA "VCBATT1 ECU: a113 UI MIA";
CM_ SG_ 974 VCBATT1_a114_ESP_MIA "VCBATT1 ECU: a114 ESP MIA";
CM_ SG_ 974 VCBATT1_a115_VCSEC_MIA "VCBATT1 ECU: a115 VCSEC MIA";
CM_ SG_ 974 VCBATT1_a116_VCRIGHT_MIA "VCBATT1 ECU: a116 VCRIGHT MIA";
CM_ SG_ 974 VCBATT1_a117_VCLEFT_MIA "VCBATT1 ECU: a117 VCLEFT MIA";
CM_ SG_ 974 VCBATT1_a118_VCFRONT_MIA "VCBATT1 ECU: a118 VCFRONT MIA";
CM_ SG_ 974 VCBATT1_a119_SCCM_MIA "VCBATT1 ECU: a119 SCCM MIA";
CM_ SG_ 974 VCBATT1_a120_DI_DRIVE_MIA "VCBATT1 ECU: a120 DI DRIVE MIA";
CM_ SG_ 974 VCBATT1_a122_ICR_MIA "VCBATT1 ECU: a122 ICR MIA";
CM_ SG_ 974 VCBATT1_a124_BB_MIA "VCBATT1 ECU: a124 BB MIA";
CM_ SG_ 974 VCBATT1_a125_SCCM_MIA "VCBATT1 ECU: a125 SCCM MIA";
CM_ SG_ 974 VCBATT1_a126_EPAS3P_MIA "VCBATT1 ECU: a126 EPAS3 p MIA";
CM_ SG_ 974 VCBATT1_a127_vcleftEFuseTrip "VCBATT1 ECU: a127 vcleft e fuse trip";
CM_ SG_ 974 VCBATT1_a129_epas1EFuseTrip "VCBATT1 ECU: a129 epas1 e fuse trip";
CM_ SG_ 974 VCBATT1_a130_autopilot1EFuseTrip "VCBATT1 ECU: a130 autopilot1 e fuse trip";
CM_ SG_ 974 VCBATT1_a131_PCSCOMMON_MIA "VCBATT1 ECU: a131 PCSCOMMON MIA";
CM_ SG_ 974 VCBATT1_a132_iBoosterEFuseTrip "VCBATT1 ECU: a132 i booster e fuse trip";
CM_ SG_ 974 VCBATT1_a133_BRAKE_MIA "VCBATT1 ECU: a133 BRAKE MIA";
CM_ SG_ 974 VCBATT1_a134_hvContactorsEFuseTr "VCBATT1 ECU: a134 hv contactors e fuse trip";
CM_ SG_ 974 VCBATT1_a144_EPAS3S_MIA "VCBATT1 ECU: a144 EPAS3 s MIA";
CM_ SG_ 974 VCBATT1_a164_eFuseLckoutMissing "VCBATT1 ECU: a164 e fuse lckout missing";
CM_ SG_ 974 VCBATT1_a165_unxpctdEFuseLckout "VCBATT1 ECU: a165 unxpctd e fuse lckout";
CM_ SG_ 974 VCBATT1_a180_DCDCNotSupportingLV "VCBATT1 ECU: a180 DCDC not supporting LV bus";
CM_ SG_ 974 VCBATT1_a182_replaceLVBattery "VCBATT1 ECU: a182 replace LV battery";
CM_ SG_ 974 VCBATT1_a183_replaceLVBattery2 "VCBATT1 ECU: a183 replace LV battery2";
CM_ SG_ 974 VCBATT1_a188_sleepFailed "VCBATT1 ECU: a188 sleep failed";
CM_ SG_ 974 VCBATT1_a189_IBSMIA "VCBATT1 ECU: a189 IBSMIA";
CM_ SG_ 974 VCBATT1_a191_exitDriveLowLVBusVo "VCBATT1 ECU: a191 exit drive low LV bus voltage";
CM_ SG_ 974 VCBATT1_a196_discnctdLVBattery "VCBATT1 ECU: a196 discnctd LV battery";
CM_ SG_ 974 VCBATT1_a204_undervoltageLoadshe "VCBATT1 ECU: a204 undervoltage loadshed triggered";
CM_ SG_ 974 VCBATT1_a205_overvoltageProtecti "VCBATT1 ECU: a205 overvoltage protection triggered";
CM_ SG_ 974 VCBATT1_a212_IBSOverTemp "VCBATT1 ECU: a212 IBS over temp";
CM_ SG_ 974 VCBATT1_a213_LVOvercharge "VCBATT1 ECU: a213 LV overcharge";
CM_ SG_ 974 VCBATT1_a215_selfTestOrchestrato "VCBATT1 ECU: a215 self test orchestrator debug";
CM_ SG_ 974 VCBATT1_a216_powerCutoffImminent "VCBATT1 ECU: a216 power cutoff imminent";
CM_ SG_ 974 VCBATT1_a217_LVProtectionSelfTes "VCBATT1 ECU: a217 LV protection self test invalid";
CM_ SG_ 974 VCBATT1_a219_LVVoltFloorRchd "VCBATT1 ECU: a219 LV volt floor rchd";
CM_ SG_ 974 VCBATT1_a220_LVUnhealthy "VCBATT1 ECU: a220 LV unhealthy";
CM_ SG_ 974 VCBATT1_a221_reverseBatteryFault "VCBATT1 ECU: a221 reverse battery fault";
CM_ SG_ 974 VCBATT1_a223_bridgeOvervoltageSe "VCBATT1 ECU: a223 bridge overvoltage self test failure";
CM_ SG_ 974 VCBATT1_a224_overcurrentLoadshed "VCBATT1 ECU: a224 overcurrent loadshed triggered";
CM_ SG_ 974 VCBATT1_a225_overcurrentSelfTest "VCBATT1 ECU: a225 overcurrent self test failure";
CM_ SG_ 974 VCBATT1_a226_overcurrentSelfTest "VCBATT1 ECU: a226 overcurrent self test channel fast DBG";
CM_ SG_ 974 VCBATT1_a227_overcurrentSelfTest "VCBATT1 ECU: a227 overcurrent self test channel medium DBG";
CM_ SG_ 974 VCBATT1_a228_overcurrentSelfTest "VCBATT1 ECU: a228 overcurrent self test channel slow DBG";
CM_ SG_ 974 VCBATT1_a229_LVHealthCompromised "VCBATT1 ECU: a229 LV health compromised";
CM_ SG_ 974 VCBATT1_a230_ingoingOvercurrentS "VCBATT1 ECU: a230 ingoing overcurrent self test failure";
CM_ SG_ 974 VCBATT1_a231_autopilot1EFuseTrip "VCBATT1 ECU: a231 autopilot1 e fuse trip during OTA";
CM_ SG_ 974 VCBATT1_a235_dualPowerLoadsSelfT "VCBATT1 ECU: a235 dual power loads self test failure";
CM_ SG_ 974 VCBATT1_a236_hvcDualPowerSelfTes "VCBATT1 ECU: a236 hvc dual power self test debug";
CM_ SG_ 974 VCBATT1_a243_LVOverchargeInstc "VCBATT1 ECU: a243 LV overcharge instc";
CM_ SG_ 974 VCBATT1_a244_brakeValveECUEFuseT "VCBATT1 ECU: a244 brake valve ECUE fuse trip";
CM_ SG_ 974 VCBATT1_a245_sleepBypassFault "VCBATT1 ECU: a245 sleep bypass fault";
CM_ SG_ 974 VCBATT1_a252_controllerWakeup "VCBATT1 ECU: a252 controller wakeup";
CM_ SG_ 974 VCBATT1_a253_maxChrgeSssionTmeou "VCBATT1 ECU: a253 max chrge sssion tmeout";
CM_ SG_ 974 VCBATT1_a256_nxppca9539Fault "VCBATT1 ECU: a256 nxppca9539 fault";
CM_ SG_ 974 VCBATT1_a258_resistanceEstimatio "VCBATT1 ECU: a258 resistance estimation run";
CM_ SG_ 974 VCBATT1_a259_LVVoltageDropOnHigh "VCBATT1 ECU: a259 LV voltage drop on high load current";
CM_ SG_ 974 VCBATT1_a260_deadLVBattery "VCBATT1 ECU: a260 dead LV battery";
CM_ SG_ 974 VCBATT1_a275_TLVBMS_BmbCommunica "VCBATT1 ECU: a275 TLVBMS bmb communication";
CM_ SG_ 974 VCBATT1_a276_TLVBMS_BmbDataInteg "VCBATT1 ECU: a276 TLVBMS bmb data integrity loss";
CM_ SG_ 974 VCBATT1_a277_TLVBMS_BmbStatusReg "VCBATT1 ECU: a277 TLVBMS bmb status reg error";
CM_ SG_ 974 VCBATT1_a278_TLVBMS_BmbHwOverCur "VCBATT1 ECU: a278 TLVBMS bmb hw over current fault";
CM_ SG_ 974 VCBATT1_a297_TLVBMS_BmbHwOverTem "VCBATT1 ECU: a297 TLVBMS bmb hw over temperature fault";
CM_ SG_ 974 VCBATT1_a359_postPORExcessiveAh "VCBATT1 ECU: a359 post POR excessive ah";
CM_ SG_ 974 VCBATT1_a362_TLVBMS_AllSocCorrec "VCBATT1 ECU: a362 TLVBMS all soc correction timeout";
CM_ SG_ 974 VCBATT1_a363_TLVBMS_BleedBasedWe "VCBATT1 ECU: a363 TLVBMS bleed based weak short";
CM_ SG_ 974 VCBATT1_a370_noLVSupportSocTooLo "VCBATT1 ECU: a370 no LV support soc too low";
CM_ SG_ 974 VCBATT1_a371_failureToPrechargeR "VCBATT1 ECU: a371 failure to precharge risk";
CM_ SG_ 974 VCBATT1_a372_TLVBMS_BmbHwOverVol "VCBATT1 ECU: a372 TLVBMS bmb hw over voltage fault";
CM_ SG_ 974 VCBATT1_a376_controllerWakeupDeb "VCBATT1 ECU: a376 controller wakeup debug";
CM_ SG_ 974 VCBATT1_a379_shortedCellTestRunD "VCBATT1 ECU: a379 shorted cell test run debug";
CM_ SG_ 974 VCBATT1_a387_shortedCellInstc "VCBATT1 ECU: a387 shorted cell instc";
CM_ SG_ 974 VCBATT1_a388_shortedCell "VCBATT1 ECU: a388 shorted cell";
CM_ SG_ 974 VCBATT1_a392_TLVBMS_BmbHwUnderVo "VCBATT1 ECU: a392 TLVBMS bmb hw under voltage fault";
CM_ SG_ 974 VCBATT1_a400_TLVBMS_BmbVrefBad "VCBATT1 ECU: a400 TLVBMS bmb vref bad";
CM_ SG_ 974 VCBATT1_a401_deadLVMinimalAhDisc "VCBATT1 ECU: a401 dead LV minimal ah discharged";
CM_ SG_ 974 VCBATT1_a402_LVBatteryCannotSupp "VCBATT1 ECU: a402 LV battery cannot support vehicle";
CM_ SG_ 974 VCBATT1_a403_chargeExitHardCurre "VCBATT1 ECU: a403 charge exit hard current limit";
CM_ SG_ 974 VCBATT1_a404_resistanceEstimatio "VCBATT1 ECU: a404 resistance estimation hard failure";
CM_ SG_ 974 VCBATT1_a405_dcrData1 "VCBATT1 ECU: a405 dcr data1";
CM_ SG_ 974 VCBATT1_a406_dcrData2 "VCBATT1 ECU: a406 dcr data2";
CM_ SG_ 974 VCBATT1_a407_dcrMilliOhmsAboveTh "VCBATT1 ECU: a407 dcr milli ohms above threshold";
CM_ SG_ 974 VCBATT1_a408_standbyChargeProfil "VCBATT1 ECU: a408 standby charge profile hard exit";
CM_ SG_ 974 VCBATT1_a410_LVBatteryDataCollec "VCBATT1 ECU: a410 LV battery data collection1";
CM_ SG_ 974 VCBATT1_a411_LVBatteryDataCollec "VCBATT1 ECU: a411 LV battery data collection2";
CM_ SG_ 974 VCBATT1_a412_dcrData3 "VCBATT1 ECU: a412 dcr data3";
CM_ SG_ 974 VCBATT1_a413_TLVBMS_BmbVrefWarni "VCBATT1 ECU: a413 TLVBMS bmb vref warning";
CM_ SG_ 974 VCBATT1_a414_undervoltageSelfTes "VCBATT1 ECU: a414 undervoltage self test failure";
CM_ SG_ 974 VCBATT1_a415_undervoltageSelfTes "VCBATT1 ECU: a415 undervoltage self test stuck off";
CM_ SG_ 974 VCBATT1_a416_TLVBMS_BrickOverDis "VCBATT1 ECU: a416 TLVBMS brick over discharged";
CM_ SG_ 974 VCBATT1_a417_TLVBMS_BrickOverVol "VCBATT1 ECU: a417 TLVBMS brick over voltage fault";
CM_ SG_ 974 VCBATT1_a418_TLVBMS_BrickOverVol "VCBATT1 ECU: a418 TLVBMS brick over voltage warning";
CM_ SG_ 974 VCBATT1_a419_TLVBMS_BrickSocLow "VCBATT1 ECU: a419 TLVBMS brick soc low";
CM_ SG_ 974 VCBATT1_a421_LVBatteryHealthTest "VCBATT1 ECU: a421 LV battery health test interrupted";
CM_ SG_ 974 VCBATT1_a422_rtosSleepFailed "VCBATT1 ECU: a422 rtos sleep failed";
CM_ SG_ 974 VCBATT1_a423_TLVBMS_BrickUnderVo "VCBATT1 ECU: a423 TLVBMS brick under voltage fault";
CM_ SG_ 974 VCBATT1_a424_TLVBMS_BrickUnderVo "VCBATT1 ECU: a424 TLVBMS brick under voltage ocv";
CM_ SG_ 974 VCBATT1_a425_TLVBMS_BusVoltageTo "VCBATT1 ECU: a425 TLVBMS bus voltage too high";
CM_ SG_ 974 VCBATT1_a426_TLVBMS_BusVoltageTo "VCBATT1 ECU: a426 TLVBMS bus voltage too low";
CM_ SG_ 974 VCBATT1_a427_TLVBMS_CacChange "VCBATT1 ECU: a427 TLVBMS cac change";
CM_ SG_ 974 VCBATT1_a428_TLVBMS_CacImbalance "VCBATT1 ECU: a428 TLVBMS cac imbalance";
CM_ SG_ 974 VCBATT1_a429_TLVBMS_CapacityTest "VCBATT1 ECU: a429 TLVBMS capacity test results";
CM_ SG_ 974 VCBATT1_a430_TLVBMS_ChargeCurren "VCBATT1 ECU: a430 TLVBMS charge current limit exceeded";
CM_ SG_ 974 VCBATT1_a431_TLVBMS_ChargeOverCu "VCBATT1 ECU: a431 TLVBMS charge over current";
CM_ SG_ 974 VCBATT1_a432_TLVBMS_ChargeRegula "VCBATT1 ECU: a432 TLVBMS charge regulation fault";
CM_ SG_ 974 VCBATT1_a433_TLVBMS_ConfigFromBm "VCBATT1 ECU: a433 TLVBMS config from bmb mod id failed";
CM_ SG_ 974 VCBATT1_a434_TLVBMS_ConfigInitFa "VCBATT1 ECU: a434 TLVBMS config init failed";
CM_ SG_ 974 VCBATT1_a435_TLVBMS_DchgCurrentL "VCBATT1 ECU: a435 TLVBMS dchg current limit exceeded";
CM_ SG_ 974 VCBATT1_a436_TLVBMS_DischargeOve "VCBATT1 ECU: a436 TLVBMS discharge over current";
CM_ SG_ 974 VCBATT1_a437_TLVBMS_NvmRegistrat "VCBATT1 ECU: a437 TLVBMS nvm registration error";
CM_ SG_ 974 VCBATT1_a438_TLVBMS_PackOverTemp "VCBATT1 ECU: a438 TLVBMS pack over temperature fault";
CM_ SG_ 974 VCBATT1_a439_TLVBMS_PackOverTemp "VCBATT1 ECU: a439 TLVBMS pack over temperature warning";
CM_ SG_ 974 VCBATT1_a440_TLVBMS_PackSNInvali "VCBATT1 ECU: a440 TLVBMS pack SN invalid for nvm";
CM_ SG_ 974 VCBATT1_a441_TLVBMS_ResetNeededF "VCBATT1 ECU: a441 TLVBMS reset needed for nvm pack swap";
CM_ SG_ 974 VCBATT1_a442_TLVBMS_SocChange "VCBATT1 ECU: a442 TLVBMS soc change";
CM_ SG_ 974 VCBATT1_a443_TLVBMS_BmbDieOverTe "VCBATT1 ECU: a443 TLVBMS bmb die over temperature";
CM_ SG_ 974 VCBATT1_a446_LVBatteryUnrecovera "VCBATT1 ECU: a446 LV battery unrecoverable by any device";
CM_ SG_ 974 VCBATT1_a450_doorWakeToOpenDBG "VCBATT1 ECU: a450 door wake to open DBG";
CM_ SG_ 974 VCBATT1_a461_TLVBMS_SocHighAhErr "VCBATT1 ECU: a461 TLVBMS soc high ah error";
CM_ SG_ 974 VCBATT1_a462_LVBMSFault "VCBATT1 ECU: a462 LVBMS fault";
CM_ SG_ 974 VCBATT1_a475_vnf1248Fault "VCBATT1 ECU: a475 vnf1248 fault";
CM_ SG_ 974 VCBATT1_a476_LVBMSMIA "VCBATT1 ECU: a476 LVBMSMIA";
CM_ SG_ 974 VCBATT1_a477_LVBatteryUnrecovera "VCBATT1 ECU: a477 LV battery unrecoverable by vehicle";
CM_ SG_ 974 VCBATT1_a478_LVBMS_MOSFET_Open "VCBATT1 ECU: a478 LVBMS MOSFET open";
CM_ SG_ 974 VCBATT1_a479_LVBMS_ECPA_NotClose "VCBATT1 ECU: a479 LVBMS ECPA not closed";
CM_ SG_ 974 VCBATT1_a480_vnf1048Fault "VCBATT1 ECU: a480 vnf1048 fault";
CM_ SG_ 974 VCBATT1_a481_LVBridgeCloseDBG "VCBATT1 ECU: a481 LV bridge close DBG";
CM_ SG_ 974 VCBATT1_a482_lvBridgeEFuseTrip "VCBATT1 ECU: a482 lv bridge e fuse trip";
CM_ SG_ 974 VCBATT1_a483_vnf1048SelfTestFail "VCBATT1 ECU: a483 vnf1048 self test failure";
CM_ SG_ 974 VCBATT1_a484_undervoltageSelfTes "VCBATT1 ECU: a484 undervoltage self test stuck on";
CM_ SG_ 974 VCBATT1_a485_uvSelfTestLoadUnatt "VCBATT1 ECU: a485 uv self test load unattempted on dbg";
CM_ SG_ 974 VCBATT1_a486_undervoltageSelfTes "VCBATT1 ECU: a486 undervoltage self test bridge sync failure";
CM_ SG_ 974 VCBATT1_a489_vnf1248SelfTestDebu "VCBATT1 ECU: a489 vnf1248 self test debug";
CM_ SG_ 974 VCBATT1_a490_vnf1248SelfTestFail "VCBATT1 ECU: a490 vnf1248 self test failure";
CM_ SG_ 974 VCBATT1_a491_vnf1248Configuratio "VCBATT1 ECU: a491 vnf1248 configuration mismatch";
CM_ SG_ 974 VCBATT1_a492_TLVBMS_SocImbalance "VCBATT1 ECU: a492 TLVBMS soc imbalance";
CM_ SG_ 974 VCBATT1_a493_TLVBMS_SocImbalance "VCBATT1 ECU: a493 TLVBMS soc imbalance warning";
CM_ SG_ 974 VCBATT1_a494_LVBatteryTempBlocki "VCBATT1 ECU: a494 LV battery temp blocking OTA";
CM_ SG_ 974 VCBATT1_a495_LVBatteryRecoveryBl "VCBATT1 ECU: a495 LV battery recovery blocked";
CM_ SG_ 974 VCBATT1_a496_LVBatteryExitDriveW "VCBATT1 ECU: a496 LV battery exit drive warning";
CM_ SG_ 974 VCBATT1_a497_LVBatteryWarnDiscon "VCBATT1 ECU: a497 LV battery warn disconnect";
CM_ SG_ 974 VCBATT1_a498_TLVBMS_ImpedanceTes "VCBATT1 ECU: a498 TLVBMS impedance test results";
CM_ SG_ 974 VCBATT1_a500_eFuseASICStateMisma "VCBATT1 ECU: a500 e fuse ASIC state mismatch";
CM_ SG_ 974 VCBATT1_a501_vnf1048Configuratio "VCBATT1 ECU: a501 vnf1048 configuration mismatch";
CM_ SG_ 974 VCBATT1_a502_TLVBMS_WeakShortImp "VCBATT1 ECU: a502 TLVBMS weak short impedance";
CM_ SG_ 974 VCBATT1_a503_TLVBMS_BrickExtende "VCBATT1 ECU: a503 TLVBMS brick extended ov fault";
CM_ SG_ 974 VCBATT1_a508_TLVBMS_ImpedanceGro "VCBATT1 ECU: a508 TLVBMS impedance growth";
CM_ SG_ 974 VCBATT1_a509_eFuseASICManagerSta "VCBATT1 ECU: a509 e fuse ASIC manager state mismatch";
CM_ SG_ 974 VCBATT1_a510_LVBatteryRecoveryTi "VCBATT1 ECU: a510 LV battery recovery timeout";
CM_ SG_ 974 VCBATT1_a512_LVBMSFault_MOS_Open "VCBATT1 ECU: a512 LVBMS fault MOS open hardware OC";
CM_ SG_ 974 VCBATT1_a513_LVBMSFault_MOS_Open "VCBATT1 ECU: a513 LVBMS fault MOS open chg OC";
CM_ SG_ 974 VCBATT1_a514_LVBMSFault_MOS_Open "VCBATT1 ECU: a514 LVBMS fault MOS open cell UV";
CM_ SG_ 974 VCBATT1_a515_LVBMSFault_MOS_Open "VCBATT1 ECU: a515 LVBMS fault MOS open cell OV";
CM_ SG_ 974 VCBATT1_a518_LVBMSFault_MOS_Open "VCBATT1 ECU: a518 LVBMS fault MOS open pack OV";
CM_ SG_ 974 VCBATT1_a521_vcleftEFuseLoadShed "VCBATT1 ECU: a521 vcleft e fuse load shed";
CM_ SG_ 974 VCBATT1_a523_eFuseThresholdsInco "VCBATT1 ECU: a523 e fuse thresholds incorrect";
CM_ SG_ 974 VCBATT1_a525_LVBatterySWMisconfi "VCBATT1 ECU: a525 LV battery SW misconfiguration";
CM_ SG_ 974 VCBATT1_a527_LVBatteryCellImbala "VCBATT1 ECU: a527 LV battery cell imbalance";
CM_ SG_ 974 VCBATT1_a528_LVBatteryCommsDiscn "VCBATT1 ECU: a528 LV battery comms discnctd";
CM_ SG_ 974 VCBATT1_a529_discnctdBatteryStat "VCBATT1 ECU: a529 discnctd battery state unknown";
CM_ SG_ 974 VCBATT1_a533_TLVBMS_MosfetOverTe "VCBATT1 ECU: a533 TLVBMS mosfet over temperature fault";
CM_ SG_ 974 VCBATT1_a541_LVBatteryChargeOCLe "VCBATT1 ECU: a541 LV battery charge OC level1";
CM_ SG_ 974 VCBATT1_a544_LVBatteryCommsBusTu "VCBATT1 ECU: a544 LV battery comms bus turned off";
CM_ SG_ 974 VCBATT1_a545_LVBatteryTypeUnknow "VCBATT1 ECU: a545 LV battery type unknown";
CM_ SG_ 974 VCBATT1_a548_HVFaultLoadShed "VCBATT1 ECU: a548 HV fault load shed";
CM_ SG_ 974 VCBATT1_a555_LVBatteryCellRebala "VCBATT1 ECU: a555 LV battery cell rebalancing";
CM_ SG_ 974 VCBATT1_a556_falseTriggerOfDiscn "VCBATT1 ECU: a556 false trigger of discnctd battery test";
CM_ SG_ 974 VCBATT1_a559_LVBatteryLowSOC "VCBATT1 ECU: a559 LV battery low SOC";
CM_ SG_ 974 VCBATT1_a561_LVBMSEFuseOvertempe "VCBATT1 ECU: a561 LVBMSE fuse overtemperature";
CM_ SG_ 974 VCBATT1_a562_LVBMSModuleOvertemp "VCBATT1 ECU: a562 LVBMS module overtemperature";
CM_ SG_ 974 VCBATT1_a573_radarEFuseTrip "VCBATT1 ECU: a573 radar e fuse trip";
CM_ SG_ 974 VCBATT1_a575_vbatFusedLoadShedEF "VCBATT1 ECU: a575 vbat fused load shed e fuse trip";
CM_ SG_ 974 VCBATT1_a576_mcuLogicEFuseTrip "VCBATT1 ECU: a576 mcu logic e fuse trip";
CM_ SG_ 974 VCBATT1_a580_rightHeadlightEFuse "VCBATT1 ECU: a580 right headlight e fuse trip";
CM_ SG_ 974 VCBATT1_a581_harnessResistanceIn "VCBATT1 ECU: a581 harness resistance info";
CM_ SG_ 974 VCBATT1_a582_goodForPCSPowerCycl "VCBATT1 ECU: a582 good for PCS power cycle";
CM_ SG_ 974 VCBATT1_a585_lvBatteryHealthTest "VCBATT1 ECU: a585 lv battery health test required";
CM_ SG_ 974 VCBATT1_a587_externalLVPowerSupp "VCBATT1 ECU: a587 external LV power supply";
CM_ SG_ 974 VCBATT1_a588_vcleftPwrRationalit "VCBATT1 ECU: a588 vcleft pwr rationality curve";
CM_ SG_ 974 VCBATT1_a589_vcleftFastBlowDetec "VCBATT1 ECU: a589 vcleft fast blow detection";
CM_ SG_ 974 VCBATT1_a592_vcleftCurvePowerCut "VCBATT1 ECU: a592 vcleft curve power cutoff";
CM_ SG_ 974 VCBATT1_a593_vcleftFastBlowPower "VCBATT1 ECU: a593 vcleft fast blow power cutoff";
CM_ SG_ 974 VCBATT1_a595_voltageSensorMismat "VCBATT1 ECU: a595 voltage sensor mismatch";
CM_ SG_ 974 VCBATT1_a597_LVBMBeFuseSelfTestN "VCBATT1 ECU: a597 LVBM be fuse self test not ready";
CM_ SG_ 974 VCBATT1_a598_LVBMBeFuseSelfTestF "VCBATT1 ECU: a598 LVBM be fuse self test failed";
CM_ SG_ 974 VCBATT1_a599_LVBatteryTypeUnsupp "VCBATT1 ECU: a599 LV battery type unsupported";
CM_ SG_ 974 VCBATT1_a600_currentSensorMismat "VCBATT1 ECU: a600 current sensor mismatch";
CM_ SG_ 974 VCBATT1_a601_LVBatteryHeaterNotP "VCBATT1 ECU: a601 LV battery heater not present";
CM_ SG_ 974 VCBATT1_a608_TLVBMS_BleedFetFail "VCBATT1 ECU: a608 TLVBMS bleed fet failure";
CM_ SG_ 974 VCBATT1_a615_TLVBMS_BatteryHeate "VCBATT1 ECU: a615 TLVBMS battery heater fault";
CM_ SG_ 974 VCBATT1_a617_APP_MIA "VCBATT1 ECU: a617 APP MIA";
CM_ SG_ 974 VCBATT1_a628_TLVBMS_BmbThermisto "VCBATT1 ECU: a628 TLVBMS bmb thermistor fault";
CM_ SG_ 974 VCBATT1_a629_TLVBMS_PackTemperat "VCBATT1 ECU: a629 TLVBMS pack temperature irrational";
CM_ SG_ 974 VCBATT1_a670_TLVBMS_EfuseStateIr "VCBATT1 ECU: a670 TLVBMS efuse state irrational";
CM_ SG_ 974 VCBATT1_a672_LVBatteryVitals "VCBATT1 ECU: a672 LV battery vitals";
CM_ BO_ 1030 "VCBATT1 ECU message: e fuse debug status";
CM_ SG_ 1030 VCBATT1_eFuseDebugStatusIndex "VCBATT1 ECU: e fuse debug status index";
CM_ SG_ 1030 VCBATT1_leftControllerEFuseState "VCBATT1 ECU: left controller e fuse state";
CM_ SG_ 1030 VCBATT1_leftControllerEFuseCurre "VCBATT1 ECU: left controller e fuse current";
CM_ SG_ 1030 VCBATT1_leftControllerEFuseOutpu "VCBATT1 ECU: left controller e fuse output";
CM_ SG_ 1030 VCBATT1_leftControllerEFuse_0002 "VCBATT1 ECU: left controller e fuse output desired";
CM_ SG_ 1030 VCBATT1_leftControllerEFuseBypas "VCBATT1 ECU: left controller e fuse bypass";
CM_ SG_ 1030 VCBATT1_leftControllerEFuse_0001 "VCBATT1 ECU: left controller e fuse bypass desired";
CM_ SG_ 1030 VCBATT1_leftControllerEFuseVolta "VCBATT1 ECU: left controller e fuse voltage";
CM_ SG_ 1030 VCBATT1_leftControllerEFuseTempe "VCBATT1 ECU: left controller e fuse temperature";
CM_ SG_ 1030 VCBATT1_leftControllerEFuseManag "VCBATT1 ECU: left controller e fuse manager state";
CM_ SG_ 1030 VCBATT1_leftControllerEFuseHardS "VCBATT1 ECU: left controller e fuse hard short threshold";
CM_ SG_ 1030 VCBATT1_leftControllerEFuseOCThr "VCBATT1 ECU: left controller e fuse OC threshold";
CM_ SG_ 1030 VCBATT1_leftControllerEFuseType "Reports the type of the left controller eFuse.";
CM_ SG_ 1030 VCBATT1_EPAS1EFuseState "VCBATT1 ECU: EPAS1 e fuse state";
CM_ SG_ 1030 VCBATT1_EPAS1EFuseCurrent "VCBATT1 ECU: EPAS1 e fuse current";
CM_ SG_ 1030 VCBATT1_EPAS1EFuseOutput "VCBATT1 ECU: EPAS1 e fuse output";
CM_ SG_ 1030 VCBATT1_EPAS1EFuseOutputDesired "VCBATT1 ECU: EPAS1 e fuse output desired";
CM_ SG_ 1030 VCBATT1_EPAS1EFuseBypass "VCBATT1 ECU: EPAS1 e fuse bypass";
CM_ SG_ 1030 VCBATT1_EPAS1EFuseBypassDesired "VCBATT1 ECU: EPAS1 e fuse bypass desired";
CM_ SG_ 1030 VCBATT1_EPAS1EFuseVoltage "VCBATT1 ECU: EPAS1 e fuse voltage";
CM_ SG_ 1030 VCBATT1_EPAS1EFuseTemperature "VCBATT1 ECU: EPAS1 e fuse temperature";
CM_ SG_ 1030 VCBATT1_EPAS1EFuseManagerState "VCBATT1 ECU: EPAS1 e fuse manager state";
CM_ SG_ 1030 VCBATT1_EPAS1EFuseHardShortThres "VCBATT1 ECU: EPAS1 e fuse hard short threshold";
CM_ SG_ 1030 VCBATT1_EPAS1EFuseOCThreshold "VCBATT1 ECU: EPAS1 e fuse OC threshold";
CM_ SG_ 1030 VCBATT1_EPAS1EFuseType "Reports the type of the EPAS1 eFuse.";
CM_ SG_ 1030 VCBATT1_autopilot1EFuseState "VCBATT1 ECU: autopilot1 e fuse state";
CM_ SG_ 1030 VCBATT1_autopilot1EFuseCurrent "VCBATT1 ECU: autopilot1 e fuse current";
CM_ SG_ 1030 VCBATT1_autopilot1EFuseOutput "VCBATT1 ECU: autopilot1 e fuse output";
CM_ SG_ 1030 VCBATT1_autopilot1EFuseOutputDes "VCBATT1 ECU: autopilot1 e fuse output desired";
CM_ SG_ 1030 VCBATT1_autopilot1EFuseBypass "VCBATT1 ECU: autopilot1 e fuse bypass";
CM_ SG_ 1030 VCBATT1_autopilot1EFuseBypassDes "VCBATT1 ECU: autopilot1 e fuse bypass desired";
CM_ SG_ 1030 VCBATT1_autopilot1EFuseVoltage "VCBATT1 ECU: autopilot1 e fuse voltage";
CM_ SG_ 1030 VCBATT1_autopilot1EFuseTemperatu "VCBATT1 ECU: autopilot1 e fuse temperature";
CM_ SG_ 1030 VCBATT1_autopilot1EFuseManagerSt "VCBATT1 ECU: autopilot1 e fuse manager state";
CM_ SG_ 1030 VCBATT1_autopilot1EFuseHardShort "VCBATT1 ECU: autopilot1 e fuse hard short threshold";
CM_ SG_ 1030 VCBATT1_autopilot1EFuseOCThresho "VCBATT1 ECU: autopilot1 e fuse OC threshold";
CM_ SG_ 1030 VCBATT1_autopilot1EFuseType "Reports the type of the autopilot1 eFuse.";
CM_ BO_ 1549 "VCBATT1 ECU message: uds response";
CM_ SG_ 1549 VCBATT1_udsResponseData "VCBATT1 ECU: uds response data";
CM_ BO_ 1358 "VCBATT2 ECU message: alert log";
CM_ SG_ 1358 VCBATT2_alertID "VCBATT2 ECU: alert ID";
CM_ SG_ 1358 VCBATT2_alertState "VCBATT2 ECU: alert state";
CM_ SG_ 1358 VCBATT2_a001_InternalWatchdog "VCBATT2 ECU: a001 internal watchdog";
CM_ SG_ 1358 VCBATT2_a015_NVMMMemOverflow "VCBATT2 ECU: a015 NVMM mem overflow";
CM_ SG_ 1358 VCBATT2_a015_NVMMFilesystemError "VCBATT2 ECU: a015 NVMM filesystem error";
CM_ SG_ 1358 VCBATT2_a015_NVMMRecordIDError "VCBATT2 ECU: a015 NVMM record ID error";
CM_ SG_ 1358 VCBATT2_a059_voltageDrop "VCBATT2 ECU: a059 voltage drop";
CM_ SG_ 1358 VCBATT2_a059_resistanceEstimate "VCBATT2 ECU: a059 resistance estimate";
CM_ SG_ 1358 VCBATT2_a059_current "VCBATT2 ECU: a059 current";
CM_ SG_ 1358 VCBATT2_a063_switchChannel "VCBATT2 ECU: a063 switch channel";
CM_ SG_ 1358 VCBATT2_a063_switchType "VCBATT2 ECU: a063 switch type";
CM_ SG_ 1358 VCBATT2_a063_ADCVoltage "VCBATT2 ECU: a063 ADC voltage";
CM_ SG_ 1358 VCBATT2_a063_disconnected "VCBATT2 ECU: a063 disconnected";
CM_ SG_ 1358 VCBATT2_a063_indeterminate "VCBATT2 ECU: a063 indeterminate";
CM_ SG_ 1358 VCBATT2_a063_stuckActive "VCBATT2 ECU: a063 stuck active";
CM_ SG_ 1358 VCBATT2_a063_faulted "VCBATT2 ECU: a063 faulted";
CM_ SG_ 1358 VCBATT2_a091_FRONTIPC_faultsAndE "VCBATT2 ECU: a091 FRONTIPC faults and extras";
CM_ SG_ 1358 VCBATT2_a091_FRONTIPC_state "VCBATT2 ECU: a091 FRONTIPC state";
CM_ SG_ 1358 VCBATT2_a096_FRONTIPC_status "VCBATT2 ECU: a096 FRONTIPC status";
CM_ SG_ 1358 VCBATT2_a098_FRONTIPC_temperatur "VCBATT2 ECU: a098 FRONTIPC temperature";
CM_ SG_ 1358 VCBATT2_a098_FRONTIPC_thermalCon "VCBATT2 ECU: a098 FRONTIPC thermal control";
CM_ SG_ 1358 VCBATT2_a106_BATTIPC_dcdcRailSta "VCBATT2 ECU: a106 BATTIPC dcdc rail status";
CM_ SG_ 1358 VCBATT2_a106_BATTIPC_dcdcStatus "VCBATT2 ECU: a106 BATTIPC dcdc status";
CM_ SG_ 1358 VCBATT2_a106_VEH_dcdcStatus "VCBATT2 ECU: a106 VEH dcdc status";
CM_ SG_ 1358 VCBATT2_a106_VEH_thermalControl "VCBATT2 ECU: a106 VEH thermal control";
CM_ SG_ 1358 VCBATT2_a106_VEH_dcdcRailStatus "VCBATT2 ECU: a106 VEH dcdc rail status";
CM_ SG_ 1358 VCBATT2_a106_CH_dcdcRailStatus "VCBATT2 ECU: a106 CH dcdc rail status";
CM_ SG_ 1358 VCBATT2_a106_CH_alertMatrix "VCBATT2 ECU: a106 CH alert matrix";
CM_ SG_ 1358 VCBATT2_a106_FRONTIPC_thermalCon "VCBATT2 ECU: a106 FRONTIPC thermal control";
CM_ SG_ 1358 VCBATT2_a106_FRONTIPC_dcdcRailSt "VCBATT2 ECU: a106 FRONTIPC dcdc rail status";
CM_ SG_ 1358 VCBATT2_a106_FRONTIPC_dcdcStatus "VCBATT2 ECU: a106 FRONTIPC dcdc status";
CM_ SG_ 1358 VCBATT2_a108_FRONTIPC_status "VCBATT2 ECU: a108 FRONTIPC status";
CM_ SG_ 1358 VCBATT2_a108_FRONTIPC_temperatur "VCBATT2 ECU: a108 FRONTIPC temperature";
CM_ SG_ 1358 VCBATT2_a108_FRONTIPC_thermalCon "VCBATT2 ECU: a108 FRONTIPC thermal control";
CM_ SG_ 1358 VCBATT2_a108_FRONTIPC_motorStatu "VCBATT2 ECU: a108 FRONTIPC motor status";
CM_ SG_ 1358 VCBATT2_a120_BATTIPC_speed "VCBATT2 ECU: a120 BATTIPC speed";
CM_ SG_ 1358 VCBATT2_a120_FRONTIPC_speed "VCBATT2 ECU: a120 FRONTIPC speed";
CM_ SG_ 1358 VCBATT2_a120_FRONTIPC_systemStat "VCBATT2 ECU: a120 FRONTIPC system status";
CM_ SG_ 1358 VCBATT2_a120_BATTIPC_systemStatu "VCBATT2 ECU: a120 BATTIPC system status";
CM_ SG_ 1358 VCBATT2_a120_FRONTIPC_systemPowe "VCBATT2 ECU: a120 FRONTIPC system power";
CM_ SG_ 1358 VCBATT2_a120_FRONTIPC_autonomyHe "VCBATT2 ECU: a120 FRONTIPC autonomy health";
CM_ SG_ 1358 VCBATT2_a120_BATTIPC_chassisCont "VCBATT2 ECU: a120 BATTIPC chassis control2";
CM_ SG_ 1358 VCBATT2_a120_FRONTIPC_chassisCon "VCBATT2 ECU: a120 FRONTIPC chassis control2";
CM_ SG_ 1358 VCBATT2_a120_FRONTIPC_odometerSt "VCBATT2 ECU: a120 FRONTIPC odometer status";
CM_ SG_ 1358 VCBATT2_a124_FRONTIPC_status "VCBATT2 ECU: a124 FRONTIPC status";
CM_ SG_ 1358 VCBATT2_a124_BATTIPC_status "VCBATT2 ECU: a124 BATTIPC status";
CM_ SG_ 1358 VCBATT2_a125_FRONTIPC_leftStalk "VCBATT2 ECU: a125 FRONTIPC left stalk";
CM_ SG_ 1358 VCBATT2_a125_FRONTIPC_steerAngle "VCBATT2 ECU: a125 FRONTIPC steer angle";
CM_ SG_ 1358 VCBATT2_a125_FRONTIPC_info "VCBATT2 ECU: a125 FRONTIPC info";
CM_ SG_ 1358 VCBATT2_a126_FRONTIPC_sysStatus "VCBATT2 ECU: a126 FRONTIPC sys status";
CM_ SG_ 1358 VCBATT2_a126_BATTIPC_sysStatus "VCBATT2 ECU: a126 BATTIPC sys status";
CM_ SG_ 1358 VCBATT2_a126_FRONTIPC_status "VCBATT2 ECU: a126 FRONTIPC status";
CM_ SG_ 1358 VCBATT2_a126_BATTIPC_status "VCBATT2 ECU: a126 BATTIPC status";
CM_ SG_ 1358 VCBATT2_a131_FRONTIPC_power "VCBATT2 ECU: a131 FRONTIPC power";
CM_ SG_ 1358 VCBATT2_a131_BATTIPC_power "VCBATT2 ECU: a131 BATTIPC power";
CM_ SG_ 1358 VCBATT2_a133_BATTIPC_primaryActu "VCBATT2 ECU: a133 BATTIPC primary actuator";
CM_ SG_ 1358 VCBATT2_a133_FRONTIPC_secondaryA "VCBATT2 ECU: a133 FRONTIPC secondary actuator";
CM_ SG_ 1358 VCBATT2_a144_FRONTIPC_status "VCBATT2 ECU: a144 FRONTIPC status";
CM_ SG_ 1358 VCBATT2_a144_BATTIPC_status "VCBATT2 ECU: a144 BATTIPC status";
CM_ SG_ 1358 VCBATT2_a156_motorCounts "VCBATT2 ECU: a156 motor counts";
CM_ SG_ 1358 VCBATT2_a157_motorCounts "VCBATT2 ECU: a157 motor counts";
CM_ SG_ 1358 VCBATT2_a181_vehicleState "VCBATT2 ECU: a181 vehicle state";
CM_ SG_ 1358 VCBATT2_a188_sleepBypassCurrent "VCBATT2 ECU: a188 sleep bypass current";
CM_ SG_ 1358 VCBATT2_a188_sleepShutdownStep "VCBATT2 ECU: a188 sleep shutdown step; raw 3 = signal not available (SNA)";
CM_ SG_ 1358 VCBATT2_a188_vehiclePowerState "VCBATT2 ECU: a188 vehicle power state";
CM_ SG_ 1358 VCBATT2_a188_timeNotSleeping "VCBATT2 ECU: a188 time not sleeping";
CM_ SG_ 1358 VCBATT2_a188_CANAfterQuiet "VCBATT2 ECU: a188 CAN after quiet";
CM_ SG_ 1358 VCBATT2_a192_vehiclePowerState "VCBATT2 ECU: a192 vehicle power state";
CM_ SG_ 1358 VCBATT2_a192_hvState "VCBATT2 ECU: a192 hv state";
CM_ SG_ 1358 VCBATT2_a192_notEnoughPowerForSu "VCBATT2 ECU: a192 not enough power for support";
CM_ SG_ 1358 VCBATT2_a192_pcsEFuseStable "VCBATT2 ECU: a192 pcs e fuse stable";
CM_ SG_ 1358 VCBATT2_a192_vcrightEFuseStable "VCBATT2 ECU: a192 vcright e fuse stable";
CM_ SG_ 1358 VCBATT2_a192_contactorEFuseStabl "VCBATT2 ECU: a192 contactor e fuse stable";
CM_ SG_ 1358 VCBATT2_a192_hvcEFuseStable "VCBATT2 ECU: a192 hvc e fuse stable";
CM_ SG_ 1358 VCBATT2_a192_replaceLVBattery "VCBATT2 ECU: a192 replace LV battery";
CM_ SG_ 1358 VCBATT2_a192_BMS_MIA "VCBATT2 ECU: a192 BMS MIA";
CM_ SG_ 1358 VCBATT2_a192_PCS_MIA "VCBATT2 ECU: a192 PCS MIA";
CM_ SG_ 1358 VCBATT2_a192_HVBlockingMismatch "VCBATT2 ECU: a192 HV blocking mismatch";
CM_ SG_ 1358 VCBATT2_a192_disconnected12V "VCBATT2 ECU: a192 disconnected12 v";
CM_ SG_ 1358 VCBATT2_a192_LVBatteryCannotSupp "VCBATT2 ECU: a192 LV battery cannot support vehicle";
CM_ SG_ 1358 VCBATT2_a192_DI_gear "VCBATT2 ECU: a192 DI gear; raw 7 = signal not available (SNA)";
CM_ SG_ 1358 VCBATT2_a192_GTW_factoryGated "VCBATT2 ECU: a192 GTW factory gated";
CM_ SG_ 1358 VCBATT2_a192_GTW_updateStarted "VCBATT2 ECU: a192 GTW update started";
CM_ SG_ 1358 VCBATT2_a192_serviceMode "Signal reported by VCBATT2 ECU";
CM_ SG_ 1358 VCBATT2_a192_frunkOpen "VCBATT2 ECU: a192 frunk open";
CM_ SG_ 1358 VCBATT2_a192_IBSCurrent "VCBATT2 ECU: a192 IBS current";
CM_ SG_ 1358 VCBATT2_a192_PCSCurrent "VCBATT2 ECU: a192 PCS current";
CM_ SG_ 1358 VCBATT2_a192_HVFaultLoadShedActi "VCBATT2 ECU: a192 HV fault load shed active";
CM_ SG_ 1358 VCBATT2_a192_postCrashLoadShedAc "VCBATT2 ECU: a192 post crash load shed active";
CM_ SG_ 1358 VCBATT2_a227_motorFaulted "VCBATT2 ECU: a227 motor faulted";
CM_ SG_ 1358 VCBATT2_a227_motorLocked "VCBATT2 ECU: a227 motor locked";
CM_ SG_ 1358 VCBATT2_a227_ecuReset "VCBATT2 ECU: a227 ecu reset";
CM_ SG_ 1358 VCBATT2_a227_fetTempIrrational "VCBATT2 ECU: a227 fet temp irrational";
CM_ SG_ 1358 VCBATT2_a227_motorControlError "VCBATT2 ECU: a227 motor control error";
CM_ SG_ 1358 VCBATT2_a227_underVoltage "VCBATT2 ECU: a227 under voltage";
CM_ SG_ 1358 VCBATT2_a227_overVoltage "VCBATT2 ECU: a227 over voltage";
CM_ SG_ 1358 VCBATT2_a227_hardwareOvercurrent "VCBATT2 ECU: a227 hardware overcurrent";
CM_ SG_ 1358 VCBATT2_a227_motorOpenPhase "VCBATT2 ECU: a227 motor open phase";
CM_ SG_ 1358 VCBATT2_a227_motorSoftOpenPhase "VCBATT2 ECU: a227 motor soft open phase";
CM_ SG_ 1358 VCBATT2_a227_motorOvertemp "VCBATT2 ECU: a227 motor overtemp";
CM_ SG_ 1358 VCBATT2_a227_dcOvercurrent "VCBATT2 ECU: a227 dc overcurrent";
CM_ SG_ 1358 VCBATT2_a227_motorStalled "VCBATT2 ECU: a227 motor stalled";
CM_ SG_ 1358 VCBATT2_a227_selfTestFailed "VCBATT2 ECU: a227 self test failed";
CM_ SG_ 1358 VCBATT2_a227_selfTestResult "VCBATT2 ECU: a227 self test result";
CM_ SG_ 1358 VCBATT2_a227_linChecksumError "VCBATT2 ECU: a227 lin checksum error";
CM_ SG_ 1358 VCBATT2_a227_linFramingError "VCBATT2 ECU: a227 lin framing error";
CM_ SG_ 1358 VCBATT2_a227_phaseShorted "VCBATT2 ECU: a227 phase shorted";
CM_ SG_ 1358 VCBATT2_a227_busVoltageIrrationa "VCBATT2 ECU: a227 bus voltage irrational";
CM_ SG_ 1358 VCBATT2_a227_dcCurrentIrrational "VCBATT2 ECU: a227 dc current irrational";
CM_ SG_ 1358 VCBATT2_a227_motorSpeedIrrationa "VCBATT2 ECU: a227 motor speed irrational";
CM_ SG_ 1358 VCBATT2_a227_supplyVoltageIrrati "VCBATT2 ECU: a227 supply voltage irrational";
CM_ SG_ 1358 VCBATT2_a227_motorPhaseCurrentIr "VCBATT2 ECU: a227 motor phase current irrational";
CM_ SG_ 1358 VCBATT2_a227_chipOvertemp "VCBATT2 ECU: a227 chip overtemp";
CM_ SG_ 1358 VCBATT2_a227_motorSpeedTooHigh "VCBATT2 ECU: a227 motor speed too high";
CM_ SG_ 1358 VCBATT2_a227_phaseOvercurrent "VCBATT2 ECU: a227 phase overcurrent";
CM_ SG_ 1358 VCBATT2_a227_vddaOvercurrent "VCBATT2 ECU: a227 vdda overcurrent";
CM_ SG_ 1358 VCBATT2_a227_busVoltageUnhealthy "VCBATT2 ECU: a227 bus voltage unhealthy";
CM_ SG_ 1358 VCBATT2_a227_hsVdsOvervoltage "VCBATT2 ECU: a227 hs vds overvoltage";
CM_ SG_ 1358 VCBATT2_a227_hsVdsOvervoltageMas "VCBATT2 ECU: a227 hs vds overvoltage mask";
CM_ SG_ 1358 VCBATT2_a227_lsVdsOvervoltage "VCBATT2 ECU: a227 ls vds overvoltage";
CM_ SG_ 1358 VCBATT2_a227_lsVdsOvervoltageMas "VCBATT2 ECU: a227 ls vds overvoltage mask";
CM_ SG_ 1358 VCBATT2_a227_payloadBitsNotSet "VCBATT2 ECU: a227 payload bits not set";
CM_ SG_ 1358 VCBATT2_a300_oldType "VCBATT2 ECU: a300 old type";
CM_ SG_ 1358 VCBATT2_a300_newType "VCBATT2 ECU: a300 new type";
CM_ SG_ 1358 VCBATT2_a303_vehicleSpeed "VCBATT2 ECU: a303 vehicle speed";
CM_ SG_ 1358 VCBATT2_a303_postVoltage "VCBATT2 ECU: a303 post voltage";
CM_ SG_ 1358 VCBATT2_a303_lockStatus "VCBATT2 ECU: a303 lock status; raw 0 = signal not available (SNA)";
CM_ SG_ 1358 VCBATT2_a304_voltage "VCBATT2 ECU: a304 voltage";
CM_ SG_ 1358 VCBATT2_a304_temperature "VCBATT2 ECU: a304 temperature";
CM_ SG_ 1358 VCBATT2_a305_voltage "VCBATT2 ECU: a305 voltage";
CM_ SG_ 1358 VCBATT2_a305_temperature "VCBATT2 ECU: a305 temperature";
CM_ SG_ 1358 VCBATT2_a305_actuatorCurrent "VCBATT2 ECU: a305 actuator current";
CM_ SG_ 1358 VCBATT2_a306_voltage "VCBATT2 ECU: a306 voltage";
CM_ SG_ 1358 VCBATT2_a306_temperature "VCBATT2 ECU: a306 temperature";
CM_ SG_ 1358 VCBATT2_a306_actuatorCurrent "VCBATT2 ECU: a306 actuator current";
CM_ SG_ 1358 VCBATT2_a309_vehicleSpeed "VCBATT2 ECU: a309 vehicle speed";
CM_ SG_ 1358 VCBATT2_a309_switchVoltage "VCBATT2 ECU: a309 switch voltage";
CM_ SG_ 1358 VCBATT2_a309_lockStatus "VCBATT2 ECU: a309 lock status; raw 0 = signal not available (SNA)";
CM_ SG_ 1358 VCBATT2_a353_wiperHeaterCurrent "VCBATT2 ECU: a353 wiper heater current";
CM_ SG_ 1358 VCBATT2_a353_batteryVoltage "VCBATT2 ECU: a353 battery voltage";
CM_ SG_ 1358 VCBATT2_a353_ambientTemperature "VCBATT2 ECU: a353 ambient temperature; raw 0 = signal not available (SNA)";
CM_ SG_ 1358 VCBATT2_a354_windshieldCameraHea "VCBATT2 ECU: a354 windshield camera heater current";
CM_ SG_ 1358 VCBATT2_a354_batteryVoltage "VCBATT2 ECU: a354 battery voltage";
CM_ SG_ 1358 VCBATT2_a354_ambientTemperature "VCBATT2 ECU: a354 ambient temperature; raw 0 = signal not available (SNA)";
CM_ SG_ 1358 VCBATT2_a389_closedAtSpeed "VCBATT2 ECU: a389 closed at speed";
CM_ SG_ 1358 VCBATT2_a389_faultedWhileOpenAtS "VCBATT2 ECU: a389 faulted while open at speed";
CM_ SG_ 1358 VCBATT2_a389_possiblyStuckClosed "VCBATT2 ECU: a389 possibly stuck closed";
CM_ SG_ 1358 VCBATT2_a389_vehicleSpeed "VCBATT2 ECU: a389 vehicle speed";
CM_ SG_ 1358 VCBATT2_a389_temperature "VCBATT2 ECU: a389 temperature";
CM_ SG_ 1358 VCBATT2_a389_latchStatus "VCBATT2 ECU: a389 latch status; raw 0 = signal not available (SNA)";
CM_ SG_ 1358 VCBATT2_a391_switchMismatch "VCBATT2 ECU: a391 switch mismatch";
CM_ SG_ 1358 VCBATT2_a391_switch1Shorted "VCBATT2 ECU: a391 switch1 shorted";
CM_ SG_ 1358 VCBATT2_a391_switch1Disconnected "VCBATT2 ECU: a391 switch1 disconnected";
CM_ SG_ 1358 VCBATT2_a391_switch2Shorted "VCBATT2 ECU: a391 switch2 shorted";
CM_ SG_ 1358 VCBATT2_a391_switch2Disconnected "VCBATT2 ECU: a391 switch2 disconnected";
CM_ SG_ 1358 VCBATT2_a391_switch1VoltageAvera "VCBATT2 ECU: a391 switch1 voltage average";
CM_ SG_ 1358 VCBATT2_a391_switch1VoltageInsta "VCBATT2 ECU: a391 switch1 voltage instant";
CM_ SG_ 1358 VCBATT2_a391_switch2VoltageAvera "VCBATT2 ECU: a391 switch2 voltage average";
CM_ SG_ 1358 VCBATT2_a391_switch2VoltageInsta "VCBATT2 ECU: a391 switch2 voltage instant";
CM_ SG_ 1358 VCBATT2_a463_switchMismatch "VCBATT2 ECU: a463 switch mismatch";
CM_ SG_ 1358 VCBATT2_a463_switch1Shorted "VCBATT2 ECU: a463 switch1 shorted";
CM_ SG_ 1358 VCBATT2_a463_switch1Disconnected "VCBATT2 ECU: a463 switch1 disconnected";
CM_ SG_ 1358 VCBATT2_a463_switch2Shorted "VCBATT2 ECU: a463 switch2 shorted";
CM_ SG_ 1358 VCBATT2_a463_switch2Disconnected "VCBATT2 ECU: a463 switch2 disconnected";
CM_ SG_ 1358 VCBATT2_a463_switch1VoltageAvera "VCBATT2 ECU: a463 switch1 voltage average";
CM_ SG_ 1358 VCBATT2_a463_switch1VoltageInsta "VCBATT2 ECU: a463 switch1 voltage instant";
CM_ SG_ 1358 VCBATT2_a463_switch2VoltageAvera "VCBATT2 ECU: a463 switch2 voltage average";
CM_ SG_ 1358 VCBATT2_a463_switch2VoltageInsta "VCBATT2 ECU: a463 switch2 voltage instant";
CM_ SG_ 1358 VCBATT2_a485_mcuGamingEFuseCurre "VCBATT2 ECU: a485 mcu gaming e fuse current";
CM_ SG_ 1358 VCBATT2_a516_IBSVoltage "VCBATT2 ECU: a516 IBS voltage";
CM_ SG_ 1358 VCBATT2_a516_HVSoc "VCBATT2 ECU: a516 HV soc";
CM_ SG_ 1358 VCBATT2_a516_contactorsPermanent "VCBATT2 ECU: a516 contactors permanently closed";
CM_ SG_ 1358 VCBATT2_a516_LVBatteryDisconnect "VCBATT2 ECU: a516 LV battery disconnected";
CM_ SG_ 1358 VCBATT2_a516_reverseBatteryFault "VCBATT2 ECU: a516 reverse battery fault";
CM_ SG_ 1358 VCBATT2_a516_LVBatteryCannotSupp "VCBATT2 ECU: a516 LV battery cannot support vehicle";
CM_ SG_ 1358 VCBATT2_a517_IBSVoltage "VCBATT2 ECU: a517 IBS voltage";
CM_ SG_ 1358 VCBATT2_a517_HVSoc "VCBATT2 ECU: a517 HV soc";
CM_ SG_ 1358 VCBATT2_a522_IBSVoltage "VCBATT2 ECU: a522 IBS voltage";
CM_ SG_ 1358 VCBATT2_a522_HVSoc "VCBATT2 ECU: a522 HV soc";
CM_ SG_ 1358 VCBATT2_a522_contactorsPermanent "VCBATT2 ECU: a522 contactors permanently closed";
CM_ SG_ 1358 VCBATT2_a522_LVBatteryDisconnect "VCBATT2 ECU: a522 LV battery disconnected";
CM_ SG_ 1358 VCBATT2_a522_reverseBatteryFault "VCBATT2 ECU: a522 reverse battery fault";
CM_ SG_ 1358 VCBATT2_a522_LVBatteryCannotSupp "VCBATT2 ECU: a522 LV battery cannot support vehicle";
CM_ SG_ 1358 VCBATT2_a547_serviceMode "Signal reported by VCBATT2 ECU";
CM_ SG_ 1358 VCBATT2_a547_frunkOpen "VCBATT2 ECU: a547 frunk open";
CM_ SG_ 1358 VCBATT2_a548_vehiclePowerState "VCBATT2 ECU: a548 vehicle power state";
CM_ SG_ 1358 VCBATT2_a548_notEnoughPowerForSu "VCBATT2 ECU: a548 not enough power for support";
CM_ SG_ 1358 VCBATT2_a548_HVBlockingMismatch "VCBATT2 ECU: a548 HV blocking mismatch";
CM_ SG_ 1358 VCBATT2_a548_LVBatteryCannotSupp "VCBATT2 ECU: a548 LV battery cannot support vehicle";
CM_ SG_ 1358 VCBATT2_a548_DI_gear "VCBATT2 ECU: a548 DI gear; raw 7 = signal not available (SNA)";
CM_ SG_ 1358 VCBATT2_a548_backstopBucketCount "VCBATT2 ECU: a548 backstop bucket count";
CM_ SG_ 1358 VCBATT2_a548_hvState "VCBATT2 ECU: a548 hv state";
CM_ SG_ 1358 VCBATT2_a548_BMS_MIA "VCBATT2 ECU: a548 BMS MIA";
CM_ SG_ 1358 VCBATT2_a548_PCS_MIA "VCBATT2 ECU: a548 PCS MIA";
CM_ SG_ 1358 VCBATT2_a548_ampHourBucketCount "VCBATT2 ECU: a548 amp hour bucket count";
CM_ SG_ 1358 VCBATT2_a548_LVBMSSOC "VCBATT2 ECU: a548 LVBMSSOC";
CM_ SG_ 1358 VCBATT2_a548_serviceMode "Signal reported by VCBATT2 ECU";
CM_ SG_ 1358 VCBATT2_a548_frunkOpen "VCBATT2 ECU: a548 frunk open";
CM_ SG_ 1358 VCBATT2_a548_PCSTargetVoltage "VCBATT2 ECU: a548 PCS target voltage";
CM_ SG_ 1358 VCBATT2_a548_ampHourBucketFilled "VCBATT2 ECU: a548 amp hour bucket filled";
CM_ SG_ 1358 VCBATT2_a548_HVNotConfirmedUpTri "VCBATT2 ECU: a548 HV not confirmed up trigger";
CM_ SG_ 1358 VCBATT2_a548_PCSNotMeetingTarget "VCBATT2 ECU: a548 PCS not meeting target trigger";
CM_ SG_ 1358 VCBATT2_a548_PCSMIATrigger "VCBATT2 ECU: a548 PCSMIA trigger";
CM_ SG_ 1358 VCBATT2_a548_PCSSaturatedTrigger "VCBATT2 ECU: a548 PCS saturated trigger";
CM_ SG_ 1358 VCBATT2_a548_backstopHit "VCBATT2 ECU: a548 backstop hit";
CM_ SG_ 1358 VCBATT2_a610_switch1State "VCBATT2 ECU: a610 switch1 state; raw 0 = signal not available (SNA)";
CM_ SG_ 1358 VCBATT2_a610_switch2State "VCBATT2 ECU: a610 switch2 state; raw 0 = signal not available (SNA)";
CM_ SG_ 1358 VCBATT2_a610_dataBufferBits "VCBATT2 ECU: a610 data buffer bits";
CM_ SG_ 1358 VCBATT2_a610_temperature "VCBATT2 ECU: a610 temperature; raw 0 = signal not available (SNA)";
CM_ SG_ 1358 VCBATT2_a668_hcmRegionAndSide "VCBATT2 ECU: a668 hcm region and side; raw 0 = signal not available (SNA)";
CM_ SG_ 1358 VCBATT2_a668_country "VCBATT2 ECU: a668 country";
CM_ SG_ 1358 VCBATT2_a668_homologationRegionO "VCBATT2 ECU: a668 homologation region override";
CM_ SG_ 1358 VCBATT2_a668_isRightHandDrive "VCBATT2 ECU: a668 is right hand drive";
CM_ SG_ 1358 VCBATT2_a698_isGlobalHeadlamps "VCBATT2 ECU: a698 is global headlamps";
CM_ SG_ 1358 VCBATT2_a698_isVirtualPitchSenso "VCBATT2 ECU: a698 is virtual pitch sensor";
CM_ SG_ 1358 VCBATT2_a698_calibratedVerticalP "VCBATT2 ECU: a698 calibrated vertical position HCMR; raw 1023 = signal not available (SNA)";
CM_ SG_ 1358 VCBATT2_a698_calibratedHorizonta "VCBATT2 ECU: a698 calibrated horizontal position HCMR; raw 1023 = signal not available (SNA)";
CM_ BO_ 975 "VCBATT2 ECU message: alert matrix";
CM_ SG_ 975 VCBATT2_matrixIndex "VCBATT2 ECU: matrix index";
CM_ SG_ 975 VCBATT2_a001_WatchdogReset "VCBATT2 ECU: a001 watchdog reset";
CM_ SG_ 975 VCBATT2_a002_PowerLossReset "VCBATT2 ECU: a002 power loss reset";
CM_ SG_ 975 VCBATT2_a003_SWAssertion "VCBATT2 ECU: a003 SW assertion";
CM_ SG_ 975 VCBATT2_a005_CANTXError "VCBATT2 ECU: a005 CANTX error";
CM_ SG_ 975 VCBATT2_a006_CANTX_cyclicError "VCBATT2 ECU: a006 CANTX cyclic error";
CM_ SG_ 975 VCBATT2_a012_CPUReset "VCBATT2 ECU: a012 CPU reset";
CM_ SG_ 975 VCBATT2_a013_AlertManagerFault "VCBATT2 ECU: a013 alert manager fault";
CM_ SG_ 975 VCBATT2_a015_NVMMError "VCBATT2 ECU: a015 NVMM error";
CM_ SG_ 975 VCBATT2_a016_NVMMRecordError "VCBATT2 ECU: a016 NVMM record error";
CM_ SG_ 975 VCBATT2_a017_NVMMStatusDbg "VCBATT2 ECU: a017 NVMM status dbg";
CM_ SG_ 975 VCBATT2_a018_HardFault "VCBATT2 ECU: a018 hard fault";
CM_ SG_ 975 VCBATT2_a019_BusFault "VCBATT2 ECU: a019 bus fault";
CM_ SG_ 975 VCBATT2_a021_TaskSchedulerError "VCBATT2 ECU: a021 task scheduler error";
CM_ SG_ 975 VCBATT2_a022_TaskInitError "VCBATT2 ECU: a022 task init error";
CM_ SG_ 975 VCBATT2_a028_UsageFault "VCBATT2 ECU: a028 usage fault";
CM_ SG_ 975 VCBATT2_a029_CoreDump "VCBATT2 ECU: a029 core dump";
CM_ SG_ 975 VCBATT2_a030_ECULogUploadRequest "VCBATT2 ECU: a030 ECU log upload request";
CM_ SG_ 975 VCBATT2_a031_UDSActive "VCBATT2 ECU: a031 UDS active";
CM_ SG_ 975 VCBATT2_a036_UnknownIrq "VCBATT2 ECU: a036 unknown irq";
CM_ SG_ 975 VCBATT2_a037_MemManageFault "VCBATT2 ECU: a037 mem manage fault";
CM_ SG_ 975 VCBATT2_a038_ProtFaultInfo "VCBATT2 ECU: a038 prot fault info";
CM_ SG_ 975 VCBATT2_a039_ProtFaultAddress "VCBATT2 ECU: a039 prot fault address";
CM_ SG_ 975 VCBATT2_a040_Backtrace "VCBATT2 ECU: a040 backtrace";
CM_ SG_ 975 VCBATT2_a041_HighCPULoad "VCBATT2 ECU: a041 high CPU load";
CM_ SG_ 975 VCBATT2_a042_HighStackUsage "VCBATT2 ECU: a042 high stack usage";
CM_ SG_ 975 VCBATT2_a043_Task1msError "VCBATT2 ECU: a043 task1ms error";
CM_ SG_ 975 VCBATT2_a044_Task10msError "VCBATT2 ECU: a044 task10ms error";
CM_ SG_ 975 VCBATT2_a045_Task100msError "VCBATT2 ECU: a045 task100ms error";
CM_ SG_ 975 VCBATT2_a046_Task1000msError "VCBATT2 ECU: a046 task1000ms error";
CM_ SG_ 975 VCBATT2_a058_inputRHighSyncDebug "VCBATT2 ECU: a058 input r high sync debug";
CM_ SG_ 975 VCBATT2_a059_inputResistanceHigh "VCBATT2 ECU: a059 input resistance high";
CM_ SG_ 975 VCBATT2_a060_engineeringBuild "VCBATT2 ECU: a060 engineering build";
CM_ SG_ 975 VCBATT2_a061_XCPConnected "VCBATT2 ECU: a061 XCP connected";
CM_ SG_ 975 VCBATT2_a062_XCPWasConnected "VCBATT2 ECU: a062 XCP was connected";
CM_ SG_ 975 VCBATT2_a063_SwitchFault "VCBATT2 ECU: a063 switch fault";
CM_ SG_ 975 VCBATT2_a064_busSleepReqTimeout "VCBATT2 ECU: a064 bus sleep req timeout";
CM_ SG_ 975 VCBATT2_a077_VCBATT0_MIA "VCBATT2 ECU: a077 VCBATT0 MIA";
CM_ SG_ 975 VCBATT2_a078_VCBATT1_MIA "VCBATT2 ECU: a078 VCBATT1 MIA";
CM_ SG_ 975 VCBATT2_a079_VCBATT2_MIA "VCBATT2 ECU: a079 VCBATT2 MIA";
CM_ SG_ 975 VCBATT2_a080_VCFRONT0_MIA "VCBATT2 ECU: a080 VCFRONT0 MIA";
CM_ SG_ 975 VCBATT2_a081_VCFRONT1_MIA "VCBATT2 ECU: a081 VCFRONT1 MIA";
CM_ SG_ 975 VCBATT2_a082_VCFRONT2_MIA "VCBATT2 ECU: a082 VCFRONT2 MIA";
CM_ SG_ 975 VCBATT2_a086_VCBATT_MIA "VCBATT2 ECU: a086 VCBATT MIA";
CM_ SG_ 975 VCBATT2_a090_APS_MIA "VCBATT2 ECU: a090 APS MIA";
CM_ SG_ 975 VCBATT2_a091_CMPD_MIA "VCBATT2 ECU: a091 CMPD MIA";
CM_ SG_ 975 VCBATT2_a096_OCS1P_MIA "VCBATT2 ECU: a096 OCS1 p MIA";
CM_ SG_ 975 VCBATT2_a098_DIR_MIA "VCBATT2 ECU: a098 DIR MIA";
CM_ SG_ 975 VCBATT2_a100_CANbus_MIA "VCBATT2 ECU: a100 CA nbus MIA";
CM_ SG_ 975 VCBATT2_a103_CP_MIA "VCBATT2 ECU: a103 CP MIA";
CM_ SG_ 975 VCBATT2_a104_DAS_MIA "VCBATT2 ECU: a104 DAS MIA";
CM_ SG_ 975 VCBATT2_a105_TAS_MIA "VCBATT2 ECU: a105 TAS MIA";
CM_ SG_ 975 VCBATT2_a106_PCS_MIA "VCBATT2 ECU: a106 PCS MIA";
CM_ SG_ 975 VCBATT2_a107_BMS_MIA "VCBATT2 ECU: a107 BMS MIA";
CM_ SG_ 975 VCBATT2_a108_DIF_MIA "VCBATT2 ECU: a108 DIF MIA";
CM_ SG_ 975 VCBATT2_a109_RCM_MIA "VCBATT2 ECU: a109 RCM MIA";
CM_ SG_ 975 VCBATT2_a110_GTW_MIA "VCBATT2 ECU: a110 GTW MIA";
CM_ SG_ 975 VCBATT2_a111_EPBR_MIA "VCBATT2 ECU: a111 EPBR MIA";
CM_ SG_ 975 VCBATT2_a112_EPBL_MIA "VCBATT2 ECU: a112 EPBL MIA";
CM_ SG_ 975 VCBATT2_a113_UI_MIA "VCBATT2 ECU: a113 UI MIA";
CM_ SG_ 975 VCBATT2_a114_ESP_MIA "VCBATT2 ECU: a114 ESP MIA";
CM_ SG_ 975 VCBATT2_a115_VCSEC_MIA "VCBATT2 ECU: a115 VCSEC MIA";
CM_ SG_ 975 VCBATT2_a116_VCRIGHT_MIA "VCBATT2 ECU: a116 VCRIGHT MIA";
CM_ SG_ 975 VCBATT2_a117_VCLEFT_MIA "VCBATT2 ECU: a117 VCLEFT MIA";
CM_ SG_ 975 VCBATT2_a118_VCFRONT_MIA "VCBATT2 ECU: a118 VCFRONT MIA";
CM_ SG_ 975 VCBATT2_a119_SCCM_MIA "VCBATT2 ECU: a119 SCCM MIA";
CM_ SG_ 975 VCBATT2_a120_DI_DRIVE_MIA "VCBATT2 ECU: a120 DI DRIVE MIA";
CM_ SG_ 975 VCBATT2_a122_ICR_MIA "VCBATT2 ECU: a122 ICR MIA";
CM_ SG_ 975 VCBATT2_a123_VC_SECONDARY_LIGHTI "VCBATT2 ECU: a123 VC SECONDARY LIGHTING LEADER MIA";
CM_ SG_ 975 VCBATT2_a124_BB_MIA "VCBATT2 ECU: a124 BB MIA";
CM_ SG_ 975 VCBATT2_a125_SCCM_MIA "VCBATT2 ECU: a125 SCCM MIA";
CM_ SG_ 975 VCBATT2_a126_EPAS3P_MIA "VCBATT2 ECU: a126 EPAS3 p MIA";
CM_ SG_ 975 VCBATT2_a131_PCSCOMMON_MIA "VCBATT2 ECU: a131 PCSCOMMON MIA";
CM_ SG_ 975 VCBATT2_a133_BRAKE_MIA "VCBATT2 ECU: a133 BRAKE MIA";
CM_ SG_ 975 VCBATT2_a143_powerLossDuringSlee "VCBATT2 ECU: a143 power loss during sleep";
CM_ SG_ 975 VCBATT2_a144_EPAS3S_MIA "VCBATT2 ECU: a144 EPAS3 s MIA";
CM_ SG_ 975 VCBATT2_a156_louverBlockage "VCBATT2 ECU: a156 louver blockage";
CM_ SG_ 975 VCBATT2_a157_louverBreakage "VCBATT2 ECU: a157 louver breakage";
CM_ SG_ 975 VCBATT2_a158_louverDisconnected "VCBATT2 ECU: a158 louver disconnected";
CM_ SG_ 975 VCBATT2_a166_rightHCMMIA "VCBATT2 ECU: a166 right HCMMIA";
CM_ SG_ 975 VCBATT2_a181_homelinkMIA "VCBATT2 ECU: a181 homelink MIA";
CM_ SG_ 975 VCBATT2_a185_washerFluidLow "VCBATT2 ECU: a185 washer fluid low";
CM_ SG_ 975 VCBATT2_a186_washerFluidLowFasci "VCBATT2 ECU: a186 washer fluid low fascia and repeater";
CM_ SG_ 975 VCBATT2_a187_washerFluidLowPasse "VCBATT2 ECU: a187 washer fluid low passenger wiper";
CM_ SG_ 975 VCBATT2_a188_sleepFailed "VCBATT2 ECU: a188 sleep failed";
CM_ SG_ 975 VCBATT2_a192_vehicleLoadShed "VCBATT2 ECU: a192 vehicle load shed";
CM_ SG_ 975 VCBATT2_a208_brakeFluidLow "VCBATT2 ECU: a208 brake fluid low";
CM_ SG_ 975 VCBATT2_a209_brakeFluidSNA "VCBATT2 ECU: a209 brake fluid SNA";
CM_ SG_ 975 VCBATT2_a211_I2CFault "VCBATT2 ECU: a211 I2 c fault";
CM_ SG_ 975 VCBATT2_a227_radFanCompromised "VCBATT2 ECU: a227 rad fan compromised";
CM_ SG_ 975 VCBATT2_a241_radFanMIA "VCBATT2 ECU: a241 rad fan MIA";
CM_ SG_ 975 VCBATT2_a290_leftFogLightFault "VCBATT2 ECU: a290 left fog light fault";
CM_ SG_ 975 VCBATT2_a291_rightFogLightFault "VCBATT2 ECU: a291 right fog light fault";
CM_ SG_ 975 VCBATT2_a292_sideMarkerLightPipe "VCBATT2 ECU: a292 side marker light pipe fault";
CM_ SG_ 975 VCBATT2_a295_rightSideRepeaterLi "VCBATT2 ECU: a295 right side repeater light fault";
CM_ SG_ 975 VCBATT2_a299_homelinkConfigurati "VCBATT2 ECU: a299 homelink configuration failed";
CM_ SG_ 975 VCBATT2_a300_louverActuatorSwapD "VCBATT2 ECU: a300 louver actuator swap detected";
CM_ SG_ 975 VCBATT2_a303_frunkAccessPostActi "VCBATT2 ECU: a303 frunk access post active";
CM_ SG_ 975 VCBATT2_a304_frunkReleaseFailed "VCBATT2 ECU: a304 frunk release failed";
CM_ SG_ 975 VCBATT2_a305_frunkPriOverCurrent "VCBATT2 ECU: a305 frunk pri over current";
CM_ SG_ 975 VCBATT2_a306_frunkPriUnderCurren "VCBATT2 ECU: a306 frunk pri under current";
CM_ SG_ 975 VCBATT2_a309_frunkEmergencyRelea "VCBATT2 ECU: a309 frunk emergency release pressed";
CM_ SG_ 975 VCBATT2_a353_wiperHeaterUndercur "VCBATT2 ECU: a353 wiper heater undercurrent";
CM_ SG_ 975 VCBATT2_a354_windshieldCameraHea "VCBATT2 ECU: a354 windshield camera heater undercurrent";
CM_ SG_ 975 VCBATT2_a361_washerFluidLowMomen "VCBATT2 ECU: a361 washer fluid low momentary";
CM_ SG_ 975 VCBATT2_a364_heaterTypeEstimatio "VCBATT2 ECU: a364 heater type estimation changed";
CM_ SG_ 975 VCBATT2_a389_frunkInhibitingRele "VCBATT2 ECU: a389 frunk inhibiting release at speed";
CM_ SG_ 975 VCBATT2_a391_frunkLatchSwitchFau "VCBATT2 ECU: a391 frunk latch switch fault";
CM_ SG_ 975 VCBATT2_a399_frunkNeverReportedO "VCBATT2 ECU: a399 frunk never reported open";
CM_ SG_ 975 VCBATT2_a423_rtosSleepFailed "VCBATT2 ECU: a423 rtos sleep failed";
CM_ SG_ 975 VCBATT2_a463_frunkSensorService "VCBATT2 ECU: a463 frunk sensor service";
CM_ SG_ 975 VCBATT2_a471_emergencyFrunkButto "VCBATT2 ECU: a471 emergency frunk button press ignored";
CM_ SG_ 975 VCBATT2_a475_rightHeadlampIntern "VCBATT2 ECU: a475 right headlamp internal error";
CM_ SG_ 975 VCBATT2_a485_mcuGamingEFuseFault "VCBATT2 ECU: a485 mcu gaming e fuse fault";
CM_ SG_ 975 VCBATT2_a486_sleepPowerDebug "VCBATT2 ECU: a486 sleep power debug";
CM_ SG_ 975 VCBATT2_a516_hibernationActive "VCBATT2 ECU: a516 hibernation active";
CM_ SG_ 975 VCBATT2_a517_hibernationRecovery "VCBATT2 ECU: a517 hibernation recovery";
CM_ SG_ 975 VCBATT2_a520_rightHeadlampIntern "VCBATT2 ECU: a520 right headlamp internal error V2";
CM_ SG_ 975 VCBATT2_a522_hibernationActiveLo "VCBATT2 ECU: a522 hibernation active log capture";
CM_ SG_ 975 VCBATT2_a524_rightHeadlampAiming "VCBATT2 ECU: a524 right headlamp aiming fault";
CM_ SG_ 975 VCBATT2_a547_postCrashLoadShed "VCBATT2 ECU: a547 post crash load shed";
CM_ SG_ 975 VCBATT2_a548_HVFaultLoadShed "VCBATT2 ECU: a548 HV fault load shed";
CM_ SG_ 975 VCBATT2_a557_rightHeadlampIntern "VCBATT2 ECU: a557 right headlamp internal error V3";
CM_ SG_ 975 VCBATT2_a558_rightHeadlampAiming "VCBATT2 ECU: a558 right headlamp aiming debug";
CM_ SG_ 975 VCBATT2_a567_rightFrontTurnLight "VCBATT2 ECU: a567 right front turn light fault";
CM_ SG_ 975 VCBATT2_a569_rightDaytimeRunning "VCBATT2 ECU: a569 right daytime running light fault";
CM_ SG_ 975 VCBATT2_a575_frontOilPumpEFuseTr "VCBATT2 ECU: a575 front oil pump e fuse trip";
CM_ SG_ 975 VCBATT2_a578_vbattFusedLowCurren "VCBATT2 ECU: a578 vbatt fused low current feed e fuse trip";
CM_ SG_ 975 VCBATT2_a583_frunkSwitchGroupDis "VCBATT2 ECU: a583 frunk switch group disagreement debug";
CM_ SG_ 975 VCBATT2_a584_frunkSwitchGroupDeb "VCBATT2 ECU: a584 frunk switch group debug";
CM_ SG_ 975 VCBATT2_a586_rightLowOrHighBeamL "VCBATT2 ECU: a586 right low or high beam light condition";
CM_ SG_ 975 VCBATT2_a610_frunkOpenFailureMet "VCBATT2 ECU: a610 frunk open failure metric set";
CM_ SG_ 975 VCBATT2_a617_APP_MIA "VCBATT2 ECU: a617 APP MIA";
CM_ SG_ 975 VCBATT2_a619_frunkSwitchReleaseT "VCBATT2 ECU: a619 frunk switch release time DBG";
CM_ SG_ 975 VCBATT2_a624_rightHeadlampIntern "VCBATT2 ECU: a624 right headlamp internal error V4";
CM_ SG_ 975 VCBATT2_a631_rightHeadlampFactor "VCBATT2 ECU: a631 right headlamp factory fault";
CM_ SG_ 975 VCBATT2_a634_indeterminateSwitch "VCBATT2 ECU: a634 indeterminate switch transition detected dbg";
CM_ SG_ 975 VCBATT2_a643_rightHeadlampUartCo "VCBATT2 ECU: a643 right headlamp uart condition";
CM_ SG_ 975 VCBATT2_a644_washPumpHealthCalcu "VCBATT2 ECU: a644 wash pump health calculation dbg0";
CM_ SG_ 975 VCBATT2_a645_washPumpHealthCalcu "VCBATT2 ECU: a645 wash pump health calculation dbg1";
CM_ SG_ 975 VCBATT2_a646_washPumpHealthCalcu "VCBATT2 ECU: a646 wash pump health calculation dbg2";
CM_ SG_ 975 VCBATT2_a649_persistAccPortPower "VCBATT2 ECU: a649 persist acc port power req overridden";
CM_ SG_ 975 VCBATT2_a650_powerConsumptionInf "VCBATT2 ECU: a650 power consumption info";
CM_ SG_ 975 VCBATT2_a662_mculessRightHeadlam "VCBATT2 ECU: a662 mculess right headlamp current alert dbg";
CM_ SG_ 975 VCBATT2_a664_rightHeadlampUartWa "VCBATT2 ECU: a664 right headlamp uart water mark warning";
CM_ SG_ 975 VCBATT2_a666_rightHeadlampRetryI "VCBATT2 ECU: a666 right headlamp retry info";
CM_ SG_ 975 VCBATT2_a668_rightHeadlampRegion "VCBATT2 ECU: a668 right headlamp region or side mismatch";
CM_ SG_ 975 VCBATT2_a698_rightHeadlampNotAim "VCBATT2 ECU: a698 right headlamp not aimed";
CM_ SG_ 975 VCBATT2_a702_dynamicHeadlightLev "VCBATT2 ECU: a702 dynamic headlight leveling unavailable";
CM_ BO_ 1399 "VCBATT2 ECU message: logging10 hz";
CM_ SG_ 1399 VCBATT2_vehiclePowerStateDBG "VCBATT2 ECU: vehicle power state DBG";
CM_ SG_ 1399 VCBATT2_nmWakeUpReasonDBG "VCBATT2 ECU: nm wake up reason DBG";
CM_ SG_ 1399 VCBATT2_nmKeepAwakeReasonDBG "VCBATT2 ECU: nm keep awake reason DBG; raw 0 = signal not available (SNA)";
CM_ SG_ 1399 VCBATT2_LIN_bus_0_busErrorCount "LIN bus 0 (Thermal) HW bus error count";
CM_ SG_ 1399 VCBATT2_LIN_bus_1_busErrorCount "LIN bus 1 (Homelink/Headlamp) HW bus error count";
CM_ SG_ 1399 VCBATT2_hibernationStateDBG "VCBATT2 ECU: hibernation state DBG";
CM_ BO_ 1567 "VCBATT2 ECU message: uds response";
CM_ SG_ 1567 VCBATT2_udsResponseData "VCBATT2 ECU: uds response data";
CM_ BO_ 945 "VCBATT ECU message: LV health";
CM_ SG_ 945 VCBATT_LVHealthChecksum "VCBATT ECU: LV health checksum";
CM_ SG_ 945 VCBATT_LVHealthCounter "VCBATT ECU: LV health counter";
CM_ SG_ 945 VCBATT_LVHealthStatus "Health status of the LV system";
CM_ SG_ 945 VCBATT_LVStatusForDrive "Status for drive based on health status of the LV system";
CM_ SG_ 945 VCBATT_LVPowerSecondsToSafeHarbo "Reports the amount of time (in seconds) the Low Voltage (LV) power system indicates the vehicle has to achieve safe harbor.";
CM_ SG_ 945 VCBATT_autonomyBehavior "Current autonomy mode and expected vehicle behaviors.";
CM_ SG_ 945 VCBATT_hardwareProtectionsArmed "Hardware protections armed";
CM_ SG_ 945 VCBATT_12vStatusForDrive "VCBATT ECU: 12v status for drive";
CM_ BO_ 1090 "VCBATT ECU message: pcs interface";
CM_ SG_ 1090 VCBATT_pcsInterfaceMuxIndex "VCBATT ECU: pcs interface mux index";
CM_ SG_ 1090 VCBATT_pcsInterfaceCounter "VCBATT ECU: pcs interface counter";
CM_ SG_ 1090 VCBATT_pcsInterfaceChecksum "VCBATT ECU: pcs interface checksum";
CM_ SG_ 1090 VCBATT_pcsLVVoltageTarget "VCBATT ECU: pcs LV voltage target";
CM_ SG_ 1090 VCBATT_pcsLVMinVoltageLimit "VCBATT ECU: pcs LV min voltage limit";
CM_ SG_ 1090 VCBATT_pcsLVMaxVoltageLimit "VCBATT ECU: pcs LV max voltage limit";
CM_ SG_ 1090 VCBATT_goodForPCSPowerCycle "VCBATT ECU: good for PCS power cycle";
CM_ SG_ 1090 VCBATT_LVBatteryCannotSupportVeh "VCBATT ECU: LV battery cannot support vehicle";
CM_ SG_ 1090 VCBATT_pcsResistanceFiltered "VCBATT ECU: pcs resistance filtered; raw 65535 = signal not available (SNA)";
CM_ SG_ 1090 VCBATT_pcsLVMaxDchrgCurrentLimit "VCBATT ECU: pcs LV max dchrg current limit";
CM_ SG_ 1090 VCBATT_defaultPcsLVVoltageTarget "VCBATT ECU: default pcs LV voltage target";
CM_ SG_ 1090 VCBATT_lvHwProtSelfTestActive "Reports whether Low Voltage (LV) Hardware (HW) protection self-tests are running or about to run due to a retry.";
CM_ SG_ 1090 VCBATT_lvBatteryDischargeRequest "VCBATT ECU: lv battery discharge request";
CM_ BO_ 1587 "VCBATT ECU message: uds response";
CM_ SG_ 1587 VCBATT_udsResponseData "VCBATT ECU: uds response data";
CM_ BO_ 1994 "VCCC ECU message: info";
CM_ SG_ 1994 VCCC_infoIndex "VCCC ECU: info index";
CM_ SG_ 1994 VCCC_infoBuildType "VCCC ECU: info build type";
CM_ SG_ 1994 VCCC_infoBuildConfigId "VCCC ECU: info build config id";
CM_ SG_ 1994 VCCC_infoHardwareId "VCCC ECU: info hardware id";
CM_ SG_ 1994 VCCC_infoComponentId "VCCC ECU: info component id";
CM_ SG_ 1994 VCCC_infoPcbaId "VCCC ECU: info pcba id";
CM_ SG_ 1994 VCCC_infoAssemblyId "VCCC ECU: info assembly id; raw 255 = signal not available (SNA)";
CM_ SG_ 1994 VCCC_infoUsageId "VCCC ECU: info usage id";
CM_ SG_ 1994 VCCC_infoSubUsageId "VCCC ECU: info sub usage id";
CM_ SG_ 1994 VCCC_infoAppCrc "VCCC ECU: info app crc";
CM_ SG_ 1994 VCCC_infoAppGitHash "VCCC ECU: info app git hash";
CM_ SG_ 1994 VCCC_infoBootGitHash "VCCC ECU: info boot git hash";
CM_ SG_ 1994 VCCC_infoBootUdsProtoVersion "VCCC ECU: info boot uds proto version";
CM_ SG_ 1994 VCCC_infoBootCrc "VCCC ECU: info boot crc";
BA_DEF_ BO_ "GenMsgCycleTime" INT 0 3600000;
BA_DEF_ BO_ "GenMsgSendType" ENUM "Cyclic","NotUsed","NotUsed","NotUsed","NotUsed","NotUsed","NotUsed","IfActive","NoMsgSendType","NotUsed";
BA_DEF_ BO_ "VFrameFormat" ENUM "StandardCAN","ExtendedCAN","reserved","J1939PG","reserved","reserved","reserved","reserved","reserved","reserved","reserved","reserved","reserved","reserved","StandardCAN_FD","ExtendedCAN_FD";
BA_DEF_ BO_ "CANFD_BRS" ENUM "0","1";
BA_DEF_ SG_ "GenSigSNA" STRING;
BA_DEF_ SG_ "SystemSignalLongSymbol" STRING;
BA_DEF_ SG_ "Confidence" ENUM "validated","plausible","layout-only","contradicted";
BA_DEF_DEF_ "GenMsgCycleTime" 0;
BA_DEF_DEF_ "GenMsgSendType" "NoMsgSendType";
BA_DEF_DEF_ "VFrameFormat" "StandardCAN";
BA_DEF_DEF_ "CANFD_BRS" "1";
BA_DEF_DEF_ "GenSigSNA" "";
BA_DEF_DEF_ "SystemSignalLongSymbol" "";
BA_DEF_DEF_ "Confidence" "layout-only";
BA_ "GenMsgCycleTime" BO_ 974 100;
BA_ "GenMsgSendType" BO_ 974 0;
BA_ "GenMsgCycleTime" BO_ 1030 200;
BA_ "GenMsgSendType" BO_ 1030 0;
BA_ "GenMsgCycleTime" BO_ 975 100;
BA_ "GenMsgSendType" BO_ 975 0;
BA_ "GenMsgCycleTime" BO_ 1399 100;
BA_ "GenMsgSendType" BO_ 1399 0;
BA_ "GenMsgCycleTime" BO_ 945 100;
BA_ "GenMsgSendType" BO_ 945 0;
BA_ "GenMsgCycleTime" BO_ 1090 50;
BA_ "GenMsgSendType" BO_ 1090 0;
BA_ "GenMsgCycleTime" BO_ 1994 1000;
BA_ "GenMsgSendType" BO_ 1994 0;
BA_ "Confidence" SG_ 974 VCBATT1_matrixIndex 1;
BA_ "SystemSignalLongSymbol" SG_ 974 VCBATT1_a134_hvContactorsEFuseTr "VCBATT1_a134_hvContactorsEFuseTrip";
BA_ "SystemSignalLongSymbol" SG_ 974 VCBATT1_a180_DCDCNotSupportingLV "VCBATT1_a180_DCDCNotSupportingLVBus";
BA_ "SystemSignalLongSymbol" SG_ 974 VCBATT1_a191_exitDriveLowLVBusVo "VCBATT1_a191_exitDriveLowLVBusVoltage";
BA_ "SystemSignalLongSymbol" SG_ 974 VCBATT1_a204_undervoltageLoadshe "VCBATT1_a204_undervoltageLoadshedTriggered";
BA_ "SystemSignalLongSymbol" SG_ 974 VCBATT1_a205_overvoltageProtecti "VCBATT1_a205_overvoltageProtectionTriggered";
BA_ "SystemSignalLongSymbol" SG_ 974 VCBATT1_a215_selfTestOrchestrato "VCBATT1_a215_selfTestOrchestratorDebug";
BA_ "SystemSignalLongSymbol" SG_ 974 VCBATT1_a217_LVProtectionSelfTes "VCBATT1_a217_LVProtectionSelfTestInvalid";
BA_ "SystemSignalLongSymbol" SG_ 974 VCBATT1_a223_bridgeOvervoltageSe "VCBATT1_a223_bridgeOvervoltageSelfTestFailure";
BA_ "SystemSignalLongSymbol" SG_ 974 VCBATT1_a224_overcurrentLoadshed "VCBATT1_a224_overcurrentLoadshedTriggered";
BA_ "SystemSignalLongSymbol" SG_ 974 VCBATT1_a225_overcurrentSelfTest "VCBATT1_a225_overcurrentSelfTestFailure";
BA_ "SystemSignalLongSymbol" SG_ 974 VCBATT1_a226_overcurrentSelfTest "VCBATT1_a226_overcurrentSelfTestChannelFastDBG";
BA_ "SystemSignalLongSymbol" SG_ 974 VCBATT1_a227_overcurrentSelfTest "VCBATT1_a227_overcurrentSelfTestChannelMediumDBG";
BA_ "SystemSignalLongSymbol" SG_ 974 VCBATT1_a228_overcurrentSelfTest "VCBATT1_a228_overcurrentSelfTestChannelSlowDBG";
BA_ "SystemSignalLongSymbol" SG_ 974 VCBATT1_a230_ingoingOvercurrentS "VCBATT1_a230_ingoingOvercurrentSelfTestFailure";
BA_ "SystemSignalLongSymbol" SG_ 974 VCBATT1_a231_autopilot1EFuseTrip "VCBATT1_a231_autopilot1EFuseTripDuringOTA";
BA_ "SystemSignalLongSymbol" SG_ 974 VCBATT1_a235_dualPowerLoadsSelfT "VCBATT1_a235_dualPowerLoadsSelfTestFailure";
BA_ "SystemSignalLongSymbol" SG_ 974 VCBATT1_a236_hvcDualPowerSelfTes "VCBATT1_a236_hvcDualPowerSelfTestDebug";
BA_ "SystemSignalLongSymbol" SG_ 974 VCBATT1_a244_brakeValveECUEFuseT "VCBATT1_a244_brakeValveECUEFuseTrip";
BA_ "SystemSignalLongSymbol" SG_ 974 VCBATT1_a253_maxChrgeSssionTmeou "VCBATT1_a253_maxChrgeSssionTmeout";
BA_ "SystemSignalLongSymbol" SG_ 974 VCBATT1_a258_resistanceEstimatio "VCBATT1_a258_resistanceEstimationRun";
BA_ "SystemSignalLongSymbol" SG_ 974 VCBATT1_a259_LVVoltageDropOnHigh "VCBATT1_a259_LVVoltageDropOnHighLoadCurrent";
BA_ "SystemSignalLongSymbol" SG_ 974 VCBATT1_a275_TLVBMS_BmbCommunica "VCBATT1_a275_TLVBMS_BmbCommunication";
BA_ "SystemSignalLongSymbol" SG_ 974 VCBATT1_a276_TLVBMS_BmbDataInteg "VCBATT1_a276_TLVBMS_BmbDataIntegrityLoss";
BA_ "SystemSignalLongSymbol" SG_ 974 VCBATT1_a277_TLVBMS_BmbStatusReg "VCBATT1_a277_TLVBMS_BmbStatusRegError";
BA_ "SystemSignalLongSymbol" SG_ 974 VCBATT1_a278_TLVBMS_BmbHwOverCur "VCBATT1_a278_TLVBMS_BmbHwOverCurrentFault";
BA_ "SystemSignalLongSymbol" SG_ 974 VCBATT1_a297_TLVBMS_BmbHwOverTem "VCBATT1_a297_TLVBMS_BmbHwOverTemperatureFault";
BA_ "SystemSignalLongSymbol" SG_ 974 VCBATT1_a362_TLVBMS_AllSocCorrec "VCBATT1_a362_TLVBMS_AllSocCorrectionTimeout";
BA_ "SystemSignalLongSymbol" SG_ 974 VCBATT1_a363_TLVBMS_BleedBasedWe "VCBATT1_a363_TLVBMS_BleedBasedWeakShort";
BA_ "SystemSignalLongSymbol" SG_ 974 VCBATT1_a370_noLVSupportSocTooLo "VCBATT1_a370_noLVSupportSocTooLow";
BA_ "SystemSignalLongSymbol" SG_ 974 VCBATT1_a371_failureToPrechargeR "VCBATT1_a371_failureToPrechargeRisk";
BA_ "SystemSignalLongSymbol" SG_ 974 VCBATT1_a372_TLVBMS_BmbHwOverVol "VCBATT1_a372_TLVBMS_BmbHwOverVoltageFault";
BA_ "SystemSignalLongSymbol" SG_ 974 VCBATT1_a376_controllerWakeupDeb "VCBATT1_a376_controllerWakeupDebug";
BA_ "SystemSignalLongSymbol" SG_ 974 VCBATT1_a379_shortedCellTestRunD "VCBATT1_a379_shortedCellTestRunDebug";
BA_ "SystemSignalLongSymbol" SG_ 974 VCBATT1_a392_TLVBMS_BmbHwUnderVo "VCBATT1_a392_TLVBMS_BmbHwUnderVoltageFault";
BA_ "SystemSignalLongSymbol" SG_ 974 VCBATT1_a401_deadLVMinimalAhDisc "VCBATT1_a401_deadLVMinimalAhDischarged";
BA_ "SystemSignalLongSymbol" SG_ 974 VCBATT1_a402_LVBatteryCannotSupp "VCBATT1_a402_LVBatteryCannotSupportVehicle";
BA_ "SystemSignalLongSymbol" SG_ 974 VCBATT1_a403_chargeExitHardCurre "VCBATT1_a403_chargeExitHardCurrentLimit";
BA_ "SystemSignalLongSymbol" SG_ 974 VCBATT1_a404_resistanceEstimatio "VCBATT1_a404_resistanceEstimationHardFailure";
BA_ "SystemSignalLongSymbol" SG_ 974 VCBATT1_a407_dcrMilliOhmsAboveTh "VCBATT1_a407_dcrMilliOhmsAboveThreshold";
BA_ "SystemSignalLongSymbol" SG_ 974 VCBATT1_a408_standbyChargeProfil "VCBATT1_a408_standbyChargeProfileHardExit";
BA_ "SystemSignalLongSymbol" SG_ 974 VCBATT1_a410_LVBatteryDataCollec "VCBATT1_a410_LVBatteryDataCollection1";
BA_ "SystemSignalLongSymbol" SG_ 974 VCBATT1_a411_LVBatteryDataCollec "VCBATT1_a411_LVBatteryDataCollection2";
BA_ "SystemSignalLongSymbol" SG_ 974 VCBATT1_a413_TLVBMS_BmbVrefWarni "VCBATT1_a413_TLVBMS_BmbVrefWarning";
BA_ "SystemSignalLongSymbol" SG_ 974 VCBATT1_a414_undervoltageSelfTes "VCBATT1_a414_undervoltageSelfTestFailure";
BA_ "SystemSignalLongSymbol" SG_ 974 VCBATT1_a415_undervoltageSelfTes "VCBATT1_a415_undervoltageSelfTestStuckOff";
BA_ "SystemSignalLongSymbol" SG_ 974 VCBATT1_a416_TLVBMS_BrickOverDis "VCBATT1_a416_TLVBMS_BrickOverDischarged";
BA_ "SystemSignalLongSymbol" SG_ 974 VCBATT1_a417_TLVBMS_BrickOverVol "VCBATT1_a417_TLVBMS_BrickOverVoltageFault";
BA_ "SystemSignalLongSymbol" SG_ 974 VCBATT1_a418_TLVBMS_BrickOverVol "VCBATT1_a418_TLVBMS_BrickOverVoltageWarning";
BA_ "SystemSignalLongSymbol" SG_ 974 VCBATT1_a421_LVBatteryHealthTest "VCBATT1_a421_LVBatteryHealthTestInterrupted";
BA_ "SystemSignalLongSymbol" SG_ 974 VCBATT1_a423_TLVBMS_BrickUnderVo "VCBATT1_a423_TLVBMS_BrickUnderVoltageFault";
BA_ "SystemSignalLongSymbol" SG_ 974 VCBATT1_a424_TLVBMS_BrickUnderVo "VCBATT1_a424_TLVBMS_BrickUnderVoltageOcv";
BA_ "SystemSignalLongSymbol" SG_ 974 VCBATT1_a425_TLVBMS_BusVoltageTo "VCBATT1_a425_TLVBMS_BusVoltageTooHigh";
BA_ "SystemSignalLongSymbol" SG_ 974 VCBATT1_a426_TLVBMS_BusVoltageTo "VCBATT1_a426_TLVBMS_BusVoltageTooLow";
BA_ "SystemSignalLongSymbol" SG_ 974 VCBATT1_a429_TLVBMS_CapacityTest "VCBATT1_a429_TLVBMS_CapacityTestResults";
BA_ "SystemSignalLongSymbol" SG_ 974 VCBATT1_a430_TLVBMS_ChargeCurren "VCBATT1_a430_TLVBMS_ChargeCurrentLimitExceeded";
BA_ "SystemSignalLongSymbol" SG_ 974 VCBATT1_a431_TLVBMS_ChargeOverCu "VCBATT1_a431_TLVBMS_ChargeOverCurrent";
BA_ "SystemSignalLongSymbol" SG_ 974 VCBATT1_a432_TLVBMS_ChargeRegula "VCBATT1_a432_TLVBMS_ChargeRegulationFault";
BA_ "SystemSignalLongSymbol" SG_ 974 VCBATT1_a433_TLVBMS_ConfigFromBm "VCBATT1_a433_TLVBMS_ConfigFromBmbModIdFailed";
BA_ "SystemSignalLongSymbol" SG_ 974 VCBATT1_a434_TLVBMS_ConfigInitFa "VCBATT1_a434_TLVBMS_ConfigInitFailed";
BA_ "SystemSignalLongSymbol" SG_ 974 VCBATT1_a435_TLVBMS_DchgCurrentL "VCBATT1_a435_TLVBMS_DchgCurrentLimitExceeded";
BA_ "SystemSignalLongSymbol" SG_ 974 VCBATT1_a436_TLVBMS_DischargeOve "VCBATT1_a436_TLVBMS_DischargeOverCurrent";
BA_ "SystemSignalLongSymbol" SG_ 974 VCBATT1_a437_TLVBMS_NvmRegistrat "VCBATT1_a437_TLVBMS_NvmRegistrationError";
BA_ "SystemSignalLongSymbol" SG_ 974 VCBATT1_a438_TLVBMS_PackOverTemp "VCBATT1_a438_TLVBMS_PackOverTemperatureFault";
BA_ "SystemSignalLongSymbol" SG_ 974 VCBATT1_a439_TLVBMS_PackOverTemp "VCBATT1_a439_TLVBMS_PackOverTemperatureWarning";
BA_ "SystemSignalLongSymbol" SG_ 974 VCBATT1_a440_TLVBMS_PackSNInvali "VCBATT1_a440_TLVBMS_PackSNInvalidForNvm";
BA_ "SystemSignalLongSymbol" SG_ 974 VCBATT1_a441_TLVBMS_ResetNeededF "VCBATT1_a441_TLVBMS_ResetNeededForNvmPackSwap";
BA_ "SystemSignalLongSymbol" SG_ 974 VCBATT1_a443_TLVBMS_BmbDieOverTe "VCBATT1_a443_TLVBMS_BmbDieOverTemperature";
BA_ "SystemSignalLongSymbol" SG_ 974 VCBATT1_a446_LVBatteryUnrecovera "VCBATT1_a446_LVBatteryUnrecoverableByAnyDevice";
BA_ "SystemSignalLongSymbol" SG_ 974 VCBATT1_a461_TLVBMS_SocHighAhErr "VCBATT1_a461_TLVBMS_SocHighAhError";
BA_ "SystemSignalLongSymbol" SG_ 974 VCBATT1_a477_LVBatteryUnrecovera "VCBATT1_a477_LVBatteryUnrecoverableByVehicle";
BA_ "SystemSignalLongSymbol" SG_ 974 VCBATT1_a479_LVBMS_ECPA_NotClose "VCBATT1_a479_LVBMS_ECPA_NotClosed";
BA_ "SystemSignalLongSymbol" SG_ 974 VCBATT1_a483_vnf1048SelfTestFail "VCBATT1_a483_vnf1048SelfTestFailure";
BA_ "SystemSignalLongSymbol" SG_ 974 VCBATT1_a484_undervoltageSelfTes "VCBATT1_a484_undervoltageSelfTestStuckOn";
BA_ "SystemSignalLongSymbol" SG_ 974 VCBATT1_a485_uvSelfTestLoadUnatt "VCBATT1_a485_uvSelfTestLoadUnattemptedOnDbg";
BA_ "SystemSignalLongSymbol" SG_ 974 VCBATT1_a486_undervoltageSelfTes "VCBATT1_a486_undervoltageSelfTestBridgeSyncFailure";
BA_ "SystemSignalLongSymbol" SG_ 974 VCBATT1_a489_vnf1248SelfTestDebu "VCBATT1_a489_vnf1248SelfTestDebug";
BA_ "SystemSignalLongSymbol" SG_ 974 VCBATT1_a490_vnf1248SelfTestFail "VCBATT1_a490_vnf1248SelfTestFailure";
BA_ "SystemSignalLongSymbol" SG_ 974 VCBATT1_a491_vnf1248Configuratio "VCBATT1_a491_vnf1248ConfigurationMismatch";
BA_ "SystemSignalLongSymbol" SG_ 974 VCBATT1_a493_TLVBMS_SocImbalance "VCBATT1_a493_TLVBMS_SocImbalanceWarning";
BA_ "SystemSignalLongSymbol" SG_ 974 VCBATT1_a494_LVBatteryTempBlocki "VCBATT1_a494_LVBatteryTempBlockingOTA";
BA_ "SystemSignalLongSymbol" SG_ 974 VCBATT1_a495_LVBatteryRecoveryBl "VCBATT1_a495_LVBatteryRecoveryBlocked";
BA_ "SystemSignalLongSymbol" SG_ 974 VCBATT1_a496_LVBatteryExitDriveW "VCBATT1_a496_LVBatteryExitDriveWarning";
BA_ "SystemSignalLongSymbol" SG_ 974 VCBATT1_a497_LVBatteryWarnDiscon "VCBATT1_a497_LVBatteryWarnDisconnect";
BA_ "SystemSignalLongSymbol" SG_ 974 VCBATT1_a498_TLVBMS_ImpedanceTes "VCBATT1_a498_TLVBMS_ImpedanceTestResults";
BA_ "SystemSignalLongSymbol" SG_ 974 VCBATT1_a500_eFuseASICStateMisma "VCBATT1_a500_eFuseASICStateMismatch";
BA_ "SystemSignalLongSymbol" SG_ 974 VCBATT1_a501_vnf1048Configuratio "VCBATT1_a501_vnf1048ConfigurationMismatch";
BA_ "SystemSignalLongSymbol" SG_ 974 VCBATT1_a502_TLVBMS_WeakShortImp "VCBATT1_a502_TLVBMS_WeakShortImpedance";
BA_ "SystemSignalLongSymbol" SG_ 974 VCBATT1_a503_TLVBMS_BrickExtende "VCBATT1_a503_TLVBMS_BrickExtendedOvFault";
BA_ "SystemSignalLongSymbol" SG_ 974 VCBATT1_a508_TLVBMS_ImpedanceGro "VCBATT1_a508_TLVBMS_ImpedanceGrowth";
BA_ "SystemSignalLongSymbol" SG_ 974 VCBATT1_a509_eFuseASICManagerSta "VCBATT1_a509_eFuseASICManagerStateMismatch";
BA_ "SystemSignalLongSymbol" SG_ 974 VCBATT1_a510_LVBatteryRecoveryTi "VCBATT1_a510_LVBatteryRecoveryTimeout";
BA_ "SystemSignalLongSymbol" SG_ 974 VCBATT1_a512_LVBMSFault_MOS_Open "VCBATT1_a512_LVBMSFault_MOS_Open_hardwareOC";
BA_ "SystemSignalLongSymbol" SG_ 974 VCBATT1_a513_LVBMSFault_MOS_Open "VCBATT1_a513_LVBMSFault_MOS_Open_chgOC";
BA_ "SystemSignalLongSymbol" SG_ 974 VCBATT1_a514_LVBMSFault_MOS_Open "VCBATT1_a514_LVBMSFault_MOS_Open_cellUV";
BA_ "SystemSignalLongSymbol" SG_ 974 VCBATT1_a515_LVBMSFault_MOS_Open "VCBATT1_a515_LVBMSFault_MOS_Open_cellOV";
BA_ "SystemSignalLongSymbol" SG_ 974 VCBATT1_a518_LVBMSFault_MOS_Open "VCBATT1_a518_LVBMSFault_MOS_Open_packOV";
BA_ "SystemSignalLongSymbol" SG_ 974 VCBATT1_a523_eFuseThresholdsInco "VCBATT1_a523_eFuseThresholdsIncorrect";
BA_ "SystemSignalLongSymbol" SG_ 974 VCBATT1_a525_LVBatterySWMisconfi "VCBATT1_a525_LVBatterySWMisconfiguration";
BA_ "SystemSignalLongSymbol" SG_ 974 VCBATT1_a527_LVBatteryCellImbala "VCBATT1_a527_LVBatteryCellImbalance";
BA_ "SystemSignalLongSymbol" SG_ 974 VCBATT1_a528_LVBatteryCommsDiscn "VCBATT1_a528_LVBatteryCommsDiscnctd";
BA_ "SystemSignalLongSymbol" SG_ 974 VCBATT1_a529_discnctdBatteryStat "VCBATT1_a529_discnctdBatteryStateUnknown";
BA_ "SystemSignalLongSymbol" SG_ 974 VCBATT1_a533_TLVBMS_MosfetOverTe "VCBATT1_a533_TLVBMS_MosfetOverTemperatureFault";
BA_ "SystemSignalLongSymbol" SG_ 974 VCBATT1_a541_LVBatteryChargeOCLe "VCBATT1_a541_LVBatteryChargeOCLevel1";
BA_ "SystemSignalLongSymbol" SG_ 974 VCBATT1_a544_LVBatteryCommsBusTu "VCBATT1_a544_LVBatteryCommsBusTurnedOff";
BA_ "SystemSignalLongSymbol" SG_ 974 VCBATT1_a545_LVBatteryTypeUnknow "VCBATT1_a545_LVBatteryTypeUnknown";
BA_ "SystemSignalLongSymbol" SG_ 974 VCBATT1_a555_LVBatteryCellRebala "VCBATT1_a555_LVBatteryCellRebalancing";
BA_ "SystemSignalLongSymbol" SG_ 974 VCBATT1_a556_falseTriggerOfDiscn "VCBATT1_a556_falseTriggerOfDiscnctdBatteryTest";
BA_ "SystemSignalLongSymbol" SG_ 974 VCBATT1_a561_LVBMSEFuseOvertempe "VCBATT1_a561_LVBMSEFuseOvertemperature";
BA_ "SystemSignalLongSymbol" SG_ 974 VCBATT1_a562_LVBMSModuleOvertemp "VCBATT1_a562_LVBMSModuleOvertemperature";
BA_ "SystemSignalLongSymbol" SG_ 974 VCBATT1_a575_vbatFusedLoadShedEF "VCBATT1_a575_vbatFusedLoadShedEFuseTrip";
BA_ "SystemSignalLongSymbol" SG_ 974 VCBATT1_a580_rightHeadlightEFuse "VCBATT1_a580_rightHeadlightEFuseTrip";
BA_ "SystemSignalLongSymbol" SG_ 974 VCBATT1_a581_harnessResistanceIn "VCBATT1_a581_harnessResistanceInfo";
BA_ "SystemSignalLongSymbol" SG_ 974 VCBATT1_a582_goodForPCSPowerCycl "VCBATT1_a582_goodForPCSPowerCycle";
BA_ "SystemSignalLongSymbol" SG_ 974 VCBATT1_a585_lvBatteryHealthTest "VCBATT1_a585_lvBatteryHealthTestRequired";
BA_ "SystemSignalLongSymbol" SG_ 974 VCBATT1_a587_externalLVPowerSupp "VCBATT1_a587_externalLVPowerSupply";
BA_ "SystemSignalLongSymbol" SG_ 974 VCBATT1_a588_vcleftPwrRationalit "VCBATT1_a588_vcleftPwrRationalityCurve";
BA_ "SystemSignalLongSymbol" SG_ 974 VCBATT1_a589_vcleftFastBlowDetec "VCBATT1_a589_vcleftFastBlowDetection";
BA_ "SystemSignalLongSymbol" SG_ 974 VCBATT1_a592_vcleftCurvePowerCut "VCBATT1_a592_vcleftCurvePowerCutoff";
BA_ "SystemSignalLongSymbol" SG_ 974 VCBATT1_a593_vcleftFastBlowPower "VCBATT1_a593_vcleftFastBlowPowerCutoff";
BA_ "SystemSignalLongSymbol" SG_ 974 VCBATT1_a595_voltageSensorMismat "VCBATT1_a595_voltageSensorMismatch";
BA_ "SystemSignalLongSymbol" SG_ 974 VCBATT1_a597_LVBMBeFuseSelfTestN "VCBATT1_a597_LVBMBeFuseSelfTestNotReady";
BA_ "SystemSignalLongSymbol" SG_ 974 VCBATT1_a598_LVBMBeFuseSelfTestF "VCBATT1_a598_LVBMBeFuseSelfTestFailed";
BA_ "SystemSignalLongSymbol" SG_ 974 VCBATT1_a599_LVBatteryTypeUnsupp "VCBATT1_a599_LVBatteryTypeUnsupported";
BA_ "SystemSignalLongSymbol" SG_ 974 VCBATT1_a600_currentSensorMismat "VCBATT1_a600_currentSensorMismatch";
BA_ "SystemSignalLongSymbol" SG_ 974 VCBATT1_a601_LVBatteryHeaterNotP "VCBATT1_a601_LVBatteryHeaterNotPresent";
BA_ "SystemSignalLongSymbol" SG_ 974 VCBATT1_a608_TLVBMS_BleedFetFail "VCBATT1_a608_TLVBMS_BleedFetFailure";
BA_ "SystemSignalLongSymbol" SG_ 974 VCBATT1_a615_TLVBMS_BatteryHeate "VCBATT1_a615_TLVBMS_BatteryHeaterFault";
BA_ "SystemSignalLongSymbol" SG_ 974 VCBATT1_a628_TLVBMS_BmbThermisto "VCBATT1_a628_TLVBMS_BmbThermistorFault";
BA_ "SystemSignalLongSymbol" SG_ 974 VCBATT1_a629_TLVBMS_PackTemperat "VCBATT1_a629_TLVBMS_PackTemperatureIrrational";
BA_ "SystemSignalLongSymbol" SG_ 974 VCBATT1_a670_TLVBMS_EfuseStateIr "VCBATT1_a670_TLVBMS_EfuseStateIrrational";
BA_ "Confidence" SG_ 1030 VCBATT1_eFuseDebugStatusIndex 1;
BA_ "Confidence" SG_ 1030 VCBATT1_leftControllerEFuseState 0;
BA_ "Confidence" SG_ 1030 VCBATT1_leftControllerEFuseCurre 0;
BA_ "SystemSignalLongSymbol" SG_ 1030 VCBATT1_leftControllerEFuseCurre "VCBATT1_leftControllerEFuseCurrent";
BA_ "Confidence" SG_ 1030 VCBATT1_leftControllerEFuseOutpu 0;
BA_ "SystemSignalLongSymbol" SG_ 1030 VCBATT1_leftControllerEFuseOutpu "VCBATT1_leftControllerEFuseOutput";
BA_ "Confidence" SG_ 1030 VCBATT1_leftControllerEFuse_0002 0;
BA_ "SystemSignalLongSymbol" SG_ 1030 VCBATT1_leftControllerEFuse_0002 "VCBATT1_leftControllerEFuseOutputDesired";
BA_ "Confidence" SG_ 1030 VCBATT1_leftControllerEFuseBypas 0;
BA_ "SystemSignalLongSymbol" SG_ 1030 VCBATT1_leftControllerEFuseBypas "VCBATT1_leftControllerEFuseBypass";
BA_ "Confidence" SG_ 1030 VCBATT1_leftControllerEFuse_0001 0;
BA_ "SystemSignalLongSymbol" SG_ 1030 VCBATT1_leftControllerEFuse_0001 "VCBATT1_leftControllerEFuseBypassDesired";
BA_ "Confidence" SG_ 1030 VCBATT1_leftControllerEFuseVolta 0;
BA_ "SystemSignalLongSymbol" SG_ 1030 VCBATT1_leftControllerEFuseVolta "VCBATT1_leftControllerEFuseVoltage";
BA_ "Confidence" SG_ 1030 VCBATT1_leftControllerEFuseTempe 0;
BA_ "SystemSignalLongSymbol" SG_ 1030 VCBATT1_leftControllerEFuseTempe "VCBATT1_leftControllerEFuseTemperature";
BA_ "Confidence" SG_ 1030 VCBATT1_leftControllerEFuseManag 0;
BA_ "SystemSignalLongSymbol" SG_ 1030 VCBATT1_leftControllerEFuseManag "VCBATT1_leftControllerEFuseManagerState";
BA_ "Confidence" SG_ 1030 VCBATT1_leftControllerEFuseHardS 0;
BA_ "SystemSignalLongSymbol" SG_ 1030 VCBATT1_leftControllerEFuseHardS "VCBATT1_leftControllerEFuseHardShortThreshold";
BA_ "Confidence" SG_ 1030 VCBATT1_leftControllerEFuseOCThr 0;
BA_ "SystemSignalLongSymbol" SG_ 1030 VCBATT1_leftControllerEFuseOCThr "VCBATT1_leftControllerEFuseOCThreshold";
BA_ "Confidence" SG_ 1030 VCBATT1_leftControllerEFuseType 0;
BA_ "Confidence" SG_ 1030 VCBATT1_EPAS1EFuseState 0;
BA_ "Confidence" SG_ 1030 VCBATT1_EPAS1EFuseCurrent 0;
BA_ "Confidence" SG_ 1030 VCBATT1_EPAS1EFuseOutput 0;
BA_ "Confidence" SG_ 1030 VCBATT1_EPAS1EFuseOutputDesired 0;
BA_ "Confidence" SG_ 1030 VCBATT1_EPAS1EFuseBypass 0;
BA_ "Confidence" SG_ 1030 VCBATT1_EPAS1EFuseBypassDesired 0;
BA_ "Confidence" SG_ 1030 VCBATT1_EPAS1EFuseVoltage 0;
BA_ "Confidence" SG_ 1030 VCBATT1_EPAS1EFuseTemperature 0;
BA_ "Confidence" SG_ 1030 VCBATT1_EPAS1EFuseManagerState 0;
BA_ "Confidence" SG_ 1030 VCBATT1_EPAS1EFuseHardShortThres 0;
BA_ "SystemSignalLongSymbol" SG_ 1030 VCBATT1_EPAS1EFuseHardShortThres "VCBATT1_EPAS1EFuseHardShortThreshold";
BA_ "Confidence" SG_ 1030 VCBATT1_EPAS1EFuseOCThreshold 0;
BA_ "Confidence" SG_ 1030 VCBATT1_EPAS1EFuseType 0;
BA_ "Confidence" SG_ 1030 VCBATT1_autopilot1EFuseState 0;
BA_ "Confidence" SG_ 1030 VCBATT1_autopilot1EFuseCurrent 0;
BA_ "Confidence" SG_ 1030 VCBATT1_autopilot1EFuseOutput 0;
BA_ "Confidence" SG_ 1030 VCBATT1_autopilot1EFuseOutputDes 0;
BA_ "SystemSignalLongSymbol" SG_ 1030 VCBATT1_autopilot1EFuseOutputDes "VCBATT1_autopilot1EFuseOutputDesired";
BA_ "Confidence" SG_ 1030 VCBATT1_autopilot1EFuseBypass 0;
BA_ "Confidence" SG_ 1030 VCBATT1_autopilot1EFuseBypassDes 0;
BA_ "SystemSignalLongSymbol" SG_ 1030 VCBATT1_autopilot1EFuseBypassDes "VCBATT1_autopilot1EFuseBypassDesired";
BA_ "Confidence" SG_ 1030 VCBATT1_autopilot1EFuseVoltage 0;
BA_ "Confidence" SG_ 1030 VCBATT1_autopilot1EFuseTemperatu 0;
BA_ "SystemSignalLongSymbol" SG_ 1030 VCBATT1_autopilot1EFuseTemperatu "VCBATT1_autopilot1EFuseTemperature";
BA_ "Confidence" SG_ 1030 VCBATT1_autopilot1EFuseManagerSt 0;
BA_ "SystemSignalLongSymbol" SG_ 1030 VCBATT1_autopilot1EFuseManagerSt "VCBATT1_autopilot1EFuseManagerState";
BA_ "Confidence" SG_ 1030 VCBATT1_autopilot1EFuseHardShort 0;
BA_ "SystemSignalLongSymbol" SG_ 1030 VCBATT1_autopilot1EFuseHardShort "VCBATT1_autopilot1EFuseHardShortThreshold";
BA_ "Confidence" SG_ 1030 VCBATT1_autopilot1EFuseOCThresho 0;
BA_ "SystemSignalLongSymbol" SG_ 1030 VCBATT1_autopilot1EFuseOCThresho "VCBATT1_autopilot1EFuseOCThreshold";
BA_ "Confidence" SG_ 1030 VCBATT1_autopilot1EFuseType 0;
BA_ "Confidence" SG_ 1549 VCBATT1_udsResponseData 1;
BA_ "Confidence" SG_ 1358 VCBATT2_alertID 1;
BA_ "Confidence" SG_ 1358 VCBATT2_alertState 1;
BA_ "Confidence" SG_ 1358 VCBATT2_a059_voltageDrop 1;
BA_ "Confidence" SG_ 1358 VCBATT2_a059_resistanceEstimate 1;
BA_ "Confidence" SG_ 1358 VCBATT2_a059_current 1;
BA_ "Confidence" SG_ 1358 VCBATT2_a063_ADCVoltage 1;
BA_ "SystemSignalLongSymbol" SG_ 1358 VCBATT2_a091_FRONTIPC_faultsAndE "VCBATT2_a091_FRONTIPC_faultsAndExtras";
BA_ "SystemSignalLongSymbol" SG_ 1358 VCBATT2_a098_FRONTIPC_temperatur "VCBATT2_a098_FRONTIPC_temperature";
BA_ "SystemSignalLongSymbol" SG_ 1358 VCBATT2_a098_FRONTIPC_thermalCon "VCBATT2_a098_FRONTIPC_thermalControl";
BA_ "SystemSignalLongSymbol" SG_ 1358 VCBATT2_a106_BATTIPC_dcdcRailSta "VCBATT2_a106_BATTIPC_dcdcRailStatus";
BA_ "SystemSignalLongSymbol" SG_ 1358 VCBATT2_a106_FRONTIPC_thermalCon "VCBATT2_a106_FRONTIPC_thermalControl";
BA_ "SystemSignalLongSymbol" SG_ 1358 VCBATT2_a106_FRONTIPC_dcdcRailSt "VCBATT2_a106_FRONTIPC_dcdcRailStatus";
BA_ "SystemSignalLongSymbol" SG_ 1358 VCBATT2_a108_FRONTIPC_temperatur "VCBATT2_a108_FRONTIPC_temperature";
BA_ "SystemSignalLongSymbol" SG_ 1358 VCBATT2_a108_FRONTIPC_thermalCon "VCBATT2_a108_FRONTIPC_thermalControl";
BA_ "SystemSignalLongSymbol" SG_ 1358 VCBATT2_a108_FRONTIPC_motorStatu "VCBATT2_a108_FRONTIPC_motorStatus";
BA_ "SystemSignalLongSymbol" SG_ 1358 VCBATT2_a120_FRONTIPC_systemStat "VCBATT2_a120_FRONTIPC_systemStatus";
BA_ "SystemSignalLongSymbol" SG_ 1358 VCBATT2_a120_BATTIPC_systemStatu "VCBATT2_a120_BATTIPC_systemStatus";
BA_ "SystemSignalLongSymbol" SG_ 1358 VCBATT2_a120_FRONTIPC_systemPowe "VCBATT2_a120_FRONTIPC_systemPower";
BA_ "SystemSignalLongSymbol" SG_ 1358 VCBATT2_a120_FRONTIPC_autonomyHe "VCBATT2_a120_FRONTIPC_autonomyHealth";
BA_ "SystemSignalLongSymbol" SG_ 1358 VCBATT2_a120_BATTIPC_chassisCont "VCBATT2_a120_BATTIPC_chassisControl2";
BA_ "SystemSignalLongSymbol" SG_ 1358 VCBATT2_a120_FRONTIPC_chassisCon "VCBATT2_a120_FRONTIPC_chassisControl2";
BA_ "SystemSignalLongSymbol" SG_ 1358 VCBATT2_a120_FRONTIPC_odometerSt "VCBATT2_a120_FRONTIPC_odometerStatus";
BA_ "SystemSignalLongSymbol" SG_ 1358 VCBATT2_a133_BATTIPC_primaryActu "VCBATT2_a133_BATTIPC_primaryActuator";
BA_ "SystemSignalLongSymbol" SG_ 1358 VCBATT2_a133_FRONTIPC_secondaryA "VCBATT2_a133_FRONTIPC_secondaryActuator";
BA_ "Confidence" SG_ 1358 VCBATT2_a156_motorCounts 1;
BA_ "Confidence" SG_ 1358 VCBATT2_a157_motorCounts 1;
BA_ "Confidence" SG_ 1358 VCBATT2_a181_vehicleState 1;
BA_ "Confidence" SG_ 1358 VCBATT2_a188_sleepBypassCurrent 1;
BA_ "Confidence" SG_ 1358 VCBATT2_a188_sleepShutdownStep 1;
BA_ "GenSigSNA" SG_ 1358 VCBATT2_a188_sleepShutdownStep "3";
BA_ "Confidence" SG_ 1358 VCBATT2_a188_vehiclePowerState 1;
BA_ "Confidence" SG_ 1358 VCBATT2_a188_timeNotSleeping 1;
BA_ "Confidence" SG_ 1358 VCBATT2_a192_vehiclePowerState 1;
BA_ "Confidence" SG_ 1358 VCBATT2_a192_hvState 1;
BA_ "SystemSignalLongSymbol" SG_ 1358 VCBATT2_a192_notEnoughPowerForSu "VCBATT2_a192_notEnoughPowerForSupport";
BA_ "SystemSignalLongSymbol" SG_ 1358 VCBATT2_a192_contactorEFuseStabl "VCBATT2_a192_contactorEFuseStable";
BA_ "SystemSignalLongSymbol" SG_ 1358 VCBATT2_a192_LVBatteryCannotSupp "VCBATT2_a192_LVBatteryCannotSupportVehicle";
BA_ "Confidence" SG_ 1358 VCBATT2_a192_DI_gear 1;
BA_ "GenSigSNA" SG_ 1358 VCBATT2_a192_DI_gear "7";
BA_ "Confidence" SG_ 1358 VCBATT2_a192_IBSCurrent 1;
BA_ "Confidence" SG_ 1358 VCBATT2_a192_PCSCurrent 1;
BA_ "SystemSignalLongSymbol" SG_ 1358 VCBATT2_a192_HVFaultLoadShedActi "VCBATT2_a192_HVFaultLoadShedActive";
BA_ "SystemSignalLongSymbol" SG_ 1358 VCBATT2_a192_postCrashLoadShedAc "VCBATT2_a192_postCrashLoadShedActive";
BA_ "Confidence" SG_ 1358 VCBATT2_a227_selfTestResult 1;
BA_ "SystemSignalLongSymbol" SG_ 1358 VCBATT2_a227_busVoltageIrrationa "VCBATT2_a227_busVoltageIrrational";
BA_ "SystemSignalLongSymbol" SG_ 1358 VCBATT2_a227_motorSpeedIrrationa "VCBATT2_a227_motorSpeedIrrational";
BA_ "SystemSignalLongSymbol" SG_ 1358 VCBATT2_a227_supplyVoltageIrrati "VCBATT2_a227_supplyVoltageIrrational";
BA_ "SystemSignalLongSymbol" SG_ 1358 VCBATT2_a227_motorPhaseCurrentIr "VCBATT2_a227_motorPhaseCurrentIrrational";
BA_ "SystemSignalLongSymbol" SG_ 1358 VCBATT2_a227_hsVdsOvervoltageMas "VCBATT2_a227_hsVdsOvervoltageMask";
BA_ "SystemSignalLongSymbol" SG_ 1358 VCBATT2_a227_lsVdsOvervoltageMas "VCBATT2_a227_lsVdsOvervoltageMask";
BA_ "Confidence" SG_ 1358 VCBATT2_a300_oldType 1;
BA_ "Confidence" SG_ 1358 VCBATT2_a300_newType 1;
BA_ "Confidence" SG_ 1358 VCBATT2_a303_vehicleSpeed 1;
BA_ "Confidence" SG_ 1358 VCBATT2_a303_postVoltage 1;
BA_ "Confidence" SG_ 1358 VCBATT2_a303_lockStatus 1;
BA_ "GenSigSNA" SG_ 1358 VCBATT2_a303_lockStatus "0";
BA_ "Confidence" SG_ 1358 VCBATT2_a304_voltage 1;
BA_ "Confidence" SG_ 1358 VCBATT2_a304_temperature 1;
BA_ "Confidence" SG_ 1358 VCBATT2_a305_voltage 1;
BA_ "Confidence" SG_ 1358 VCBATT2_a305_temperature 1;
BA_ "Confidence" SG_ 1358 VCBATT2_a305_actuatorCurrent 1;
BA_ "Confidence" SG_ 1358 VCBATT2_a306_voltage 1;
BA_ "Confidence" SG_ 1358 VCBATT2_a306_temperature 1;
BA_ "Confidence" SG_ 1358 VCBATT2_a306_actuatorCurrent 1;
BA_ "Confidence" SG_ 1358 VCBATT2_a309_vehicleSpeed 1;
BA_ "Confidence" SG_ 1358 VCBATT2_a309_switchVoltage 1;
BA_ "Confidence" SG_ 1358 VCBATT2_a309_lockStatus 1;
BA_ "GenSigSNA" SG_ 1358 VCBATT2_a309_lockStatus "0";
BA_ "Confidence" SG_ 1358 VCBATT2_a353_wiperHeaterCurrent 1;
BA_ "Confidence" SG_ 1358 VCBATT2_a353_batteryVoltage 1;
BA_ "Confidence" SG_ 1358 VCBATT2_a353_ambientTemperature 1;
BA_ "GenSigSNA" SG_ 1358 VCBATT2_a353_ambientTemperature "0";
BA_ "Confidence" SG_ 1358 VCBATT2_a354_windshieldCameraHea 1;
BA_ "SystemSignalLongSymbol" SG_ 1358 VCBATT2_a354_windshieldCameraHea "VCBATT2_a354_windshieldCameraHeaterCurrent";
BA_ "Confidence" SG_ 1358 VCBATT2_a354_batteryVoltage 1;
BA_ "Confidence" SG_ 1358 VCBATT2_a354_ambientTemperature 1;
BA_ "GenSigSNA" SG_ 1358 VCBATT2_a354_ambientTemperature "0";
BA_ "SystemSignalLongSymbol" SG_ 1358 VCBATT2_a389_faultedWhileOpenAtS "VCBATT2_a389_faultedWhileOpenAtSpeed";
BA_ "Confidence" SG_ 1358 VCBATT2_a389_vehicleSpeed 1;
BA_ "Confidence" SG_ 1358 VCBATT2_a389_temperature 1;
BA_ "Confidence" SG_ 1358 VCBATT2_a389_latchStatus 1;
BA_ "GenSigSNA" SG_ 1358 VCBATT2_a389_latchStatus "0";
BA_ "Confidence" SG_ 1358 VCBATT2_a391_switch1VoltageAvera 1;
BA_ "SystemSignalLongSymbol" SG_ 1358 VCBATT2_a391_switch1VoltageAvera "VCBATT2_a391_switch1VoltageAverage";
BA_ "Confidence" SG_ 1358 VCBATT2_a391_switch1VoltageInsta 1;
BA_ "SystemSignalLongSymbol" SG_ 1358 VCBATT2_a391_switch1VoltageInsta "VCBATT2_a391_switch1VoltageInstant";
BA_ "Confidence" SG_ 1358 VCBATT2_a391_switch2VoltageAvera 1;
BA_ "SystemSignalLongSymbol" SG_ 1358 VCBATT2_a391_switch2VoltageAvera "VCBATT2_a391_switch2VoltageAverage";
BA_ "Confidence" SG_ 1358 VCBATT2_a391_switch2VoltageInsta 1;
BA_ "SystemSignalLongSymbol" SG_ 1358 VCBATT2_a391_switch2VoltageInsta "VCBATT2_a391_switch2VoltageInstant";
BA_ "Confidence" SG_ 1358 VCBATT2_a463_switch1VoltageAvera 1;
BA_ "SystemSignalLongSymbol" SG_ 1358 VCBATT2_a463_switch1VoltageAvera "VCBATT2_a463_switch1VoltageAverage";
BA_ "Confidence" SG_ 1358 VCBATT2_a463_switch1VoltageInsta 1;
BA_ "SystemSignalLongSymbol" SG_ 1358 VCBATT2_a463_switch1VoltageInsta "VCBATT2_a463_switch1VoltageInstant";
BA_ "Confidence" SG_ 1358 VCBATT2_a463_switch2VoltageAvera 1;
BA_ "SystemSignalLongSymbol" SG_ 1358 VCBATT2_a463_switch2VoltageAvera "VCBATT2_a463_switch2VoltageAverage";
BA_ "Confidence" SG_ 1358 VCBATT2_a463_switch2VoltageInsta 1;
BA_ "SystemSignalLongSymbol" SG_ 1358 VCBATT2_a463_switch2VoltageInsta "VCBATT2_a463_switch2VoltageInstant";
BA_ "Confidence" SG_ 1358 VCBATT2_a485_mcuGamingEFuseCurre 1;
BA_ "SystemSignalLongSymbol" SG_ 1358 VCBATT2_a485_mcuGamingEFuseCurre "VCBATT2_a485_mcuGamingEFuseCurrent";
BA_ "Confidence" SG_ 1358 VCBATT2_a516_IBSVoltage 1;
BA_ "Confidence" SG_ 1358 VCBATT2_a516_HVSoc 1;
BA_ "SystemSignalLongSymbol" SG_ 1358 VCBATT2_a516_contactorsPermanent "VCBATT2_a516_contactorsPermanentlyClosed";
BA_ "SystemSignalLongSymbol" SG_ 1358 VCBATT2_a516_LVBatteryDisconnect "VCBATT2_a516_LVBatteryDisconnected";
BA_ "SystemSignalLongSymbol" SG_ 1358 VCBATT2_a516_LVBatteryCannotSupp "VCBATT2_a516_LVBatteryCannotSupportVehicle";
BA_ "Confidence" SG_ 1358 VCBATT2_a517_IBSVoltage 1;
BA_ "Confidence" SG_ 1358 VCBATT2_a517_HVSoc 1;
BA_ "Confidence" SG_ 1358 VCBATT2_a522_IBSVoltage 1;
BA_ "Confidence" SG_ 1358 VCBATT2_a522_HVSoc 1;
BA_ "SystemSignalLongSymbol" SG_ 1358 VCBATT2_a522_contactorsPermanent "VCBATT2_a522_contactorsPermanentlyClosed";
BA_ "SystemSignalLongSymbol" SG_ 1358 VCBATT2_a522_LVBatteryDisconnect "VCBATT2_a522_LVBatteryDisconnected";
BA_ "SystemSignalLongSymbol" SG_ 1358 VCBATT2_a522_LVBatteryCannotSupp "VCBATT2_a522_LVBatteryCannotSupportVehicle";
BA_ "Confidence" SG_ 1358 VCBATT2_a548_vehiclePowerState 1;
BA_ "SystemSignalLongSymbol" SG_ 1358 VCBATT2_a548_notEnoughPowerForSu "VCBATT2_a548_notEnoughPowerForSupport";
BA_ "SystemSignalLongSymbol" SG_ 1358 VCBATT2_a548_LVBatteryCannotSupp "VCBATT2_a548_LVBatteryCannotSupportVehicle";
BA_ "Confidence" SG_ 1358 VCBATT2_a548_DI_gear 1;
BA_ "GenSigSNA" SG_ 1358 VCBATT2_a548_DI_gear "7";
BA_ "Confidence" SG_ 1358 VCBATT2_a548_backstopBucketCount 1;
BA_ "Confidence" SG_ 1358 VCBATT2_a548_hvState 1;
BA_ "Confidence" SG_ 1358 VCBATT2_a548_ampHourBucketCount 1;
BA_ "Confidence" SG_ 1358 VCBATT2_a548_LVBMSSOC 1;
BA_ "Confidence" SG_ 1358 VCBATT2_a548_PCSTargetVoltage 1;
BA_ "SystemSignalLongSymbol" SG_ 1358 VCBATT2_a548_HVNotConfirmedUpTri "VCBATT2_a548_HVNotConfirmedUpTrigger";
BA_ "SystemSignalLongSymbol" SG_ 1358 VCBATT2_a548_PCSNotMeetingTarget "VCBATT2_a548_PCSNotMeetingTargetTrigger";
BA_ "Confidence" SG_ 1358 VCBATT2_a610_switch1State 1;
BA_ "GenSigSNA" SG_ 1358 VCBATT2_a610_switch1State "0";
BA_ "Confidence" SG_ 1358 VCBATT2_a610_switch2State 1;
BA_ "GenSigSNA" SG_ 1358 VCBATT2_a610_switch2State "0";
BA_ "Confidence" SG_ 1358 VCBATT2_a610_temperature 1;
BA_ "GenSigSNA" SG_ 1358 VCBATT2_a610_temperature "0";
BA_ "Confidence" SG_ 1358 VCBATT2_a668_hcmRegionAndSide 1;
BA_ "GenSigSNA" SG_ 1358 VCBATT2_a668_hcmRegionAndSide "0";
BA_ "Confidence" SG_ 1358 VCBATT2_a668_homologationRegionO 1;
BA_ "SystemSignalLongSymbol" SG_ 1358 VCBATT2_a668_homologationRegionO "VCBATT2_a668_homologationRegionOverride";
BA_ "SystemSignalLongSymbol" SG_ 1358 VCBATT2_a698_isVirtualPitchSenso "VCBATT2_a698_isVirtualPitchSensor";
BA_ "Confidence" SG_ 1358 VCBATT2_a698_calibratedVerticalP 1;
BA_ "GenSigSNA" SG_ 1358 VCBATT2_a698_calibratedVerticalP "1023";
BA_ "SystemSignalLongSymbol" SG_ 1358 VCBATT2_a698_calibratedVerticalP "VCBATT2_a698_calibratedVerticalPositionHCMR";
BA_ "Confidence" SG_ 1358 VCBATT2_a698_calibratedHorizonta 1;
BA_ "GenSigSNA" SG_ 1358 VCBATT2_a698_calibratedHorizonta "1023";
BA_ "SystemSignalLongSymbol" SG_ 1358 VCBATT2_a698_calibratedHorizonta "VCBATT2_a698_calibratedHorizontalPositionHCMR";
BA_ "Confidence" SG_ 975 VCBATT2_matrixIndex 1;
BA_ "SystemSignalLongSymbol" SG_ 975 VCBATT2_a123_VC_SECONDARY_LIGHTI "VCBATT2_a123_VC_SECONDARY_LIGHTING_LEADER_MIA";
BA_ "SystemSignalLongSymbol" SG_ 975 VCBATT2_a143_powerLossDuringSlee "VCBATT2_a143_powerLossDuringSleep";
BA_ "SystemSignalLongSymbol" SG_ 975 VCBATT2_a186_washerFluidLowFasci "VCBATT2_a186_washerFluidLowFasciaAndRepeater";
BA_ "SystemSignalLongSymbol" SG_ 975 VCBATT2_a187_washerFluidLowPasse "VCBATT2_a187_washerFluidLowPassengerWiper";
BA_ "SystemSignalLongSymbol" SG_ 975 VCBATT2_a292_sideMarkerLightPipe "VCBATT2_a292_sideMarkerLightPipeFault";
BA_ "SystemSignalLongSymbol" SG_ 975 VCBATT2_a295_rightSideRepeaterLi "VCBATT2_a295_rightSideRepeaterLightFault";
BA_ "SystemSignalLongSymbol" SG_ 975 VCBATT2_a299_homelinkConfigurati "VCBATT2_a299_homelinkConfigurationFailed";
BA_ "SystemSignalLongSymbol" SG_ 975 VCBATT2_a300_louverActuatorSwapD "VCBATT2_a300_louverActuatorSwapDetected";
BA_ "SystemSignalLongSymbol" SG_ 975 VCBATT2_a303_frunkAccessPostActi "VCBATT2_a303_frunkAccessPostActive";
BA_ "SystemSignalLongSymbol" SG_ 975 VCBATT2_a306_frunkPriUnderCurren "VCBATT2_a306_frunkPriUnderCurrent";
BA_ "SystemSignalLongSymbol" SG_ 975 VCBATT2_a309_frunkEmergencyRelea "VCBATT2_a309_frunkEmergencyReleasePressed";
BA_ "SystemSignalLongSymbol" SG_ 975 VCBATT2_a353_wiperHeaterUndercur "VCBATT2_a353_wiperHeaterUndercurrent";
BA_ "SystemSignalLongSymbol" SG_ 975 VCBATT2_a354_windshieldCameraHea "VCBATT2_a354_windshieldCameraHeaterUndercurrent";
BA_ "SystemSignalLongSymbol" SG_ 975 VCBATT2_a361_washerFluidLowMomen "VCBATT2_a361_washerFluidLowMomentary";
BA_ "SystemSignalLongSymbol" SG_ 975 VCBATT2_a364_heaterTypeEstimatio "VCBATT2_a364_heaterTypeEstimationChanged";
BA_ "SystemSignalLongSymbol" SG_ 975 VCBATT2_a389_frunkInhibitingRele "VCBATT2_a389_frunkInhibitingReleaseAtSpeed";
BA_ "SystemSignalLongSymbol" SG_ 975 VCBATT2_a391_frunkLatchSwitchFau "VCBATT2_a391_frunkLatchSwitchFault";
BA_ "SystemSignalLongSymbol" SG_ 975 VCBATT2_a399_frunkNeverReportedO "VCBATT2_a399_frunkNeverReportedOpen";
BA_ "SystemSignalLongSymbol" SG_ 975 VCBATT2_a471_emergencyFrunkButto "VCBATT2_a471_emergencyFrunkButtonPressIgnored";
BA_ "SystemSignalLongSymbol" SG_ 975 VCBATT2_a475_rightHeadlampIntern "VCBATT2_a475_rightHeadlampInternalError";
BA_ "SystemSignalLongSymbol" SG_ 975 VCBATT2_a520_rightHeadlampIntern "VCBATT2_a520_rightHeadlampInternalErrorV2";
BA_ "SystemSignalLongSymbol" SG_ 975 VCBATT2_a522_hibernationActiveLo "VCBATT2_a522_hibernationActiveLogCapture";
BA_ "SystemSignalLongSymbol" SG_ 975 VCBATT2_a524_rightHeadlampAiming "VCBATT2_a524_rightHeadlampAimingFault";
BA_ "SystemSignalLongSymbol" SG_ 975 VCBATT2_a557_rightHeadlampIntern "VCBATT2_a557_rightHeadlampInternalErrorV3";
BA_ "SystemSignalLongSymbol" SG_ 975 VCBATT2_a558_rightHeadlampAiming "VCBATT2_a558_rightHeadlampAimingDebug";
BA_ "SystemSignalLongSymbol" SG_ 975 VCBATT2_a567_rightFrontTurnLight "VCBATT2_a567_rightFrontTurnLightFault";
BA_ "SystemSignalLongSymbol" SG_ 975 VCBATT2_a569_rightDaytimeRunning "VCBATT2_a569_rightDaytimeRunningLightFault";
BA_ "SystemSignalLongSymbol" SG_ 975 VCBATT2_a575_frontOilPumpEFuseTr "VCBATT2_a575_frontOilPumpEFuseTrip";
BA_ "SystemSignalLongSymbol" SG_ 975 VCBATT2_a578_vbattFusedLowCurren "VCBATT2_a578_vbattFusedLowCurrentFeedEFuseTrip";
BA_ "SystemSignalLongSymbol" SG_ 975 VCBATT2_a583_frunkSwitchGroupDis "VCBATT2_a583_frunkSwitchGroupDisagreementDebug";
BA_ "SystemSignalLongSymbol" SG_ 975 VCBATT2_a584_frunkSwitchGroupDeb "VCBATT2_a584_frunkSwitchGroupDebug";
BA_ "SystemSignalLongSymbol" SG_ 975 VCBATT2_a586_rightLowOrHighBeamL "VCBATT2_a586_rightLowOrHighBeamLightCondition";
BA_ "SystemSignalLongSymbol" SG_ 975 VCBATT2_a610_frunkOpenFailureMet "VCBATT2_a610_frunkOpenFailureMetricSet";
BA_ "SystemSignalLongSymbol" SG_ 975 VCBATT2_a619_frunkSwitchReleaseT "VCBATT2_a619_frunkSwitchReleaseTimeDBG";
BA_ "SystemSignalLongSymbol" SG_ 975 VCBATT2_a624_rightHeadlampIntern "VCBATT2_a624_rightHeadlampInternalErrorV4";
BA_ "SystemSignalLongSymbol" SG_ 975 VCBATT2_a631_rightHeadlampFactor "VCBATT2_a631_rightHeadlampFactoryFault";
BA_ "SystemSignalLongSymbol" SG_ 975 VCBATT2_a634_indeterminateSwitch "VCBATT2_a634_indeterminateSwitchTransitionDetectedDbg";
BA_ "SystemSignalLongSymbol" SG_ 975 VCBATT2_a643_rightHeadlampUartCo "VCBATT2_a643_rightHeadlampUartCondition";
BA_ "SystemSignalLongSymbol" SG_ 975 VCBATT2_a644_washPumpHealthCalcu "VCBATT2_a644_washPumpHealthCalculationDbg0";
BA_ "SystemSignalLongSymbol" SG_ 975 VCBATT2_a645_washPumpHealthCalcu "VCBATT2_a645_washPumpHealthCalculationDbg1";
BA_ "SystemSignalLongSymbol" SG_ 975 VCBATT2_a646_washPumpHealthCalcu "VCBATT2_a646_washPumpHealthCalculationDbg2";
BA_ "SystemSignalLongSymbol" SG_ 975 VCBATT2_a649_persistAccPortPower "VCBATT2_a649_persistAccPortPowerReqOverridden";
BA_ "SystemSignalLongSymbol" SG_ 975 VCBATT2_a650_powerConsumptionInf "VCBATT2_a650_powerConsumptionInfo";
BA_ "SystemSignalLongSymbol" SG_ 975 VCBATT2_a662_mculessRightHeadlam "VCBATT2_a662_mculessRightHeadlampCurrentAlertDbg";
BA_ "SystemSignalLongSymbol" SG_ 975 VCBATT2_a664_rightHeadlampUartWa "VCBATT2_a664_rightHeadlampUartWaterMarkWarning";
BA_ "SystemSignalLongSymbol" SG_ 975 VCBATT2_a666_rightHeadlampRetryI "VCBATT2_a666_rightHeadlampRetryInfo";
BA_ "SystemSignalLongSymbol" SG_ 975 VCBATT2_a668_rightHeadlampRegion "VCBATT2_a668_rightHeadlampRegionOrSideMismatch";
BA_ "SystemSignalLongSymbol" SG_ 975 VCBATT2_a698_rightHeadlampNotAim "VCBATT2_a698_rightHeadlampNotAimed";
BA_ "SystemSignalLongSymbol" SG_ 975 VCBATT2_a702_dynamicHeadlightLev "VCBATT2_a702_dynamicHeadlightLevelingUnavailable";
BA_ "Confidence" SG_ 1399 VCBATT2_vehiclePowerStateDBG 0;
BA_ "Confidence" SG_ 1399 VCBATT2_nmWakeUpReasonDBG 0;
BA_ "Confidence" SG_ 1399 VCBATT2_nmKeepAwakeReasonDBG 0;
BA_ "GenSigSNA" SG_ 1399 VCBATT2_nmKeepAwakeReasonDBG "0";
BA_ "Confidence" SG_ 1399 VCBATT2_LIN_bus_0_busErrorCount 0;
BA_ "Confidence" SG_ 1399 VCBATT2_LIN_bus_1_busErrorCount 0;
BA_ "Confidence" SG_ 1399 VCBATT2_hibernationStateDBG 0;
BA_ "Confidence" SG_ 1567 VCBATT2_udsResponseData 1;
BA_ "Confidence" SG_ 945 VCBATT_LVHealthChecksum 0;
BA_ "Confidence" SG_ 945 VCBATT_LVHealthCounter 0;
BA_ "Confidence" SG_ 945 VCBATT_LVHealthStatus 0;
BA_ "Confidence" SG_ 945 VCBATT_LVStatusForDrive 0;
BA_ "Confidence" SG_ 945 VCBATT_LVPowerSecondsToSafeHarbo 0;
BA_ "SystemSignalLongSymbol" SG_ 945 VCBATT_LVPowerSecondsToSafeHarbo "VCBATT_LVPowerSecondsToSafeHarbor";
BA_ "Confidence" SG_ 945 VCBATT_autonomyBehavior 0;
BA_ "Confidence" SG_ 945 VCBATT_hardwareProtectionsArmed 0;
BA_ "Confidence" SG_ 945 VCBATT_12vStatusForDrive 0;
BA_ "Confidence" SG_ 1090 VCBATT_pcsInterfaceMuxIndex 1;
BA_ "Confidence" SG_ 1090 VCBATT_pcsInterfaceCounter 0;
BA_ "Confidence" SG_ 1090 VCBATT_pcsInterfaceChecksum 0;
BA_ "Confidence" SG_ 1090 VCBATT_pcsLVVoltageTarget 0;
BA_ "Confidence" SG_ 1090 VCBATT_pcsLVMinVoltageLimit 0;
BA_ "Confidence" SG_ 1090 VCBATT_pcsLVMaxVoltageLimit 0;
BA_ "Confidence" SG_ 1090 VCBATT_goodForPCSPowerCycle 0;
BA_ "Confidence" SG_ 1090 VCBATT_LVBatteryCannotSupportVeh 0;
BA_ "SystemSignalLongSymbol" SG_ 1090 VCBATT_LVBatteryCannotSupportVeh "VCBATT_LVBatteryCannotSupportVehicle";
BA_ "Confidence" SG_ 1090 VCBATT_pcsResistanceFiltered 0;
BA_ "GenSigSNA" SG_ 1090 VCBATT_pcsResistanceFiltered "65535";
BA_ "Confidence" SG_ 1090 VCBATT_pcsLVMaxDchrgCurrentLimit 0;
BA_ "Confidence" SG_ 1090 VCBATT_defaultPcsLVVoltageTarget 0;
BA_ "Confidence" SG_ 1090 VCBATT_lvHwProtSelfTestActive 0;
BA_ "Confidence" SG_ 1090 VCBATT_lvBatteryDischargeRequest 0;
BA_ "Confidence" SG_ 1587 VCBATT_udsResponseData 1;
BA_ "Confidence" SG_ 1994 VCCC_infoIndex 1;
BA_ "Confidence" SG_ 1994 VCCC_infoBuildType 0;
BA_ "Confidence" SG_ 1994 VCCC_infoBuildConfigId 0;
BA_ "Confidence" SG_ 1994 VCCC_infoHardwareId 0;
BA_ "Confidence" SG_ 1994 VCCC_infoComponentId 0;
BA_ "Confidence" SG_ 1994 VCCC_infoPcbaId 0;
BA_ "Confidence" SG_ 1994 VCCC_infoAssemblyId 0;
BA_ "GenSigSNA" SG_ 1994 VCCC_infoAssemblyId "255";
BA_ "Confidence" SG_ 1994 VCCC_infoUsageId 0;
BA_ "Confidence" SG_ 1994 VCCC_infoSubUsageId 0;
BA_ "Confidence" SG_ 1994 VCCC_infoAppCrc 0;
BA_ "Confidence" SG_ 1994 VCCC_infoAppGitHash 0;
BA_ "Confidence" SG_ 1994 VCCC_infoBootGitHash 0;
BA_ "Confidence" SG_ 1994 VCCC_infoBootUdsProtoVersion 0;
BA_ "Confidence" SG_ 1994 VCCC_infoBootCrc 0;
VAL_ 974 VCBATT1_matrixIndex 11 "AlertMatrix11" 10 "AlertMatrix10" 9 "AlertMatrix9" 8 "AlertMatrix8" 7 "AlertMatrix7" 6 "AlertMatrix6" 5 "AlertMatrix5" 4 "AlertMatrix4" 3 "AlertMatrix3" 2 "AlertMatrix2" 1 "AlertMatrix1" 0 "AlertMatrix0" ;
VAL_ 1030 VCBATT1_eFuseDebugStatusIndex 7 "SLEEP_BYPASS" 6 "MCU_LOGIC" 5 "BRAKE_MOTOR_ECU_1" 4 "LOADSHED" 3 "AUTOPILOT_1" 2 "BAT_BRIDGE" 1 "EPAS1" 0 "VCLEFT" ;
VAL_ 1030 VCBATT1_leftControllerEFuseState 7 "SELF_TEST" 6 "SELF_TEST_PREP" 5 "FAILSAFE" 4 "LOCKED" 3 "UNLOCKED" 2 "CONFIGURATION" 1 "WAKEUP" 0 "STANDBY" ;
VAL_ 1030 VCBATT1_leftControllerEFuseManag 8 "LOCKOUT" 7 "IDLE" 6 "UNLOCKING" 5 "LOCKED_ON_BOOT" 4 "LOCKING" 3 "STANDBY" 2 "WAKEUP" 1 "OFF" 0 "RESETTING" ;
VAL_ 1030 VCBATT1_leftControllerEFuseHardS 15 "160_MV" 14 "139_3_MV" 13 "121_3_MV" 12 "105_6_MV" 11 "91_9_MV" 10 "80_MV" 9 "69_6_MV" 8 "60_6_MV" 7 "52_8_MV" 6 "45_9_MV" 5 "40_MV" 4 "34_8_MV" 3 "30_3_MV" 2 "26_4_MV" 1 "23_MV" 0 "20_MV" ;
VAL_ 1030 VCBATT1_leftControllerEFuseOCThr 31 "89_3_MV" 30 "78_8_MV" 29 "69_5_MV" 28 "61_3_MV" 27 "54_MV" 26 "50_6_MV" 25 "47_5_MV" 24 "44_5_MV" 23 "41_7_MV" 22 "39_1_MV" 21 "36_6_MV" 20 "34_3_MV" 19 "32_2_MV" 18 "30_1_MV" 17 "28_2_MV" 16 "26_5_MV" 15 "24_8_MV" 14 "23_3_MV" 13 "21_8_MV" 12 "20_4_MV" 11 "19_1_MV" 10 "17_9_MV" 9 "16_8_MV" 8 "15_8_MV" 7 "14_8_MV" 6 "13_8_MV" 5 "13_MV" 4 "11_8_MV" 3 "10_4_MV" 2 "8_7_MV" 1 "7_2_MV" 0 "6_MV" ;
VAL_ 1030 VCBATT1_leftControllerEFuseType 2 "VNF1248" 1 "VNF1048" 0 "UNKNOWN" ;
VAL_ 1030 VCBATT1_EPAS1EFuseState 7 "SELF_TEST" 6 "SELF_TEST_PREP" 5 "FAILSAFE" 4 "LOCKED" 3 "UNLOCKED" 2 "CONFIGURATION" 1 "WAKEUP" 0 "STANDBY" ;
VAL_ 1030 VCBATT1_EPAS1EFuseManagerState 8 "LOCKOUT" 7 "IDLE" 6 "UNLOCKING" 5 "LOCKED_ON_BOOT" 4 "LOCKING" 3 "STANDBY" 2 "WAKEUP" 1 "OFF" 0 "RESETTING" ;
VAL_ 1030 VCBATT1_EPAS1EFuseHardShortThres 15 "160_MV" 14 "139_3_MV" 13 "121_3_MV" 12 "105_6_MV" 11 "91_9_MV" 10 "80_MV" 9 "69_6_MV" 8 "60_6_MV" 7 "52_8_MV" 6 "45_9_MV" 5 "40_MV" 4 "34_8_MV" 3 "30_3_MV" 2 "26_4_MV" 1 "23_MV" 0 "20_MV" ;
VAL_ 1030 VCBATT1_EPAS1EFuseOCThreshold 31 "89_3_MV" 30 "78_8_MV" 29 "69_5_MV" 28 "61_3_MV" 27 "54_MV" 26 "50_6_MV" 25 "47_5_MV" 24 "44_5_MV" 23 "41_7_MV" 22 "39_1_MV" 21 "36_6_MV" 20 "34_3_MV" 19 "32_2_MV" 18 "30_1_MV" 17 "28_2_MV" 16 "26_5_MV" 15 "24_8_MV" 14 "23_3_MV" 13 "21_8_MV" 12 "20_4_MV" 11 "19_1_MV" 10 "17_9_MV" 9 "16_8_MV" 8 "15_8_MV" 7 "14_8_MV" 6 "13_8_MV" 5 "13_MV" 4 "11_8_MV" 3 "10_4_MV" 2 "8_7_MV" 1 "7_2_MV" 0 "6_MV" ;
VAL_ 1030 VCBATT1_EPAS1EFuseType 2 "VNF1248" 1 "VNF1048" 0 "UNKNOWN" ;
VAL_ 1030 VCBATT1_autopilot1EFuseState 7 "SELF_TEST" 6 "SELF_TEST_PREP" 5 "FAILSAFE" 4 "LOCKED" 3 "UNLOCKED" 2 "CONFIGURATION" 1 "WAKEUP" 0 "STANDBY" ;
VAL_ 1030 VCBATT1_autopilot1EFuseManagerSt 8 "LOCKOUT" 7 "IDLE" 6 "UNLOCKING" 5 "LOCKED_ON_BOOT" 4 "LOCKING" 3 "STANDBY" 2 "WAKEUP" 1 "OFF" 0 "RESETTING" ;
VAL_ 1030 VCBATT1_autopilot1EFuseHardShort 15 "160_MV" 14 "139_3_MV" 13 "121_3_MV" 12 "105_6_MV" 11 "91_9_MV" 10 "80_MV" 9 "69_6_MV" 8 "60_6_MV" 7 "52_8_MV" 6 "45_9_MV" 5 "40_MV" 4 "34_8_MV" 3 "30_3_MV" 2 "26_4_MV" 1 "23_MV" 0 "20_MV" ;
VAL_ 1030 VCBATT1_autopilot1EFuseOCThresho 31 "89_3_MV" 30 "78_8_MV" 29 "69_5_MV" 28 "61_3_MV" 27 "54_MV" 26 "50_6_MV" 25 "47_5_MV" 24 "44_5_MV" 23 "41_7_MV" 22 "39_1_MV" 21 "36_6_MV" 20 "34_3_MV" 19 "32_2_MV" 18 "30_1_MV" 17 "28_2_MV" 16 "26_5_MV" 15 "24_8_MV" 14 "23_3_MV" 13 "21_8_MV" 12 "20_4_MV" 11 "19_1_MV" 10 "17_9_MV" 9 "16_8_MV" 8 "15_8_MV" 7 "14_8_MV" 6 "13_8_MV" 5 "13_MV" 4 "11_8_MV" 3 "10_4_MV" 2 "8_7_MV" 1 "7_2_MV" 0 "6_MV" ;
VAL_ 1030 VCBATT1_autopilot1EFuseType 2 "VNF1248" 1 "VNF1048" 0 "UNKNOWN" ;
VAL_ 1358 VCBATT2_alertID 702 "a702_dynamicHeadlightLevelingUnavailable" 698 "a698_rightHeadlampNotAimed" 668 "a668_rightHeadlampRegionOrSideMismatch" 666 "a666_rightHeadlampRetryInfo" 664 "a664_rightHeadlampUartWaterMarkWarning" 662 "a662_mculessRightHeadlampCurrentAlertDbg" 650 "a650_powerConsumptionInfo" 649 "a649_persistAccPortPowerReqOverridden" 646 "a646_washPumpHealthCalculationDbg2" 645 "a645_washPumpHealthCalculationDbg1" 644 "a644_washPumpHealthCalculationDbg0" 643 "a643_rightHeadlampUartCondition" 634 "a634_indeterminateSwitchTransitionDetectedDbg" 631 "a631_rightHeadlampFactoryFault" 624 "a624_rightHeadlampInternalErrorV4" 619 "a619_frunkSwitchReleaseTimeDBG" 617 "a617_APP_MIA" 610 "a610_frunkOpenFailureMetricSet" 586 "a586_rightLowOrHighBeamLightCondition" 584 "a584_frunkSwitchGroupDebug" 583 "a583_frunkSwitchGroupDisagreementDebug" 578 "a578_vbattFusedLowCurrentFeedEFuseTrip" 575 "a575_frontOilPumpEFuseTrip" 569 "a569_rightDaytimeRunningLightFault" 567 "a567_rightFrontTurnLightFault" 558 "a558_rightHeadlampAimingDebug" 557 "a557_rightHeadlampInternalErrorV3" 548 "a548_HVFaultLoadShed" 547 "a547_postCrashLoadShed" 524 "a524_rightHeadlampAimingFault" 522 "a522_hibernationActiveLogCapture" 520 "a520_rightHeadlampInternalErrorV2" 517 "a517_hibernationRecovery" 516 "a516_hibernationActive" 486 "a486_sleepPowerDebug" 485 "a485_mcuGamingEFuseFault" 475 "a475_rightHeadlampInternalError" 471 "a471_emergencyFrunkButtonPressIgnored" 463 "a463_frunkSensorService" 423 "a423_rtosSleepFailed" 399 "a399_frunkNeverReportedOpen" 391 "a391_frunkLatchSwitchFault" 389 "a389_frunkInhibitingReleaseAtSpeed" 364 "a364_heaterTypeEstimationChanged" 361 "a361_washerFluidLowMomentary" 354 "a354_windshieldCameraHeaterUndercurrent" 353 "a353_wiperHeaterUndercurrent" 309 "a309_frunkEmergencyReleasePressed" 306 "a306_frunkPriUnderCurrent" 305 "a305_frunkPriOverCurrent" 304 "a304_frunkReleaseFailed" 303 "a303_frunkAccessPostActive" 300 "a300_louverActuatorSwapDetected" 299 "a299_homelinkConfigurationFailed" 295 "a295_rightSideRepeaterLightFault" 292 "a292_sideMarkerLightPipeFault" 291 "a291_rightFogLightFault" 290 "a290_leftFogLightFault" 241 "a241_radFanMIA" 227 "a227_radFanCompromised" 211 "a211_I2CFault" 209 "a209_brakeFluidSNA" 208 "a208_brakeFluidLow" 192 "a192_vehicleLoadShed" 188 "a188_sleepFailed" 187 "a187_washerFluidLowPassengerWiper" 186 "a186_washerFluidLowFasciaAndRepeater" 185 "a185_washerFluidLow" 181 "a181_homelinkMIA" 166 "a166_rightHCMMIA" 158 "a158_louverDisconnected" 157 "a157_louverBreakage" 156 "a156_louverBlockage" 144 "a144_EPAS3S_MIA" 143 "a143_powerLossDuringSleep" 133 "a133_BRAKE_MIA" 131 "a131_PCSCOMMON_MIA" 126 "a126_EPAS3P_MIA" 125 "a125_SCCM_MIA" 124 "a124_BB_MIA" 123 "a123_VC_SECONDARY_LIGHTING_LEADER_MIA" 122 "a122_ICR_MIA" 120 "a120_DI_DRIVE_MIA" 119 "a119_SCCM_MIA" 118 "a118_VCFRONT_MIA" 117 "a117_VCLEFT_MIA" 116 "a116_VCRIGHT_MIA" 115 "a115_VCSEC_MIA" 114 "a114_ESP_MIA" 113 "a113_UI_MIA" 112 "a112_EPBL_MIA" 111 "a111_EPBR_MIA" 110 "a110_GTW_MIA" 109 "a109_RCM_MIA" 108 "a108_DIF_MIA" 107 "a107_BMS_MIA" 106 "a106_PCS_MIA" 105 "a105_TAS_MIA" 104 "a104_DAS_MIA" 103 "a103_CP_MIA" 100 "a100_CANbus_MIA" 98 "a098_DIR_MIA" 96 "a096_OCS1P_MIA" 91 "a091_CMPD_MIA" 90 "a090_APS_MIA" 86 "a086_VCBATT_MIA" 82 "a082_VCFRONT2_MIA" 81 "a081_VCFRONT1_MIA" 80 "a080_VCFRONT0_MIA" 79 "a079_VCBATT2_MIA" 78 "a078_VCBATT1_MIA" 77 "a077_VCBATT0_MIA" 64 "a064_busSleepReqTimeout" 63 "a063_SwitchFault" 62 "a062_XCPWasConnected" 61 "a061_XCPConnected" 60 "a060_engineeringBuild" 59 "a059_inputResistanceHigh" 58 "a058_inputRHighSyncDebug" 46 "a046_Task1000msError" 45 "a045_Task100msError" 44 "a044_Task10msError" 43 "a043_Task1msError" 42 "a042_HighStackUsage" 41 "a041_HighCPULoad" 40 "a040_Backtrace" 39 "a039_ProtFaultAddress" 38 "a038_ProtFaultInfo" 37 "a037_MemManageFault" 36 "a036_UnknownIrq" 31 "a031_UDSActive" 30 "a030_ECULogUploadRequest" 29 "a029_CoreDump" 28 "a028_UsageFault" 22 "a022_TaskInitError" 21 "a021_TaskSchedulerError" 19 "a019_BusFault" 18 "a018_HardFault" 17 "a017_NVMMStatusDbg" 16 "a016_NVMMRecordError" 15 "a015_NVMMError" 13 "a013_AlertManagerFault" 12 "a012_CPUReset" 6 "a006_CANTX_cyclicError" 5 "a005_CANTXError" 3 "a003_SWAssertion" 2 "a002_PowerLossReset" 1 "a001_WatchdogReset" 0 "ALERT_DO_NOT_USE_ZERO" ;
VAL_ 1358 VCBATT2_alertState 1 "SET" 0 "CLEARED" ;
VAL_ 1358 VCBATT2_a181_vehicleState 3 "DRIVE" 2 "ACCESSORY" 1 "CONDITIONING" 0 "OFF" ;
VAL_ 1358 VCBATT2_a188_sleepShutdownStep 3 "SNA" 2 "DONE" 1 "TURN_OFF_SILENT_WAKE_FEED" 0 "FRONTPRIV_ASLEEP" ;
VAL_ 1358 VCBATT2_a188_vehiclePowerState 16 "RESET" 15 "LOW_POWER_STANDBY" 14 "SLEEP_SHUTDOWN" 13 "GO_QUIET" 12 "LV_SHUTDOWN" 11 "JUMP_START" 10 "LV_ON" 9 "SYSTEM_CHECKS" 8 "TURN_ON_LV" 7 "WAIT_FOR_HIGH_POWER" 6 "OTA" 5 "DRIVE" 4 "ACCESSORY_PLUS" 3 "ACCESSORY" 2 "CONDITIONING" 1 "LOW_POWER_AWAKE" 0 "INIT" ;
VAL_ 1358 VCBATT2_a192_vehiclePowerState 3 "DRIVE" 2 "ACCESSORY" 1 "CONDITIONING" 0 "OFF" ;
VAL_ 1358 VCBATT2_a192_hvState 6 "UP" 5 "UP_FOR_DC_CHARGE" 4 "UP_FOR_CHARGE" 3 "UP_FOR_DRIVE" 2 "GOING_DOWN" 1 "COMING_UP" 0 "DOWN" ;
VAL_ 1358 VCBATT2_a192_DI_gear 7 "SNA" 4 "D" 3 "N" 2 "R" 1 "P" 0 "INVALID" ;
VAL_ 1358 VCBATT2_a227_selfTestResult 7 "PASSED" 6 "UNKNOWN" 5 "OPEN_PHASE_W" 4 "OPEN_PHASE_V" 3 "OPEN_PHASE_U" 2 "SHORT_GROUND" 1 "SHORT_SUPPLY" 0 "NOT_TESTED" ;
VAL_ 1358 VCBATT2_a300_oldType 3 "UNKOWN" 1 "KEBODA" 0 "PMDM" ;
VAL_ 1358 VCBATT2_a300_newType 3 "UNKOWN" 1 "KEBODA" 0 "PMDM" ;
VAL_ 1358 VCBATT2_a303_lockStatus 2 "LOCKED" 1 "UNLOCKED" 0 "SNA" ;
VAL_ 1358 VCBATT2_a309_lockStatus 2 "LOCKED" 1 "UNLOCKED" 0 "SNA" ;
VAL_ 1358 VCBATT2_a353_ambientTemperature 0 "SNA" ;
VAL_ 1358 VCBATT2_a354_ambientTemperature 0 "SNA" ;
VAL_ 1358 VCBATT2_a389_latchStatus 8 "FAULT" 7 "DEFAULT" 6 "TIMEOUT" 5 "AJAR" 4 "OPENING" 3 "CLOSING" 2 "CLOSED" 1 "OPENED" 0 "SNA" ;
VAL_ 1358 VCBATT2_a548_vehiclePowerState 3 "DRIVE" 2 "ACCESSORY" 1 "CONDITIONING" 0 "OFF" ;
VAL_ 1358 VCBATT2_a548_DI_gear 7 "SNA" 4 "D" 3 "N" 2 "R" 1 "P" 0 "INVALID" ;
VAL_ 1358 VCBATT2_a548_hvState 6 "UP" 5 "UP_FOR_DC_CHARGE" 4 "UP_FOR_CHARGE" 3 "UP_FOR_DRIVE" 2 "GOING_DOWN" 1 "COMING_UP" 0 "DOWN" ;
VAL_ 1358 VCBATT2_a610_switch1State 3 "FAULT" 2 "ON" 1 "OFF" 0 "SNA" ;
VAL_ 1358 VCBATT2_a610_switch2State 3 "FAULT" 2 "ON" 1 "OFF" 0 "SNA" ;
VAL_ 1358 VCBATT2_a610_temperature 0 "SNA" ;
VAL_ 1358 VCBATT2_a668_hcmRegionAndSide 6 "ECE_RHD_RIGHT" 5 "ECE_RHD_LEFT" 4 "ECE_LHD_RIGHT" 3 "ECE_LHD_LEFT" 2 "SAE_RIGHT" 1 "SAE_LEFT" 0 "SNA" ;
VAL_ 1358 VCBATT2_a668_homologationRegionO 2 "MX_UNECE" 1 "KR_UNECE" 0 "DEFAULT_FOR_COUNTRY_CODE" ;
VAL_ 1358 VCBATT2_a698_calibratedVerticalP 1023 "SNA" 1022 "INVALID_POSITION" ;
VAL_ 1358 VCBATT2_a698_calibratedHorizonta 1023 "SNA" 1022 "INVALID_POSITION" ;
VAL_ 975 VCBATT2_matrixIndex 11 "AlertMatrix11" 10 "AlertMatrix10" 9 "AlertMatrix9" 8 "AlertMatrix8" 7 "AlertMatrix7" 6 "AlertMatrix6" 5 "AlertMatrix5" 4 "AlertMatrix4" 3 "AlertMatrix3" 2 "AlertMatrix2" 1 "AlertMatrix1" 0 "AlertMatrix0" ;
VAL_ 1399 VCBATT2_vehiclePowerStateDBG 16 "VEHICLE_POWER_STATE_DBG_RESET" 15 "VEHICLE_POWER_STATE_DBG_LOW_POWER_STANDBY" 14 "VEHICLE_POWER_STATE_DBG_SLEEP_SHUTDOWN" 13 "VEHICLE_POWER_STATE_DBG_GO_QUIET" 12 "VEHICLE_POWER_STATE_DBG_LV_SHUTDOWN" 11 "VEHICLE_POWER_STATE_DBG_JUMP_START" 10 "VEHICLE_POWER_STATE_DBG_LV_ON" 9 "VEHICLE_POWER_STATE_DBG_SYSTEM_CHECKS" 8 "VEHICLE_POWER_STATE_DBG_TURN_ON_LV" 7 "VEHICLE_POWER_STATE_DBG_WAIT_FOR_HIGH_POWER" 6 "VEHICLE_POWER_STATE_DBG_OTA" 5 "VEHICLE_POWER_STATE_DBG_DRIVE" 4 "VEHICLE_POWER_STATE_DBG_ACCESSORY_PLUS" 3 "VEHICLE_POWER_STATE_DBG_ACCESSORY" 2 "VEHICLE_POWER_STATE_DBG_CONDITIONING" 1 "VEHICLE_POWER_STATE_DBG_LOW_POWER_AWAKE" 0 "VEHICLE_POWER_STATE_DBG_INIT" ;
VAL_ 1399 VCBATT2_nmWakeUpReasonDBG 32 "VCBATT_WAKEUP_REASON_UNKNOWN" 24 "VCBATT_WAKEUP_REASON_LV_BATTERY_IMPEDANCE_TEST" 23 "VCBATT_WAKEUP_REASON_LV_BATTERY_CAPACITY_TEST" 22 "VCBATT_WAKEUP_REASON_PERSIST_ACC_PORT_POWER" 21 "VCBATT_WAKEUP_REASON_FRONTPRIV" 20 "VCBATT_WAKEUP_REASON_LIN_3" 19 "VCBATT_WAKEUP_REASON_HW_PROT_SELF_TESTS" 18 "VCBATT_WAKEUP_REASON_EPAS_EFUSE" 17 "VCBATT_WAKEUP_REASON_VCLEFT_EFUSE" 16 "VCBATT_WAKEUP_REASON_AUTOPILOT_EFUSE" 15 "VCBATT_WAKEUP_REASON_LVBMB" 14 "VCBATT_WAKEUP_REASON_FRUNK_EMERGENCY_RELEASE" 13 "VCBATT_WAKEUP_REASON_PARTY_BDY_CAN" 12 "VCBATT_WAKEUP_REASON_VEH_CAN" 11 "VCBATT_WAKEUP_REASON_IPC_CAN" 10 "VCBATT_WAKEUP_REASON_FRUNK_LATCH_SWITCH" 9 "VCBATT_WAKEUP_REASON_FRUNK_ACCESS_POST_MONITOR" 8 "VCBATT_WAKEUP_REASON_FRUNK_ACCESS_POST" 7 "VCBATT_WAKEUP_REASON_TRUNK_EXTERIOR_SWITCH" 6 "VCBATT_WAKEUP_REASON_LIN" 5 "VCBATT_WAKEUP_REASON_CAN" 4 "VCBATT_WAKEUP_REASON_12V_SUPPORT_REQUIRED" 3 "VCBATT_WAKEUP_REASON_HIGH_SLEEP_CURRENT" 2 "VCBATT_WAKEUP_REASON_POWER_ON_RESET" 1 "VCBATT_WAKEUP_REASON_RESET" 0 "VCBATT_WAKEUP_REASON_NONE" ;
VAL_ 1399 VCBATT2_nmKeepAwakeReasonDBG 15 "VCBATT_KEEPAWAKE_REASON_MULTIPLE" 13 "VCBATT_KEEPAWAKE_REASON_PERSIST_ACC_PORT_POWER" 12 "VCBATT_KEEPAWAKE_REASON_CLOSURE_SWITCH" 11 "VCBATT_KEEPAWAKE_REASON_HW_PROT_SELF_TESTS" 10 "VCBATT_KEEPAWAKE_REASON_HEADLAMP_CALIBRATION" 9 "VCBATT_KEEPAWAKE_REASON_CLOSURE_LATCH" 8 "VCBATT_KEEPAWAKE_REASON_FRUNK_ACCESS_POST" 7 "VCBATT_KEEPAWAKE_REASON_FRUNK_LIGHT" 6 "VCBATT_KEEPAWAKE_REASON_SLEEP_BYPASS_NOT_SUPPORTING" 5 "VCBATT_KEEPAWAKE_REASON_EXTERIOR_LIGHTS_ON" 4 "VCBATT_KEEPAWAKE_REASON_HIBERNATION_RECOVERY" 3 "VCBATT_KEEPAWAKE_REASON_LVBMS_PACK_TEMPERATURE_LOW" 2 "VCBATT_KEEPAWAKE_REASON_UDS_ACTIVE" 1 "VCBATT_KEEPAWAKE_REASON_12V_SUPPORT_REQUIRED" 0 "VCBATT_KEEPAWAKE_REASON_NONE_SNA" ;
VAL_ 1399 VCBATT2_hibernationStateDBG 5 "VC_HIBERNATION_STATE_PREP" 4 "VC_HIBERNATION_STATE_EXIT" 3 "VC_HIBERNATION_STATE_RECOVERY" 2 "VC_HIBERNATION_STATE_ACTIVE" 1 "VC_HIBERNATION_STATE_NOT_ACTIVE" 0 "VC_HIBERNATION_STATE_INIT" ;
VAL_ 945 VCBATT_LVHealthStatus 6 "POWER_SUPPLY_COMPROMISED" 5 "ENERGY_RESERVE_CRITICAL" 4 "ENERGY_RESERVE_COMPROMISED" 3 "BACKUP_COMPROMISED" 2 "LATENT_FAULT" 1 "HEALTHY_LIMITED" 0 "DOMAIN_HEALTHY" ;
VAL_ 945 VCBATT_LVStatusForDrive 6 "STATUS_FOR_DRIVE_ACTIVE_DECEL" 5 "STATUS_FOR_DRIVE_PULL_TO_SHOULDER" 4 "STATUS_FOR_DRIVE_LIMP" 3 "STATUS_FOR_DRIVE_RETURN_TO_SERVICE" 2 "STATUS_FOR_DRIVE_READY_LIMITED" 1 "STATUS_FOR_DRIVE_READY" 0 "STATUS_FOR_DRIVE_NOT_READY" ;
VAL_ 945 VCBATT_LVPowerSecondsToSafeHarbo 65535 "INDEFINITE" ;
VAL_ 945 VCBATT_autonomyBehavior 2 "DRIVERLESS_NO_TAKEOVER" 1 "DRIVERLESS_TAKEOVER" 0 "DRIVER" ;
VAL_ 945 VCBATT_12vStatusForDrive 2 "EXIT_DRIVE_REQUESTED_12V" 1 "READY_FOR_DRIVE_12V" 0 "NOT_READY_FOR_DRIVE_12V" ;
VAL_ 1090 VCBATT_pcsInterfaceMuxIndex 1 "1" 0 "0" ;
VAL_ 1090 VCBATT_pcsResistanceFiltered 65535 "SNA" ;
VAL_ 1994 VCCC_infoIndex 255 "END" 41 "SUBCOMPONENT14" 40 "SUBCOMPONENT13" 39 "SUBCOMPONENT12" 38 "SUBCOMPONENT11" 37 "SUBCOMPONENT10" 36 "SUBCOMPONENT9" 35 "SUBCOMPONENT8" 34 "SUBCOMPONENT7" 33 "SUBCOMPONENT6" 32 "SUBCOMPONENT5" 31 "SUBCOMPONENT4" 24 "SUBCOMPONENT3" 23 "SUBCOMPONENT2" 20 "UDS_PROTOCOL_BOOTCRC" 19 "VERSION_DEPRECATED" 18 "BOOTLOADER_GITHASH" 17 "APP_GITHASH" 16 "SUBCOMPONENT1" 15 "BOOTLOADER_CRC" 14 "BOOTLOADER_SVN" 13 "APP_CRC" 11 "PCBAID_ASSYID_USAGEID" 10 "BUILD_HWID_COMPONENTID" 9 "DEPRECATED_9" 8 "DEPRECATED_8" 7 "DEPRECATED_7" 6 "DEPRECATED_6" 5 "DEPRECATED_5" 4 "DEPRECATED_4" 3 "DEPRECATED_3" 2 "DEPRECATED_2" 1 "DEPRECATED_1" 0 "DEPRECATED_0" ;
VAL_ 1994 VCCC_infoBuildType 4 "INFO_MFG_BUILD" 3 "INFO_TRACEABLE_CI_BUILD" 2 "INFO_LOCAL_BUILD" 1 "INFO_PLATFORM_BUILD" 0 "INFO_UNKNOWN_BUILD" ;
VAL_ 1994 VCCC_infoAssemblyId 255 "ASSEMBLY_SNA" 1 "ASSEMBLY1" ;
